VERSION "dbc-export 1 2026.26.6.5"

NS_ :

BS_:

BU_: APP BMS CC CMP CMPD CP DAS DI DIF DIR EPBL EPBR EVSE FC GTW HCML HCMR HVP ICR PCS PCS2 PM PMF PMR PTC SCCM SDCR TAS UMC V2G VC VCBATT VCBATT1 VCBATT2 VCFRONT VCFRONT1 VCLEFT VCRIGHT VCSEC

BO_ 769 VCFRONT_info: 8 VCFRONT
 SG_ VCFRONT_infoIndex M : 0|8@1+ (1,0) [0|255] "" Vector__XXX
 SG_ VCFRONT_infoBuildType m10 : 8|3@1+ (1,0) [0|7] "" Vector__XXX
 SG_ VCFRONT_infoBuildConfigId m10 : 16|16@1+ (1,0) [0|65535] "" Vector__XXX
 SG_ VCFRONT_infoHardwareId m10 : 32|16@1+ (1,0) [0|65535] "" Vector__XXX
 SG_ VCFRONT_infoComponentId m10 : 48|16@1+ (1,0) [0|65535] "" Vector__XXX
 SG_ VCFRONT_infoPcbaId m11 : 8|8@1+ (1,0) [0|255] "" Vector__XXX
 SG_ VCFRONT_infoAssemblyId m11 : 16|8@1+ (1,0) [0|254] "" Vector__XXX
 SG_ VCFRONT_infoUsageId m11 : 24|16@1+ (1,0) [0|65535] "" Vector__XXX
 SG_ VCFRONT_infoSubUsageId m11 : 40|16@1+ (1,0) [0|65535] "" Vector__XXX
 SG_ VCFRONT_infoAppCrc m13 : 8|32@1+ (1,0) [0|4294967295] "" Vector__XXX
 SG_ VC_infoHCMLAppCRC m16 : 32|32@1+ (1,0) [0|4294967295] "" Vector__XXX
 SG_ VCFRONT_infoAppGitHash m17 : 8|56@1+ (1,0) [0|7.20575940379e+16] "" Vector__XXX
 SG_ VCFRONT_infoBootGitHash m18 : 8|56@1+ (1,0) [0|7.20575940379e+16] "" Vector__XXX
 SG_ VCFRONT_infoPlatformType m19 : 8|8@1+ (1,0) [0|255] "" Vector__XXX
 SG_ VCFRONT_infoBootUdsProtoVersion m20 : 8|16@1+ (1,0) [0|65535] "" Vector__XXX
 SG_ VCFRONT_infoBootCrc m20 : 24|32@1+ (1,0) [0|4294967295] "" Vector__XXX
 SG_ VC_infoHCMRAppCRC m23 : 32|32@1+ (1,0) [0|4294967295] "" Vector__XXX
 SG_ VC_infoWiperAppCRC m31 : 32|32@1+ (1,0) [0|4294967295] "" Vector__XXX

BO_ 1014 VCFRONT_lightStatus: 8 VCFRONT
 SG_ VCFRONT_lowBeamLeftStatus : 0|2@1+ (1,0) [0|2] "" Vector__XXX
 SG_ VCFRONT_lowBeamRightStatus : 2|2@1+ (1,0) [0|2] "" Vector__XXX
 SG_ VCFRONT_highBeamLeftStatus : 4|2@1+ (1,0) [0|2] "" Vector__XXX
 SG_ VCFRONT_highBeamRightStatus : 6|2@1+ (1,0) [0|2] "" Vector__XXX
 SG_ VCFRONT_DRLLeftStatus : 8|2@1+ (1,0) [0|2] "" Vector__XXX
 SG_ VCFRONT_DRLRightStatus : 10|2@1+ (1,0) [0|2] "" Vector__XXX
 SG_ VCFRONT_fogLeftStatus : 12|2@1+ (1,0) [0|2] "" Vector__XXX
 SG_ VCFRONT_fogRightStatus : 14|2@1+ (1,0) [0|2] "" Vector__XXX
 SG_ VCFRONT_sideMarkersStatus : 16|2@1+ (1,0) [0|2] "" Vector__XXX
 SG_ VCFRONT_sideRepeaterLeftStatus : 18|2@1+ (1,0) [0|2] "" Vector__XXX
 SG_ VCFRONT_sideRepeaterRightStatus : 20|2@1+ (1,0) [0|2] "" Vector__XXX
 SG_ VCFRONT_turnSignalLeftStatus : 22|2@1+ (1,0) [0|2] "" Vector__XXX
 SG_ VCFRONT_turnSignalRightStatus : 24|2@1+ (1,0) [0|2] "" Vector__XXX
 SG_ VCFRONT_parkLeftStatus : 26|2@1+ (1,0) [0|2] "" Vector__XXX
 SG_ VCFRONT_parkRightStatus : 28|2@1+ (1,0) [0|2] "" Vector__XXX
 SG_ VCFRONT_lowBeamLeftReadyForAimin : 30|1@1+ (1,0) [0|1] "" Vector__XXX
 SG_ VCFRONT_lowBeamRightReadyForAimi : 31|1@1+ (1,0) [0|1] "" Vector__XXX
 SG_ VCFRONT_lowBeamsOnForDRL : 32|1@1+ (1,0) [0|1] "" Vector__XXX
 SG_ VC_rightHeadlampHealth : 33|3@1+ (1,0) [0|7] "" Vector__XXX
 SG_ VC_leftHeadlampHealth : 36|3@1+ (1,0) [0|7] "" Vector__XXX
 SG_ VCFRONT_lightStatusMuxIndex M : 39|3@1+ (1,0) [0|7] "" Vector__XXX
 SG_ VCFRONT_isAdaptiveHighBeamAvaila m1 : 42|1@1+ (1,0) [0|1] "" Vector__XXX
 SG_ VCFRONT_isAdaptiveHighBeamFaulte m1 : 43|1@1+ (1,0) [0|1] "" Vector__XXX
 SG_ VCFRONT_isBendLightingAvailable m1 : 44|1@1+ (1,0) [0|1] "" Vector__XXX
 SG_ VCFRONT_advancedDrivingBeamStatu m1 : 45|2@1+ (1,0) [0|3] "" Vector__XXX
 SG_ VCFRONT_headlampBendAngle m1 : 47|8@1- (0.1,0) [-12.7|12.7] "deg" Vector__XXX
 SG_ VCFRONT_headlampRoadClass m1 : 55|2@1+ (1,0) [0|3] "" Vector__XXX

BO_ 1013 VCFRONT_lighting: 8 VCFRONT
 SG_ VCFRONT_indicatorLeftRequest : 0|2@1+ (1,0) [0|3] "" Vector__XXX
 SG_ VCFRONT_indicatorRightRequest : 2|2@1+ (1,0) [0|3] "" Vector__XXX
 SG_ VCFRONT_hazardLightRequest : 4|4@1+ (1,0) [0|15] "" Vector__XXX
 SG_ VCFRONT_ambientLightingBrightnes : 8|8@1+ (0.5,0) [0|127] "%" Vector__XXX
 SG_ VCFRONT_switchLightingBrightness : 16|8@1+ (0.5,0) [0|127] "%" Vector__XXX
 SG_ VCFRONT_courtesyLightingRequest : 24|1@1+ (1,0) [0|1] "" Vector__XXX
 SG_ VCFRONT_hazardSwitchBacklight : 27|1@1+ (1,0) [0|1] "" Vector__XXX
 SG_ VCFRONT_highBeamControlState : 28|2@1+ (1,0) [0|3] "" Vector__XXX
 SG_ VCFRONT_dynamicBrakeLightState : 30|2@1+ (1,0) [0|3] "" Vector__XXX
 SG_ VCFRONT_lightingCoreState : 32|4@1+ (1,0) [0|14] "" Vector__XXX
 SG_ VCFRONT_intHighBeamsFunctionStat : 36|1@1+ (1,0) [0|1] "" Vector__XXX
 SG_ VCFRONT_latchedHighBeamsFunction : 37|1@1+ (1,0) [0|1] "" Vector__XXX
 SG_ VCFRONT_frontFogFunctionState : 38|1@1+ (1,0) [0|1] "" Vector__XXX
 SG_ VCFRONT_headlightsReadyOrTimedOu : 39|1@1+ (1,0) [0|1] "" Vector__XXX
 SG_ VCFRONT_turnIndicatorStalk : 40|2@1+ (1,0) [0|2] "" Vector__XXX
 SG_ VCFRONT_highBeamLatchingState : 42|2@1+ (1,0) [1|3] "" Vector__XXX
 SG_ VCFRONT_lightingCustomState : 44|5@1+ (1,0) [0|31] "" Vector__XXX
 SG_ VC_fastFlashHazardsActive : 49|1@1+ (1,0) [0|1] "" Vector__XXX
 SG_ VCFRONT_indicatorLeftInternal : 50|2@1+ (1,0) [0|3] "" Vector__XXX
 SG_ VCFRONT_indicatorRightInternal : 52|2@1+ (1,0) [0|3] "" Vector__XXX

BO_ 1801 VCFRONT_logging0point1Hz: 8 VCFRONT
 SG_ VCFRONT_logging0point1HzIndex M : 0|6@1+ (1,0) [0|63] "" Vector__XXX
 SG_ VC_hcmlFactoryOfOrigin m26 : 6|2@1+ (1,0) [0|3] "" Vector__XXX
 SG_ VC_hcmlHellaPartNumberStatus m26 : 8|1@1+ (1,0) [0|1] "" Vector__XXX
 SG_ VC_hcmlHellaPartNumber m26 : 9|32@1+ (1,0) [0|4294967295] "-" Vector__XXX
 SG_ VC_hcmlCurrentBinMappingType m26 : 41|2@1+ (1,0) [0|3] "" Vector__XXX
 SG_ VC_hcmlCurrentBin0Value m26 : 43|3@1+ (1,0) [1|7] "" Vector__XXX
 SG_ VC_hcmlCurrentBin1Value m26 : 46|3@1+ (1,0) [1|7] "" Vector__XXX
 SG_ VC_hcmlCurrentBin2Value m26 : 49|3@1+ (1,0) [1|7] "" Vector__XXX
 SG_ VC_hcmlCurrentBin3Value m26 : 52|3@1+ (1,0) [1|7] "" Vector__XXX
 SG_ VC_hcmlCurrentBin4Value m26 : 55|3@1+ (1,0) [1|7] "" Vector__XXX
 SG_ VC_hcmlCurrentBin5Value m26 : 58|3@1+ (1,0) [1|7] "" Vector__XXX
 SG_ VC_hcmlRegionAndSide m26 : 61|3@1+ (1,0) [1|7] "" Vector__XXX
 SG_ VC_hcmrFactoryOfOrigin m27 : 6|2@1+ (1,0) [0|3] "" Vector__XXX
 SG_ VC_hcmrHellaPartNumberStatus m27 : 8|1@1+ (1,0) [0|1] "" Vector__XXX
 SG_ VC_hcmrHellaPartNumber m27 : 9|32@1+ (1,0) [0|4294967295] "-" Vector__XXX
 SG_ VC_hcmrCurrentBinMappingType m27 : 41|2@1+ (1,0) [0|3] "" Vector__XXX
 SG_ VC_hcmrCurrentBin0Value m27 : 43|3@1+ (1,0) [1|7] "" Vector__XXX
 SG_ VC_hcmrCurrentBin1Value m27 : 46|3@1+ (1,0) [1|7] "" Vector__XXX
 SG_ VC_hcmrCurrentBin2Value m27 : 49|3@1+ (1,0) [1|7] "" Vector__XXX
 SG_ VC_hcmrCurrentBin3Value m27 : 52|3@1+ (1,0) [1|7] "" Vector__XXX
 SG_ VC_hcmrCurrentBin4Value m27 : 55|3@1+ (1,0) [1|7] "" Vector__XXX
 SG_ VC_hcmrCurrentBin5Value m27 : 58|3@1+ (1,0) [1|7] "" Vector__XXX
 SG_ VC_hcmrRegionAndSide m27 : 61|3@1+ (1,0) [1|7] "" Vector__XXX

BO_ 705 VCFRONT_logging10Hz: 8 VCFRONT
 SG_ VCFRONT_logging10HzIndex M : 0|3@1+ (1,0) [0|7] "" Vector__XXX
 SG_ VCFRONT_pumpBatteryOutVoltage m0 : 3|7@1+ (0.2,0) [0|20] "V" Vector__XXX
 SG_ VCFRONT_pumpPowertrainOutVoltage m0 : 10|7@1+ (0.2,0) [0|20] "V" Vector__XXX
 SG_ VCFRONT_pumpBatteryInitd m0 : 17|1@1+ (1,0) [0|1] "" Vector__XXX
 SG_ VCFRONT_pumpPowertrainInitd m0 : 18|1@1+ (1,0) [0|1] "" Vector__XXX
 SG_ VCFRONT_pumpBatteryEnabled m0 : 19|1@1+ (1,0) [0|1] "" Vector__XXX
 SG_ VCFRONT_pumpPowertrainEnabled m0 : 20|1@1+ (1,0) [0|1] "" Vector__XXX
 SG_ VCFRONT_pumpBatteryPowerOn m0 : 21|1@1+ (1,0) [0|1] "" Vector__XXX
 SG_ VCFRONT_pumpPowertrainPowerOn m0 : 22|1@1+ (1,0) [0|1] "" Vector__XXX
 SG_ VCFRONT_pumpsWake m0 : 23|1@1+ (1,0) [0|1] "" Vector__XXX
 SG_ VCFRONT_pumpBatSpiError m0 : 24|1@1+ (1,0) [0|1] "" Vector__XXX
 SG_ VCFRONT_pumpPtSpiError m0 : 25|1@1+ (1,0) [0|1] "" Vector__XXX
 SG_ VCFRONT_coolantFlowChillerActual m0 : 26|8@1+ (0.1,0) [0|25] "LPM" Vector__XXX
 SG_ VCFRONT_radiatorFanOutVoltage m0 : 34|7@1+ (0.2,0) [0|20] "V" Vector__XXX
 SG_ VCFRONT_radiatorFanInitd m0 : 41|1@1+ (1,0) [0|1] "" Vector__XXX
 SG_ VCFRONT_radiatorFanEnabled m0 : 42|1@1+ (1,0) [0|1] "" Vector__XXX
 SG_ VCFRONT_radiatorFanPowerOn m0 : 43|1@1+ (1,0) [0|1] "" Vector__XXX
 SG_ VCFRONT_radiatorFanPhaseCurrent m0 : 44|8@1+ (0.25,-10) [-10|50] "A" Vector__XXX
 SG_ VCFRONT_radiatorFanPhaseIMax m0 : 52|7@1+ (0.25,5) [5|35] "A" Vector__XXX
 SG_ VCFRONT_thmlFanSpiError m0 : 59|1@1+ (1,0) [0|1] "" Vector__XXX
 SG_ VCFRONT_chargeTrapNominalCOP1Bat m0 : 60|1@1+ (1,0) [0|1] "" Vector__XXX
 SG_ VCFRONT_chargeTrapNominalCOP1Chi m0 : 61|1@1+ (1,0) [0|1] "" Vector__XXX
 SG_ VCFRONT_COP1OilWarmingNeeded m0 : 62|1@1+ (1,0) [0|1] "" Vector__XXX

BO_ 897 VCFRONT_logging1Hz: 8 VCFRONT
 SG_ VCFRONT_logging1HzIndex M : 0|5@1+ (1,0) [0|31] "" Vector__XXX
 SG_ VCFRONT_modeTransitionID m0 : 5|6@1+ (1,0) [0|63] "" Vector__XXX
 SG_ VCFRONT_modeDesired m0 : 11|2@1+ (1,0) [0|3] "" Vector__XXX
 SG_ VCFRONT_targetPTActiveCool m0 : 13|7@1+ (1,0) [0|100] "degC" Vector__XXX
 SG_ VCFRONT_targetPtOptionalActiveCo m0 : 20|7@1+ (1,0) [0|100] "degC" Vector__XXX
 SG_ VCFRONT_targetPTPassive m0 : 27|7@1+ (1,-20) [-20|80] "degC" Vector__XXX
 SG_ VCFRONT_targetBatActiveCool m0 : 34|7@1+ (1,0) [0|100] "degC" Vector__XXX
 SG_ VCFRONT_targetBatOptionalActiveC m0 : 41|7@1+ (1,0) [0|100] "degC" Vector__XXX
 SG_ VCFRONT_targetBatPassive m0 : 48|7@1+ (1,-20) [-20|80] "degC" Vector__XXX
 SG_ VCFRONT_targetBatActiveHeat m0 : 55|7@1+ (1,-40) [-40|60] "degC" Vector__XXX
 SG_ VCFRONT_condenserPressureLimit m1 : 5|6@1+ (0.16,10) [10|20] "bar" Vector__XXX
 SG_ VCFRONT_fanDemandCondenser m1 : 11|7@1+ (1,0) [0|100] "%" Vector__XXX
 SG_ VCFRONT_fanDemandRadiator m1 : 18|7@1+ (1,0) [0|100] "%" Vector__XXX
 SG_ VCFRONT_tempRefrigSuction m1 : 25|8@1+ (0.5,-40) [-40|85] "degC" Vector__XXX
 SG_ VCFRONT_pumpBatteryFETTemp m1 : 33|8@1+ (1,-40) [-40|150] "degC" Vector__XXX
 SG_ VCFRONT_pumpPowertrainFETTemp m1 : 41|8@1+ (1,-40) [-40|150] "degC" Vector__XXX
 SG_ VCFRONT_radiatorFanFETTemp m1 : 49|8@1+ (1,-40) [-40|150] "degC" Vector__XXX
 SG_ VCFRONT_radiatorFanRunReason m1 : 57|4@1+ (1,0) [0|15] "" Vector__XXX
 SG_ VCFRONT_coolantValveModeWrong m1 : 61|1@1+ (1,0) [0|1] "" Vector__XXX
 SG_ VCFRONT_coolantTempBasedMode m1 : 62|2@1+ (1,0) [0|3] "" Vector__XXX
 SG_ VCFRONT_coolantValveRecalReason m2 : 5|3@1+ (1,0) [0|7] "" Vector__XXX
 SG_ VCFRONT_coolantValveCountRange m2 : 8|10@1+ (1,375) [375|1375] "ticks" Vector__XXX
 SG_ VCFRONT_coolantValveAngleDrift m2 : 18|10@1+ (0.25,-127) [-127|127] "degrees" Vector__XXX
 SG_ VCFRONT_coolantValveRecalCount m2 : 28|16@1+ (1,0) [0|65535] "" Vector__XXX
 SG_ VCFRONT_coolantValveWindupEst m2 : 44|6@1+ (2,0) [0|126] "ticks" Vector__XXX
 SG_ VCFRONT_coolantValveRadBypass m2 : 50|7@1+ (1,0) [0|100] "%" Vector__XXX
 SG_ VCFRONT_usingModeledPs m2 : 57|1@1+ (1,0) [0|1] "" Vector__XXX
 SG_ VCFRONT_usingModeledPd m2 : 58|1@1+ (1,0) [0|1] "" Vector__XXX
 SG_ VCFRONT_usingModeledPl m2 : 59|1@1+ (1,0) [0|1] "" Vector__XXX
 SG_ VCFRONT_usingModeledTs m2 : 60|1@1+ (1,0) [0|1] "" Vector__XXX
 SG_ VCFRONT_usingModeledTd m2 : 61|1@1+ (1,0) [0|1] "" Vector__XXX
 SG_ VCFRONT_usingModeledTl m2 : 62|1@1+ (1,0) [0|1] "" Vector__XXX
 SG_ VCFRONT_hpChargeCableType m5 : 5|2@1+ (1,0) [0|3] "" Vector__XXX
 SG_ VCFRONT_subcoolActual m5 : 8|7@1- (0.4,15.2) [-10|40] "degC" Vector__XXX
 SG_ VCFRONT_hpSubcoolTarget m5 : 16|5@1+ (1,0) [0|31] "degC" Vector__XXX
 SG_ VCFRONT_CMPDischargeSuperheat m5 : 21|5@1- (1,6) [-10|21] "degC" Vector__XXX
 SG_ VCFRONT_hpCOP m5 : 26|6@1+ (0.1,0) [0|6] "-" Vector__XXX
 SG_ VCFRONT_lowSideWattsLift m5 : 32|7@1+ (60,0) [0|7600] "W" Vector__XXX
 SG_ VCFRONT_tempSuperheatActual m5 : 39|10@1+ (0.1,-20) [-20|80] "degC" Vector__XXX
 SG_ VCFRONT_tempSuperheatTarget m5 : 49|10@1+ (0.1,0) [0|60] "degC" Vector__XXX
 SG_ VCFRONT_refrigerantHasBeenFilled m5 : 59|1@1+ (1,0) [0|1] "" Vector__XXX
 SG_ VCFRONT_refCommissionStatus m5 : 60|2@1+ (1,0) [0|3] "" Vector__XXX
 SG_ VCFRONT_LCCPurgeActive m5 : 62|1@1+ (1,0) [0|1] "" Vector__XXX
 SG_ VCFRONT_exteriorQuietModeEnabled m6 : 5|1@1+ (1,0) [0|1] "" Vector__XXX
 SG_ VCFRONT_exteriorQuietModeAllowed m6 : 6|1@1+ (1,0) [0|1] "" Vector__XXX
 SG_ VCFRONT_CCQdotFdFrwrdTarget m6 : 7|7@1+ (80,0) [0|10100] "W" Vector__XXX
 SG_ VCFRONT_CCQdotFdbk m6 : 14|7@1- (80,0) [-5000|5000] "W" Vector__XXX
 SG_ VCFRONT_CCQdotActual m6 : 21|7@1+ (80,0) [0|10100] "W" Vector__XXX
 SG_ VCFRONT_evapFdFrwrdTarget m6 : 28|7@1+ (80,0) [0|10100] "W" Vector__XXX
 SG_ VCFRONT_evapFdbk m6 : 35|7@1- (100,-3300) [-9700|3000] "W" Vector__XXX
 SG_ VCFRONT_DIQdotA m6 : 42|7@1+ (80,0) [0|10000] "W" Vector__XXX
 SG_ VCFRONT_evapFdFrwrdTargetMinimum m6 : 49|7@1+ (80,0) [0|10000] "W" Vector__XXX
 SG_ VCFRONT_passiveCoolingState m6 : 56|2@1+ (1,0) [0|3] "" Vector__XXX
 SG_ VCFRONT_totalLoadCoolingDominant m6 : 58|1@1+ (1,0) [0|1] "" Vector__XXX
 SG_ VCFRONT_feedfwdLoadCoolingDomina m6 : 59|1@1+ (1,0) [0|1] "" Vector__XXX
 SG_ VCFRONT_modelLoadCoolingDominant m6 : 60|1@1+ (1,0) [0|1] "" Vector__XXX
 SG_ VCFRONT_hpPotentialLowRefrig m6 : 61|1@1+ (1,0) [0|1] "" Vector__XXX
 SG_ VCFRONT_hpRefrigerantPurgeState m6 : 62|2@1+ (1,0) [0|3] "" Vector__XXX
 SG_ VCFRONT_estPressureLiq m7 : 5|6@1+ (0.5,0) [0|31] "bar" Vector__XXX
 SG_ VCFRONT_estPressureSuct m7 : 11|7@1+ (0.125,0) [0|11.5] "bar" Vector__XXX
 SG_ VCFRONT_estPressureDisch m7 : 18|7@1+ (0.25,0) [0|31.75] "bar" Vector__XXX
 SG_ VCFRONT_estTempLiq m7 : 25|8@1- (0.8,68.8) [-33|170] "degC" Vector__XXX
 SG_ VCFRONT_estTempSuct m7 : 33|6@1- (1,2) [-30|33] "degC" Vector__XXX
 SG_ VCFRONT_estTempDisch m7 : 39|7@1- (1.5,75) [-20|169] "degC" Vector__XXX
 SG_ VCFRONT_estCompressorRpm m7 : 46|9@1+ (30,0) [0|15000] "rpm" Vector__XXX
 SG_ VCFRONT_estQLift m7 : 55|6@1+ (100,0) [0|6300] "W" Vector__XXX
 SG_ VCFRONT_cycleModelConverged m7 : 61|1@1+ (1,0) [0|1] "" Vector__XXX
 SG_ VCFRONT_compStandbyCoastDownMode m7 : 62|1@1+ (1,0) [0|1] "" Vector__XXX
 SG_ VCFRONT_compStandbyShowroomMode m7 : 63|1@1+ (1,0) [0|1] "" Vector__XXX
 SG_ VCFRONT_chillerExvCalibOffset m8 : 5|5@1- (8,0) [-127|120] "ticks" Vector__XXX
 SG_ VCFRONT_evapExvCalibOffset m8 : 10|5@1- (8,0) [-127|120] "ticks" Vector__XXX
 SG_ VCFRONT_recircExvCalibOffset m8 : 15|5@1- (8,0) [-127|120] "ticks" Vector__XXX
 SG_ VCFRONT_lccExvCalibOffset m8 : 20|5@1- (8,0) [-127|120] "ticks" Vector__XXX
 SG_ VCFRONT_ccLeftExvCalibOffset m8 : 25|5@1- (8,0) [-127|120] "ticks" Vector__XXX
 SG_ VCFRONT_ccRightExvCalibOffset m8 : 30|5@1- (8,0) [-127|120] "ticks" Vector__XXX
 SG_ VCFRONT_chillerEXVControlState m8 : 35|3@1+ (1,0) [0|7] "" Vector__XXX
 SG_ VCFRONT_evapEXVControlState m8 : 38|3@1+ (1,0) [0|7] "" Vector__XXX
 SG_ VCFRONT_recircEXVControlState m8 : 41|3@1+ (1,0) [0|7] "" Vector__XXX
 SG_ VCFRONT_lccEXVControlState m8 : 44|3@1+ (1,0) [0|7] "" Vector__XXX
 SG_ VCFRONT_cclEXVControlState m8 : 47|3@1+ (1,0) [0|7] "" Vector__XXX
 SG_ VCFRONT_ccrEXVControlState m8 : 50|3@1+ (1,0) [0|7] "" Vector__XXX
 SG_ VCFRONT_chillerExvCalibFailed m8 : 53|1@1+ (1,0) [0|1] "" Vector__XXX
 SG_ VCFRONT_evapExvCalibFailed m8 : 54|1@1+ (1,0) [0|1] "" Vector__XXX
 SG_ VCFRONT_recircExvCalibFailed m8 : 55|1@1+ (1,0) [0|1] "" Vector__XXX
 SG_ VCFRONT_lccExvCalibFailed m8 : 56|1@1+ (1,0) [0|1] "" Vector__XXX
 SG_ VCFRONT_ccLeftExvCalibFailed m8 : 57|1@1+ (1,0) [0|1] "" Vector__XXX
 SG_ VCFRONT_ccRightExvCalibFailed m8 : 58|1@1+ (1,0) [0|1] "" Vector__XXX
 SG_ VCFRONT_ambientTempSniffActive m8 : 59|1@1+ (1,0) [0|1] "" Vector__XXX
 SG_ VCFRONT_ambientTempPassiveSniffi m8 : 60|1@1+ (1,0) [0|1] "" Vector__XXX
 SG_ VCFRONT_ambientTempRadSampling m8 : 61|1@1+ (1,0) [0|1] "" Vector__XXX
 SG_ VCFRONT_ambientTempSpeedSampling m8 : 62|1@1+ (1,0) [0|1] "" Vector__XXX
 SG_ VCFRONT_feedFwdMDotEvaporator m12 : 5|8@1+ (0.005,0) [0|1] "-" Vector__XXX
 SG_ VCFRONT_hpCabinHeatBatteryHeatAm m12 : 13|1@1+ (1,0) [0|1] "" Vector__XXX
 SG_ VCFRONT_hpCabinHeatBatteryHeatCO m12 : 14|1@1+ (1,0) [0|1] "" Vector__XXX
 SG_ VCFRONT_feedFwdMDotCabinCondense m12 : 15|8@1+ (0.005,0) [0|1] "-" Vector__XXX
 SG_ VCFRONT_feedBackEvapTempControll m12 : 23|7@1+ (0.01,-0.5) [-0.5|0.5] "-" Vector__XXX
 SG_ VCFRONT_feedBackDuctTempControll m12 : 30|8@1+ (0.01,-1) [-1|1] "-" Vector__XXX
 SG_ VCFRONT_isSolenoidAllowed m12 : 38|1@1+ (1,0) [0|1] "" Vector__XXX
 SG_ VCFRONT_maxChillerCoolingPower m12 : 39|8@1+ (100,0) [0|20000] "W" Vector__XXX
 SG_ VCFRONT_fanControlRadCanCool m12 : 47|1@1+ (1,0) [0|1] "" Vector__XXX
 SG_ VCFRONT_fanControlFeedfwdActive m12 : 48|1@1+ (1,0) [0|1] "" Vector__XXX
 SG_ VCFRONT_fanControlRadiatorUa m12 : 49|7@1+ (8,0) [0|1000] "W/C" Vector__XXX
 SG_ VCFRONT_fanControlRadiatorInletT m12 : 56|6@1- (1.8,36) [-20|90] "C" Vector__XXX
 SG_ VCFRONT_hpASBatteryHeatingAllowe m14 : 5|1@1+ (1,0) [0|1] "" Vector__XXX
 SG_ VCFRONT_hpCOP1BatteryHeatingAllo m14 : 6|1@1+ (1,0) [0|1] "" Vector__XXX
 SG_ VCFRONT_hpCabinHeatScavengeOnly m14 : 7|1@1+ (1,0) [0|1] "" Vector__XXX
 SG_ VCFRONT_hpCabinHeatAmbientSource m14 : 8|1@1+ (1,0) [0|1] "" Vector__XXX
 SG_ VCFRONT_hpCabinHeatReheatScaveng m14 : 9|1@1+ (1,0) [0|1] "" Vector__XXX
 SG_ VCFRONT_hpCabinHeatReheatAmbient m14 : 10|1@1+ (1,0) [0|1] "" Vector__XXX
 SG_ VCFRONT_hpCabinHeatBlend m14 : 11|1@1+ (1,0) [0|1] "" Vector__XXX
 SG_ VCFRONT_hpCabinHeatCOP1 m14 : 12|1@1+ (1,0) [0|1] "" Vector__XXX
 SG_ VCFRONT_hpCabinHeatBatteryHeatRe m14 : 13|1@1+ (1,0) [0|1] "" Vector__XXX
 SG_ VCFRONT_hpCabinHeatBatteryCoolRe m14 : 14|1@1+ (1,0) [0|1] "" Vector__XXX
 SG_ VCFRONT_hpCabinCoolEvaporator m14 : 15|1@1+ (1,0) [0|1] "" Vector__XXX
 SG_ VCFRONT_hpCabinCoolEvaporatorReh m14 : 16|1@1+ (1,0) [0|1] "" Vector__XXX
 SG_ VCFRONT_hpBatteryHeatAmbientSour m14 : 17|1@1+ (1,0) [0|1] "" Vector__XXX
 SG_ VCFRONT_hpBatteryHeatCOP1 m14 : 18|1@1+ (1,0) [0|1] "" Vector__XXX
 SG_ VCFRONT_hpBatteryCool m14 : 19|1@1+ (1,0) [0|1] "" Vector__XXX
 SG_ VCFRONT_hpBatteryCoolCabinConden m14 : 20|1@1+ (1,0) [0|1] "" Vector__XXX
 SG_ VCFRONT_hpBatteryCoolCabinC_0001 m14 : 21|1@1+ (1,0) [0|1] "" Vector__XXX
 SG_ VCFRONT_hpBatteryCoolCabinReheat m14 : 22|1@1+ (1,0) [0|1] "" Vector__XXX
 SG_ VCFRONT_hpBatteryCoolEvaporator m14 : 23|1@1+ (1,0) [0|1] "" Vector__XXX
 SG_ VCFRONT_suctionSuperheatEstTsSNA m14 : 24|4@1+ (2,0) [0|30] "degC" Vector__XXX
 SG_ VCFRONT_tempRefrigSuctionEst m14 : 28|6@1- (1.2,7.2) [-25|37.2] "degC" Vector__XXX
 SG_ VCFRONT_hpBattOverTempHvacDisabl m14 : 34|1@1+ (1,0) [0|1] "" Vector__XXX
 SG_ VCFRONT_hpDiagLouverCalib m14 : 35|1@1+ (1,0) [0|1] "" Vector__XXX
 SG_ VCFRONT_hpDiagHighSideNotNominal m14 : 36|1@1+ (1,0) [0|1] "" Vector__XXX
 SG_ VCFRONT_hpForceModeRadClear m14 : 37|1@1+ (1,0) [0|1] "" Vector__XXX
 SG_ VCFRONT_estPressureDischargeSat m14 : 38|7@1+ (0.25,0) [0|31.75] "bar" Vector__XXX
 SG_ VCFRONT_tempRefrigLiquid m14 : 45|11@1+ (0.125,-40) [-40|150] "degC" Vector__XXX
 SG_ VCFRONT_totalBattHeatingPower m14 : 56|7@1+ (150,0) [0|19050] "W" Vector__XXX
 SG_ VCFRONT_hpPotentialFrozenRadiato m14 : 63|1@1+ (1,0) [0|1] "" Vector__XXX
 SG_ VCFRONT_passiveSeriesRegOn m16 : 5|1@1+ (1,0) [0|1] "" Vector__XXX
 SG_ VCFRONT_passiveDemandRadBypass m16 : 8|7@1+ (1,0) [0|100] "%" Vector__XXX
 SG_ VCFRONT_targetLccActiveCoolCap m16 : 16|7@1+ (1,0) [0|100] "degC" Vector__XXX
 SG_ VCFRONT_targetLccActiveCoolEff m16 : 23|7@1+ (1,0) [0|100] "degC" Vector__XXX
 SG_ VCFRONT_coolantValveDailyAngleTr m16 : 30|7@1+ (60,0) [0|7500] "degrees" Vector__XXX
 SG_ VCFRONT_dischargePressureLimit m16 : 37|7@1+ (0.25,0) [0|26] "bar" Vector__XXX
 SG_ VCFRONT_radMovementBlockActive m16 : 44|1@1+ (1,0) [0|1] "" Vector__XXX
 SG_ VCFRONT_radBypassMoveReason m16 : 45|4@1+ (1,0) [0|15] "" Vector__XXX
 SG_ VCFRONT_hpBattHeatingPower m16 : 49|7@1+ (100,0) [0|10000] "W" Vector__XXX
 SG_ VCFRONT_tempCoolantRadOutletEstS m16 : 56|2@1+ (1,0) [0|3] "" Vector__XXX
 SG_ VCFRONT_targetBatActiveCoolSourc m16 : 58|3@1+ (1,0) [0|7] "" Vector__XXX
 SG_ VCFRONT_targetPTActiveCoolSource m16 : 61|3@1+ (1,0) [0|7] "" Vector__XXX
 SG_ VCFRONT_hpColdStagnationLimit m17 : 8|7@1+ (1,-40) [-40|80] "degC" Vector__XXX
 SG_ VCFRONT_hpHotStagnationLimit m17 : 16|7@1+ (1,-40) [-40|80] "degC" Vector__XXX
 SG_ VCFRONT_hpCompFlowIndex m17 : 23|8@1+ (1,30) [30|255] "-" Vector__XXX
 SG_ VCFRONT_hpCompFlowIndexFiltered m17 : 31|8@1+ (1,30) [30|255] "-" Vector__XXX
 SG_ VCFRONT_subcoolEstTlSNA m17 : 39|6@1- (2,0) [-10|53] "degC" Vector__XXX
 SG_ VCFRONT_subcoolEstPlSNA m17 : 45|6@1- (2,0) [-10|53] "degC" Vector__XXX
 SG_ VCFRONT_tempRefrigLiquidEst m17 : 51|6@1+ (2,0) [0|125] "degC" Vector__XXX
 SG_ VCFRONT_pressureRefrigLiquidEst m17 : 57|6@1+ (0.5,0) [0|31] "bar" Vector__XXX
 SG_ VCFRONT_cmpIsentropicCheckPassed m17 : 63|1@1+ (1,0) [0|1] "" Vector__XXX
 SG_ VCFRONT_louverPosReason m18 : 5|4@1+ (1,0) [0|15] "" Vector__XXX
 SG_ VCFRONT_hpEnergyFlowIndex m18 : 9|8@1+ (4,0) [0|1020] "-" Vector__XXX
 SG_ VCFRONT_hpEnergyFlowIndexFiltere m18 : 17|8@1+ (4,0) [0|1020] "-" Vector__XXX
 SG_ VCFRONT_ductLeftAtSS m18 : 25|1@1+ (1,0) [0|1] "" Vector__XXX
 SG_ VCFRONT_ductRightAtSS m18 : 26|1@1+ (1,0) [0|1] "" Vector__XXX
 SG_ VCFRONT_minCompressorRPMAllowed m18 : 27|7@1+ (90,0) [0|11430] "rpm" Vector__XXX
 SG_ VCFRONT_ccRefrigerantMassFlow m18 : 34|6@1+ (4,0) [0|251] "g/s" Vector__XXX
 SG_ VCFRONT_highSideDpResidual m18 : 40|7@1- (0.1,0) [-6|6] "bar" Vector__XXX
 SG_ VCFRONT_abnormalHighSuctionSuper m18 : 47|1@1+ (1,0) [0|1] "" Vector__XXX
 SG_ VCFRONT_coolantValveAngleTravel m18 : 48|10@1+ (5,0) [0|5000] "degrees" Vector__XXX
 SG_ VCFRONT_chargeShuttleType m18 : 58|2@1+ (1,0) [0|3] "" Vector__XXX
 SG_ VCFRONT_hpRefrigTempSensorCheckC m18 : 60|1@1+ (1,0) [0|1] "" Vector__XXX
 SG_ VCFRONT_hpRefrigPressureSensorCh m18 : 61|1@1+ (1,0) [0|1] "" Vector__XXX
 SG_ VCFRONT_tempSuperheatActFiltered m21 : 8|8@1- (0.25,26.5) [-5|58] "degC" Vector__XXX
 SG_ VCFRONT_tempRefrigDischarge m21 : 16|11@1+ (0.125,-40) [-40|150] "degC" Vector__XXX
 SG_ VCFRONT_pumpBatteryRPMTarget m21 : 27|8@1+ (30,0) [0|7500] "rpm" Vector__XXX
 SG_ VCFRONT_pumpPowertrainRPMTarget m21 : 35|8@1+ (30,0) [0|7500] "rpm" Vector__XXX
 SG_ VCFRONT_coolantFlowChillerTarget m21 : 43|8@1+ (0.161,0) [0|25] "LPM" Vector__XXX
 SG_ VCFRONT_radiatorFanRPMTarget m21 : 51|8@1+ (40,0) [0|10000] "rpm" Vector__XXX
 SG_ VCFRONT_preventReEntryTillNexthp m21 : 59|1@1+ (1,0) [0|1] "" Vector__XXX
 SG_ VCFRONT_chillerBattHeatingPowerA m21 : 60|1@1+ (1,0) [0|1] "" Vector__XXX
 SG_ VCFRONT_isExpectedQChillerVeryHi m21 : 61|1@1+ (1,0) [0|1] "" Vector__XXX
 SG_ VCFRONT_autopilotAirPurgeRoutine m21 : 62|2@1+ (1,0) [0|3] "" Vector__XXX
 SG_ VCFRONT_superheatProtectionLimit m25 : 5|10@1+ (0.1,0) [0|60] "degC" Vector__XXX
 SG_ VCFRONT_chillerDemandWatts m25 : 16|8@1+ (100,0) [0|20000] "W" Vector__XXX
 SG_ VCFRONT_nominalTevapHWLimit m25 : 24|7@1+ (0.5,0) [0|60] "degC" Vector__XXX
 SG_ VCFRONT_battCoolEvapEnableDelay m25 : 31|1@1+ (1,0) [0|1] "" Vector__XXX
 SG_ VCFRONT_ambientTempState m25 : 32|2@1+ (1,0) [0|3] "" Vector__XXX
 SG_ VCFRONT_ambientTempUnlatchReason m25 : 34|3@1+ (1,0) [0|7] "" Vector__XXX
 SG_ VCFRONT_compressorSuctionVaporQu m25 : 40|5@1+ (0.01,0.7) [0.7|1] "-" Vector__XXX
 SG_ VCFRONT_cabinHeatingCOP1MinActiv m25 : 48|7@1+ (10,0) [0|1100] "-" Vector__XXX
 SG_ VCFRONT_hpDuctTargetLeft m26 : 8|7@1+ (1,0) [0|65] "degC" Vector__XXX
 SG_ VCFRONT_hpDuctTargetRight m26 : 16|7@1+ (1,0) [0|65] "degC" Vector__XXX
 SG_ VCFRONT_radiatorUAIndex m26 : 24|8@1+ (1,0) [0|255] "%" Vector__XXX
 SG_ VCFRONT_maxBatInletCoolantTempAl m26 : 32|5@1+ (1,40) [40|65] "degC" Vector__XXX
 SG_ VCFRONT_coolantTempInBypassDelta m26 : 40|5@1+ (1,-20) [-20|11] "degC" Vector__XXX
 SG_ VCFRONT_targetAPPActiveCool m26 : 48|7@1+ (1,0) [0|100] "degC" Vector__XXX

BO_ 513 VCFRONT_loggingAndVitals10Hz: 8 VCFRONT
 SG_ VCFRONT_loggingAndVitals10HzInde M : 0|3@1+ (1,0) [0|7] "" Vector__XXX
 SG_ VCFRONT_pumpBatteryRPMActual m0 : 3|8@1+ (30,0) [0|7500] "rpm" Vector__XXX
 SG_ VCFRONT_pumpPowertrainRPMActual m0 : 11|8@1+ (30,0) [0|7500] "rpm" Vector__XXX
 SG_ VCFRONT_radiatorFanRPMActual m0 : 19|8@1+ (40,0) [0|10000] "rpm" Vector__XXX
 SG_ VCFRONT_exvFlowTarget m0 : 27|8@1+ (0.5,0) [0|100] "%" Vector__XXX
 SG_ VCFRONT_activeLouverOpenPosTarg m0 : 35|7@1+ (1,0) [0|100] "%" Vector__XXX
 SG_ VCFRONT_pressureRefrigLiquid m0 : 42|9@1+ (0.08,0) [0|37.25] "bar" Vector__XXX
 SG_ VCFRONT_compSleepRequest m0 : 51|1@1+ (1,0) [0|1] "" Vector__XXX
 SG_ VCFRONT_thermalHvPowerBudget m0 : 52|7@1+ (0.2,0) [0|25.4] "kW" Vector__XXX
 SG_ VCFRONT_compMinOnTimeActive m0 : 59|1@1+ (1,0) [0|1] "" Vector__XXX
 SG_ VCFRONT_compMinOffTimeActive m0 : 60|1@1+ (1,0) [0|1] "" Vector__XXX
 SG_ VCFRONT_fanDemand m1 : 3|7@1+ (1,0) [0|100] "%" Vector__XXX
 SG_ VCFRONT_compressorState m1 : 10|2@1+ (1,0) [0|3] "" Vector__XXX
 SG_ VCFRONT_compDemandEvap m1 : 12|7@1+ (1,0) [0|100] "%" Vector__XXX
 SG_ VCFRONT_exvState m1 : 19|4@1+ (1,0) [0|15] "" Vector__XXX
 SG_ VCFRONT_solenoidEvapState m1 : 23|2@1+ (1,0) [0|3] "" Vector__XXX
 SG_ VCFRONT_compDemandChiller m1 : 25|7@1+ (1,0) [0|100] "%" Vector__XXX
 SG_ VCFRONT_coolantValveMode m1 : 32|2@1+ (1,0) [0|3] "" Vector__XXX
 SG_ VCFRONT_compFaultSeverity m1 : 34|2@1+ (1,0) [0|3] "" Vector__XXX
 SG_ VCFRONT_solenoidEngaged m1 : 36|1@1+ (1,0) [0|1] "" Vector__XXX
 SG_ VCFRONT_hpHighSideHX m1 : 37|2@1+ (1,0) [0|3] "" Vector__XXX
 SG_ VCFRONT_hpLowSideHX m1 : 39|2@1+ (1,0) [0|3] "" Vector__XXX
 SG_ VCFRONT_hpDominantLoad m1 : 41|3@1+ (1,0) [0|7] "" Vector__XXX
 SG_ VCFRONT_hpBlendType m1 : 44|2@1+ (1,0) [0|3] "" Vector__XXX
 SG_ VCFRONT_hpQuietModeEnabled m1 : 46|1@1+ (1,0) [0|1] "" Vector__XXX
 SG_ VCFRONT_hpCabinLoadType m1 : 47|2@1+ (1,0) [0|3] "" Vector__XXX
 SG_ VCFRONT_hpBatteryLoadType m1 : 49|2@1+ (1,0) [0|3] "" Vector__XXX
 SG_ VCFRONT_hpReqCoolantMode m1 : 51|3@1+ (1,0) [0|7] "" Vector__XXX
 SG_ VCFRONT_hpReqTransScavenge m1 : 54|1@1+ (1,0) [0|1] "" Vector__XXX
 SG_ VCFRONT_compLiqPumpOutState m1 : 55|3@1+ (1,0) [0|7] "" Vector__XXX
 SG_ VCFRONT_frunkStateDBG m1 : 58|4@1+ (1,0) [0|15] "" Vector__XXX
 SG_ VCFRONT_frunkSwitchGroupState m1 : 62|2@1+ (1,0) [0|3] "" Vector__XXX
 SG_ VCFRONT_chillerExvFlow m2 : 3|8@1+ (0.5,0) [0|100] "%" Vector__XXX
 SG_ VCFRONT_evapExvFlow m2 : 11|8@1+ (0.5,0) [0|100] "%" Vector__XXX
 SG_ VCFRONT_recircExvFlow m2 : 19|8@1+ (0.5,0) [0|100] "%" Vector__XXX
 SG_ VCFRONT_lccExvFlow m2 : 27|8@1+ (0.5,0) [0|100] "%" Vector__XXX
 SG_ VCFRONT_cclExvFlow m2 : 35|8@1+ (0.5,0) [0|100] "%" Vector__XXX
 SG_ VCFRONT_ccrExvFlow m2 : 43|8@1+ (0.5,0) [0|100] "%" Vector__XXX
 SG_ VCFRONT_chillerExvState m2 : 51|4@1+ (1,0) [0|15] "" Vector__XXX
 SG_ VCFRONT_evapExvState m2 : 55|4@1+ (1,0) [0|15] "" Vector__XXX
 SG_ VCFRONT_recircExvState m2 : 59|4@1+ (1,0) [0|15] "" Vector__XXX
 SG_ VCFRONT_chillerExvFlowTarget m3 : 3|8@1+ (0.5,0) [0|100] "%" Vector__XXX
 SG_ VCFRONT_evapExvFlowTarget m3 : 11|8@1+ (0.5,0) [0|100] "%" Vector__XXX
 SG_ VCFRONT_recircExvFlowTarget m3 : 19|8@1+ (0.5,0) [0|100] "%" Vector__XXX
 SG_ VCFRONT_lccExvFlowTarget m3 : 27|8@1+ (0.5,0) [0|100] "%" Vector__XXX
 SG_ VCFRONT_cclExvFlowTarget m3 : 35|8@1+ (0.5,0) [0|100] "%" Vector__XXX
 SG_ VCFRONT_ccrExvFlowTarget m3 : 43|8@1+ (0.5,0) [0|100] "%" Vector__XXX
 SG_ VCFRONT_lccExvState m3 : 51|4@1+ (1,0) [0|15] "" Vector__XXX
 SG_ VCFRONT_cclExvState m3 : 55|4@1+ (1,0) [0|15] "" Vector__XXX
 SG_ VCFRONT_ccrExvState m3 : 59|4@1+ (1,0) [0|15] "" Vector__XXX

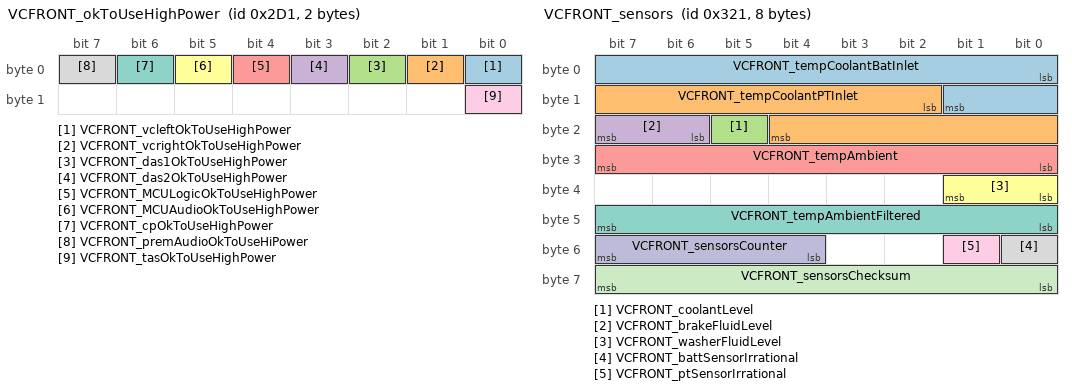
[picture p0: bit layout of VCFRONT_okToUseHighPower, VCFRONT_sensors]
BO_ 721 VCFRONT_okToUseHighPower: 2 VCFRONT
 SG_ VCFRONT_vcleftOkToUseHighPower : 0|1@1+ (1,0) [0|1] "" Vector__XXX
 SG_ VCFRONT_vcrightOkToUseHighPower : 1|1@1+ (1,0) [0|1] "" Vector__XXX
 SG_ VCFRONT_das1OkToUseHighPower : 2|1@1+ (1,0) [0|1] "" Vector__XXX
 SG_ VCFRONT_das2OkToUseHighPower : 3|1@1+ (1,0) [0|1] "" Vector__XXX
 SG_ VCFRONT_MCULogicOkToUseHighPower : 4|1@1+ (1,0) [0|1] "" Vector__XXX
 SG_ VCFRONT_MCUAudioOkToUseHighPower : 5|1@1+ (1,0) [0|1] "" Vector__XXX
 SG_ VCFRONT_cpOkToUseHighPower : 6|1@1+ (1,0) [0|1] "" Vector__XXX
 SG_ VCFRONT_premAudioOkToUseHiPower : 7|1@1+ (1,0) [0|1] "" Vector__XXX
 SG_ VCFRONT_tasOkToUseHighPower : 8|1@1+ (1,0) [0|1] "" Vector__XXX

BO_ 801 VCFRONT_sensors: 8 VCFRONT
 SG_ VCFRONT_tempCoolantBatInlet : 0|10@1+ (0.125,-40) [-40|85] "degC" Vector__XXX
 SG_ VCFRONT_tempCoolantPTInlet : 10|11@1+ (0.125,-40) [-40|200] "degC" Vector__XXX
 SG_ VCFRONT_coolantLevel : 21|1@1+ (1,0) [0|1] "" Vector__XXX
 SG_ VCFRONT_brakeFluidLevel : 22|2@1+ (1,0) [1|3] "" Vector__XXX
 SG_ VCFRONT_tempAmbient : 24|8@1+ (0.5,-40) [-39.5|80] "degC" Vector__XXX
 SG_ VCFRONT_washerFluidLevel : 32|2@1+ (1,0) [1|3] "" Vector__XXX
 SG_ VCFRONT_tempAmbientFiltered : 40|8@1+ (0.5,-40) [-39.5|80] "degC" Vector__XXX
 SG_ VCFRONT_battSensorIrrational : 48|1@1+ (1,0) [0|1] "" Vector__XXX
 SG_ VCFRONT_ptSensorIrrational : 49|1@1+ (1,0) [0|1] "" Vector__XXX
 SG_ VCFRONT_sensorsCounter : 52|4@1+ (1,0) [0|15] "" Vector__XXX
 SG_ VCFRONT_sensorsChecksum : 56|8@1+ (1,0) [0|255] "" Vector__XXX

BO_ 1349 VCFRONT_systemStatus: 8 VCFRONT
 SG_ VCFRONT_systemStatusMuxIndex M : 0|2@1+ (1,0) [0|3] "" Vector__XXX
 SG_ VCFRONT_systemStatusCounter : 52|4@1+ (1,0) [0|15] "" Vector__XXX
 SG_ VCFRONT_systemStatusChecksum : 56|8@1+ (1,0) [0|255] "" Vector__XXX
 SG_ VCFRONT_loadShedReason m1 : 3|9@1+ (1,0) [0|511] "" Vector__XXX
 SG_ VCFRONT_VCRightEFuseLoadShedStag m1 : 12|5@1+ (1,0) [0|31] "" Vector__XXX
 SG_ VCFRONT_VCLeftEFuseLoadShedStage m1 : 20|5@1+ (1,0) [0|31] "" Vector__XXX
 SG_ VCFRONT_DCDCSaturationLoadShedSt m1 : 28|5@1+ (1,0) [0|31] "" Vector__XXX
 SG_ VCFRONT_vehicleLoadShedStage m1 : 36|2@1+ (1,0) [0|3] "" Vector__XXX
 SG_ VCFRONT_HVFaultVehicleLoadShedRe m1 : 38|1@1+ (1,0) [0|1] "" Vector__XXX
 SG_ VCFRONT_postCrashVehicleLoadShed m1 : 39|1@1+ (1,0) [0|1] "" Vector__XXX
 SG_ VCFRONT_HVFaultVehicleLoadShedAc m1 : 40|1@1+ (1,0) [0|1] "" Vector__XXX
 SG_ VCFRONT_factoryVehicleLoadShedAc m1 : 41|1@1+ (1,0) [0|1] "" Vector__XXX
 SG_ VCFRONT_anyVehicleLoadShedActive m1 : 42|1@1+ (1,0) [0|1] "" Vector__XXX
 SG_ VCFRONT_DIVehLoadShedActive m1 : 43|1@1+ (1,0) [0|1] "" Vector__XXX
 SG_ VCFRONT_HVFaultLoadShedStateDBG m1 : 44|2@1+ (1,0) [0|3] "" Vector__XXX
 SG_ VCFRONT_LVUnhealthyVehicleLoadSh m1 : 46|1@1+ (1,0) [0|1] "" Vector__XXX
 SG_ VCFRONT_loadShedStsCondenserFan m2 : 3|1@1+ (1,0) [0|1] "" Vector__XXX
 SG_ VCFRONT_loadShedStsPTPump m2 : 6|1@1+ (1,0) [0|1] "" Vector__XXX
 SG_ VCFRONT_loadShedMCUAudio m2 : 10|1@1+ (1,0) [0|1] "" Vector__XXX
 SG_ VCFRONT_loadShedHVDownTriggerDBG m2 : 11|1@1+ (1,0) [0|1] "" Vector__XXX
 SG_ VCFRONT_loadShedPCSSatTriggerDBG m2 : 12|1@1+ (1,0) [0|1] "" Vector__XXX
 SG_ VCFRONT_loadShedStsBatteryPump m2 : 13|1@1+ (1,0) [0|1] "" Vector__XXX
 SG_ VCFRONT_loadShedStsAPGlassHeater m2 : 14|1@1+ (1,0) [0|1] "" Vector__XXX
 SG_ VCFRONT_loadShedStsMCUGraphics m2 : 15|1@1+ (1,0) [0|1] "" Vector__XXX
 SG_ VCFRONT_IBSCurrentRMS_loadShed m2 : 16|7@1+ (0.05,0) [0|6.35] "A" Vector__XXX
 SG_ VCFRONT_loadShedAhLeakyBktCntDBG m2 : 23|9@1+ (0.001,0) [0|0.511] "Ah" Vector__XXX
 SG_ VCFRONT_loadShedPcs m2 : 33|1@1+ (1,0) [0|1] "" Vector__XXX
 SG_ VCFRONT_loadShedGTWDownstrmRails m2 : 35|1@1+ (1,0) [0|1] "" Vector__XXX
 SG_ VCFRONT_loadShedPCSMIATriggerDBG m2 : 36|1@1+ (1,0) [0|1] "" Vector__XXX
 SG_ VCFRONT_loadShedTAS m2 : 37|1@1+ (1,0) [0|1] "" Vector__XXX
 SG_ VCFRONT_loadShedBackStopBktCntDB m2 : 38|5@1+ (0.05,0) [0|1.55] "Ah" Vector__XXX
 SG_ VCFRONT_loadShedPCSLeakyBktCtDBG m2 : 44|6@1+ (100,0) [0|6300] "mV" Vector__XXX
 SG_ VCFRONT_loadShedUI m2 : 50|1@1+ (1,0) [0|1] "" Vector__XXX
 SG_ VCFRONT_loadShedAutoPilot m2 : 51|1@1+ (1,0) [0|1] "" Vector__XXX

BO_ 929 VCFRONT_vehicleStatus: 8 VCFRONT
 SG_ VCFRONT_vehicleStatusMuxIndex M : 0|1@1+ (1,0) [0|1] "" Vector__XXX
 SG_ VCFRONT_vehicleStatusCounter : 52|4@1+ (1,0) [0|15] "" Vector__XXX
 SG_ VCFRONT_vehicleStatusChecksum : 56|8@1+ (1,0) [0|255] "" Vector__XXX
 SG_ VCFRONT_preconditionRequest m0 : 1|1@1+ (1,0) [0|1] "" Vector__XXX
 SG_ VCFRONT_APGlassHeaterState m0 : 2|3@1+ (1,0) [1|7] "" Vector__XXX
 SG_ VCFRONT_thermalSystemType m0 : 5|1@1+ (1,0) [0|1] "" Vector__XXX
 SG_ VCFRONT_standbySupplySupported m0 : 6|1@1+ (1,0) [0|1] "" Vector__XXX
 SG_ VCFRONT_driverPresent m0 : 7|1@1+ (1,0) [0|1] "" Vector__XXX
 SG_ VCFRONT_passengerPresent m0 : 8|1@1+ (1,0) [0|1] "" Vector__XXX
 SG_ VCFRONT_accPlusAvailable m0 : 9|1@1+ (1,0) [0|1] "" Vector__XXX
 SG_ VCFRONT_diPowerOnState m0 : 10|3@1+ (1,0) [0|7] "" Vector__XXX
 SG_ VCFRONT_12vStatusForDrive m0 : 14|2@1+ (1,0) [0|3] "" Vector__XXX
 SG_ VCFRONT_dcr12VMilliOhms m0 : 16|8@1+ (1,0) [0|255] "mOhm" Vector__XXX
 SG_ VC_userPresenceState m0 : 24|2@1+ (1,0) [0|3] "" Vector__XXX
 SG_ VCFRONT_factoryLimitsOverrideOk m0 : 27|1@1+ (1,0) [0|1] "" Vector__XXX
 SG_ VCFRONT_ota12VSupportRequest m0 : 29|1@1+ (1,0) [0|1] "" Vector__XXX
 SG_ VCFRONT_driverBuckleStatus m0 : 30|1@1+ (1,0) [0|1] "" Vector__XXX
 SG_ VCFRONT_driverDoorStatus m0 : 31|1@1+ (1,0) [0|1] "" Vector__XXX
 SG_ VCFRONT_driverUnbuckled m0 : 32|2@1+ (1,0) [0|3] "" Vector__XXX
 SG_ VCFRONT_passengerUnbuckled m0 : 34|2@1+ (1,0) [0|3] "" Vector__XXX
 SG_ VCFRONT_2RowLeftUnbuckled m0 : 36|2@1+ (1,0) [0|3] "" Vector__XXX
 SG_ VCFRONT_2RowCenterUnbuckled m0 : 38|2@1+ (1,0) [0|3] "" Vector__XXX
 SG_ VCFRONT_2RowRightUnbuckled m0 : 40|2@1+ (1,0) [0|3] "" Vector__XXX
 SG_ VCFRONT_pcsEFuseVoltage m0 : 42|10@1+ (0.1,0) [0|102.2] "V" Vector__XXX
 SG_ VCFRONT_bmsHvChargeEnable m1 : 1|1@1+ (1,0) [0|1] "" Vector__XXX
 SG_ VCFRONT_3RowLeftUnbuckled m1 : 2|2@1+ (1,0) [0|3] "" Vector__XXX
 SG_ VCFRONT_3RowRightUnbuckled m1 : 4|2@1+ (1,0) [0|3] "" Vector__XXX
 SG_ VCFRONT_maxBattHeatRejection m1 : 6|10@1+ (30,0) [0|30690] "W" Vector__XXX
 SG_ VCFRONT_hvacReqBattCoolOutTemp m1 : 16|9@1+ (0.1,40) [40|91.1] "degC" Vector__XXX
 SG_ VCFRONT_PCSCurrent m1 : 25|13@1- (0.1,0) [-409.6|409.5] "A" Vector__XXX
 SG_ VCFRONT_refSystemNominal m1 : 38|1@1+ (1,0) [0|1] "" Vector__XXX
 SG_ VCFRONT_driverEnteredCabinEstima m1 : 39|1@1+ (1,0) [0|1] "" Vector__XXX
 SG_ VCFRONT_anySWEFuseActive m1 : 40|1@1+ (1,0) [0|1] "" Vector__XXX
 SG_ VCFRONT_hpBattHeatingPowerTrgt m1 : 41|7@1+ (100,0) [0|10000] "W" Vector__XXX

BO_ 507 VCLEFT_TLCStatus: 8 VCLEFT
 SG_ VCLEFT_TLCStatusIndex M : 0|2@1+ (1,0) [0|3] "" Vector__XXX
 SG_ VCLEFT_TLCTemperature m1 : 2|8@1- (1,68) [-59|195] "degC" Vector__XXX
 SG_ VCLEFT_TLCLeftTurnVoltage m1 : 10|8@1+ (0.1,0) [0|25.4] "V" Vector__XXX
 SG_ VCLEFT_TLCRightTurnVoltage m1 : 18|8@1+ (0.1,0) [0|25.4] "V" Vector__XXX
 SG_ VCLEFT_TLCState_LeftTurn m1 : 26|3@1+ (1,0) [0|7] "" Vector__XXX
 SG_ VCLEFT_TLCState_RightTurn m1 : 29|3@1+ (1,0) [0|7] "" Vector__XXX
 SG_ VCLEFT_TLCState_Tail m1 : 32|3@1+ (1,0) [0|7] "" Vector__XXX
 SG_ VCLEFT_TLCState_Stop m1 : 35|3@1+ (1,0) [0|7] "" Vector__XXX
 SG_ VCLEFT_TLCState_Fog m1 : 38|3@1+ (1,0) [0|7] "" Vector__XXX
 SG_ VCLEFT_TLCState_Reverse m1 : 41|3@1+ (1,0) [0|7] "" Vector__XXX

BO_ 290 VCLEFT_doorStatus2: 8 VCLEFT
 SG_ VCLEFT_doorStatus2Index M : 0|1@1+ (1,0) [0|1] "" Vector__XXX
 SG_ VCLEFT_frontLatchRelDuty m1 : 8|8@1+ (1,0) [0|255] "%" Vector__XXX
 SG_ VCLEFT_BPillarCameraHeaterState m1 : 16|3@1+ (1,0) [1|7] "" Vector__XXX
 SG_ VCLEFT_doorLatchAjarSwitchVoltag m1 : 24|8@1+ (0.02,0) [0|5] "V" Vector__XXX
 SG_ VCLEFT_doorLatchAjarSwitchV_0001 m1 : 32|8@1+ (0.02,0) [0|5] "V" Vector__XXX
 SG_ VCLEFT_BPillarCameraHeaterCurren m1 : 40|6@1+ (0.02,0) [0|1.24] "A" Vector__XXX
 SG_ VCLEFT_mirrorTiltXOffset m1 : 48|8@1- (0.02,0) [-2.5|2.5] "V" Vector__XXX
 SG_ VCLEFT_mirrorTiltYOffset m1 : 56|8@1- (0.02,0) [-2.5|2.5] "V" Vector__XXX

BO_ 626 VCLEFT_epbmDebug: 8 VCLEFT
 SG_ VCLEFT_epbmDebugIndex M : 0|1@1+ (1,0) [0|1] "" Vector__XXX
 SG_ VCLEFT_epbmCaliperState m0 : 1|3@1+ (1,0) [0|7] "" Vector__XXX
 SG_ VCLEFT_epbmMotorEnabled m0 : 4|1@1+ (1,0) [0|1] "" Vector__XXX
 SG_ VCLEFT_epbMotorCurrent m0 : 5|11@1+ (0.01,0) [0|20.47] "A" Vector__XXX
 SG_ VCLEFT_epbmApplyVoltage m0 : 16|11@1+ (0.01,0) [0|20.47] "A" Vector__XXX
 SG_ VCLEFT_epbmReleaseVoltage m0 : 27|11@1+ (0.01,0) [0|20.47] "A" Vector__XXX
 SG_ VCLEFT_summonFaultReason m0 : 38|5@1+ (1,0) [0|31] "" Vector__XXX
 SG_ VCLEFT_epbSummonState m0 : 43|3@1+ (1,0) [0|7] "" Vector__XXX
 SG_ VCLEFT_epbmSummonState m0 : 46|3@1+ (1,0) [0|7] "" Vector__XXX
 SG_ VCLEFT_epbUnitStatus m0 : 49|5@1+ (1,0) [0|31] "" Vector__XXX
 SG_ VCLEFT_epbmFaultStatus m0 : 54|2@1+ (1,0) [0|3] "" Vector__XXX
 SG_ VCLEFT_epbFaultStatus m0 : 56|2@1+ (1,0) [0|3] "" Vector__XXX
 SG_ VCLEFT_epbmSystemStatus m0 : 58|4@1+ (1,0) [0|15] "" Vector__XXX
 SG_ VCLEFT_epbmAutonomyBehavior m0 : 62|2@1+ (1,0) [0|3] "" Vector__XXX

BO_ 1186 VCLEFT_etcBluetoothStatus: 1 VCLEFT
 SG_ VCLEFT_etcBluetoothStatus : 0|2@1+ (1,0) [0|3] "" Vector__XXX

BO_ 642 VCLEFT_hvacBlowerFeedback: 8 VCLEFT
 SG_ VCLEFT_hvacBlowerFeedbackIndex M : 0|1@1+ (1,0) [0|1] "" Vector__XXX
 SG_ VCLEFT_hvacBlowerEnabled m0 : 2|1@1+ (1,0) [0|1] "" Vector__XXX
 SG_ VCLEFT_hvacBlowerOutputDuty m0 : 3|7@1+ (1,0) [0|100] "%" Vector__XXX
 SG_ VCLEFT_hvacBlowerRPMTarget m0 : 10|10@1+ (10,0) [0|10000] "rpm" Vector__XXX
 SG_ VCLEFT_hvacBlowerRPMActual m0 : 20|10@1+ (10,0) [0|10000] "rpm" Vector__XXX
 SG_ VCLEFT_hvacBlowerTorque m0 : 34|10@1+ (0.006,-1.5) [-1.5|4.5] "Nm" Vector__XXX
 SG_ VCLEFT_hvacBlowerFETTemp m0 : 44|7@1+ (2,-50) [-50|180] "degC" Vector__XXX
 SG_ VCLEFT_hvacBlowerIDc m0 : 51|7@1+ (0.5,0) [0|63] "A" Vector__XXX
 SG_ VCLEFT_hvacBlowerInitd m0 : 58|1@1+ (1,0) [0|1] "" Vector__XXX
 SG_ VCLEFT_hvacBlowerFault m0 : 59|1@1+ (1,0) [0|1] "" Vector__XXX
 SG_ VCLEFT_hvacBlowerLimitFETTemps m0 : 60|1@1+ (1,0) [0|1] "" Vector__XXX
 SG_ VCLEFT_hvacBlowerPowerOn m0 : 61|1@1+ (1,0) [0|1] "" Vector__XXX
 SG_ VCLEFT_hvacBlowerMotorID m0 : 62|2@1+ (1,0) [0|3] "" Vector__XXX

BO_ 770 VCLEFT_info: 8 VCLEFT
 SG_ VCLEFT_infoIndex M : 0|8@1+ (1,0) [0|255] "" Vector__XXX
 SG_ VCLEFT_infoBuildType m10 : 8|3@1+ (1,0) [0|7] "" Vector__XXX
 SG_ VCLEFT_infoBuildConfigId m10 : 16|16@1+ (1,0) [0|65535] "" Vector__XXX
 SG_ VCLEFT_infoHardwareId m10 : 32|16@1+ (1,0) [0|65535] "" Vector__XXX
 SG_ VCLEFT_infoComponentId m10 : 48|16@1+ (1,0) [0|65535] "" Vector__XXX
 SG_ VCLEFT_infoPcbaId m11 : 8|8@1+ (1,0) [0|255] "" Vector__XXX
 SG_ VCLEFT_infoAssemblyId m11 : 16|8@1+ (1,0) [0|254] "" Vector__XXX
 SG_ VCLEFT_infoUsageId m11 : 24|16@1+ (1,0) [0|65535] "" Vector__XXX
 SG_ VCLEFT_infoSubUsageId m11 : 40|16@1+ (1,0) [0|65535] "" Vector__XXX
 SG_ VCLEFT_infoAppCrc m13 : 8|32@1+ (1,0) [0|4294967295] "" Vector__XXX
 SG_ VCLEFT_infoLUMBARLAppCRC m16 : 32|32@1+ (1,0) [0|4294967295] "" Vector__XXX
 SG_ VCLEFT_infoAppGitHash m17 : 8|56@1+ (1,0) [0|7.20575940379e+16] "" Vector__XXX
 SG_ VCLEFT_infoBootGitHash m18 : 8|56@1+ (1,0) [0|7.20575940379e+16] "" Vector__XXX
 SG_ VCLEFT_infoPlatformType m19 : 8|8@1+ (1,0) [0|255] "" Vector__XXX
 SG_ VCLEFT_infoBootUdsProtoVersion m20 : 8|16@1+ (1,0) [0|65535] "" Vector__XXX
 SG_ VCLEFT_infoBootCrc m20 : 24|32@1+ (1,0) [0|4294967295] "" Vector__XXX

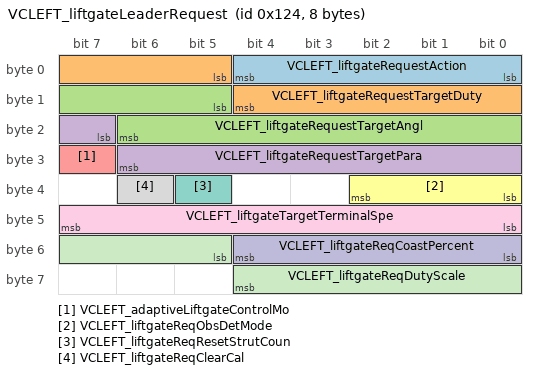
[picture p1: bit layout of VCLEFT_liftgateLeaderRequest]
BO_ 292 VCLEFT_liftgateLeaderRequest: 8 VCLEFT
 SG_ VCLEFT_liftgateRequestAction : 0|5@1+ (1,0) [0|31] "" Vector__XXX
 SG_ VCLEFT_liftgateRequestTargetDuty : 5|8@1- (1,0) [-100|100] "%" Vector__XXX
 SG_ VCLEFT_liftgateRequestTargetAngl : 13|10@1- (0.2,0) [-100|100] "deg" Vector__XXX
 SG_ VCLEFT_liftgateRequestTargetPara : 23|8@1- (1,0) [-100|100] "" Vector__XXX
 SG_ VCLEFT_adaptiveLiftgateControlMo : 31|1@1+ (1,0) [0|1] "" Vector__XXX
 SG_ VCLEFT_liftgateReqObsDetMode : 32|3@1+ (1,0) [0|7] "" Vector__XXX
 SG_ VCLEFT_liftgateReqResetStrutCoun : 37|1@1+ (1,0) [0|1] "" Vector__XXX
 SG_ VCLEFT_liftgateReqClearCal : 38|1@1+ (1,0) [0|1] "" Vector__XXX
 SG_ VCLEFT_liftgateTargetTerminalSpe : 40|8@1- (0.08,10) [0|20] "deg/s" Vector__XXX
 SG_ VCLEFT_liftgateReqCoastPercent : 48|5@1+ (4,0) [0|100] "%" Vector__XXX
 SG_ VCLEFT_liftgateReqDutyScale : 53|8@1+ (0.0125,0) [0|3.15] "-" Vector__XXX

BO_ 322 VCLEFT_liftgateStatus: 8 VCLEFT
 SG_ VCLEFT_liftgateStatusIndex M : 0|2@1+ (1,0) [0|3] "" Vector__XXX
 SG_ VCLEFT_liftgateState m0 : 3|4@1+ (1,0) [0|15] "" Vector__XXX
 SG_ VCLEFT_liftgateStoppingCondition m0 : 10|4@1+ (1,0) [0|15] "" Vector__XXX
 SG_ VCLEFT_liftgateMvmntNotAllowedCo m0 : 14|3@1+ (1,0) [0|7] "" Vector__XXX
 SG_ VCLEFT_liftgatePositionCalibrate m0 : 17|1@1+ (1,0) [0|1] "" Vector__XXX
 SG_ VCLEFT_liftgateUIChimeRequest m0 : 18|3@1+ (1,0) [0|7] "" Vector__XXX
 SG_ VCLEFT_liftgatePhysicalChimeRequ m0 : 21|3@1+ (1,0) [0|7] "" Vector__XXX
 SG_ VCLEFT_liftgateEstimatedStrutTem m0 : 24|8@1+ (1,-60) [-60|195] "C" Vector__XXX
 SG_ VCLEFT_liftgateStaticStrutMode m0 : 32|3@1+ (1,0) [1|7] "" Vector__XXX
 SG_ VCLEFT_liftgateRequestSource m0 : 35|4@1+ (1,0) [0|15] "" Vector__XXX
 SG_ VCLEFT_liftgateNewHeightNudge m0 : 39|1@1+ (1,0) [0|1] "" Vector__XXX
 SG_ VCLEFT_liftgateNewSaveHeight m0 : 40|8@1+ (1,0) [0|255] "cm" Vector__XXX
 SG_ VCLEFT_liftgateGeofenceState m0 : 48|2@1+ (1,0) [0|3] "" Vector__XXX
 SG_ VCLEFT_liftgateCloseWarnChimeReq m0 : 56|1@1+ (1,0) [0|1] "" Vector__XXX
 SG_ VCLEFT_liftgateAboveCrossoverAng m0 : 59|1@1+ (1,0) [0|1] "" Vector__XXX
 SG_ VCLEFT_liftgateLatchRequest m0 : 61|3@1+ (1,0) [0|7] "" Vector__XXX
 SG_ VCLEFT_liftgateStrutDutyCycle m1 : 3|8@1- (1,0) [-100|100] "%" Vector__XXX
 SG_ VCLEFT_liftgateStrutCurrent m1 : 11|10@1- (0.1,0) [-30|30] "A" Vector__XXX
 SG_ VCLEFT_liftgatePosition m1 : 21|7@1- (1,46) [-5|95] "deg" Vector__XXX
 SG_ VCLEFT_liftgateSpeed m1 : 28|10@1- (0.1,0) [-30|30] "deg/s" Vector__XXX
 SG_ VCLEFT_liftgateHeight m1 : 38|8@1+ (1,0) [0|255] "cm" Vector__XXX
 SG_ VCLEFT_liftgatePositionDiff m1 : 46|6@1- (1,0) [-30|30] "deg" Vector__XXX

BO_TX_BU_ 769 : VCFRONT;
BO_TX_BU_ 1014 : VCFRONT;
BO_TX_BU_ 1013 : VCFRONT;
BO_TX_BU_ 1801 : VCFRONT;
BO_TX_BU_ 705 : VCFRONT;
BO_TX_BU_ 897 : VCFRONT;
BO_TX_BU_ 513 : VCFRONT;
BO_TX_BU_ 721 : VCFRONT;
BO_TX_BU_ 801 : VCFRONT;
BO_TX_BU_ 1349 : VCFRONT;
BO_TX_BU_ 929 : VCFRONT;
BO_TX_BU_ 507 : VCLEFT;
BO_TX_BU_ 290 : VCLEFT;
BO_TX_BU_ 626 : VCLEFT;
BO_TX_BU_ 1186 : VCLEFT;
BO_TX_BU_ 642 : VCLEFT;
BO_TX_BU_ 770 : VCLEFT;
BO_TX_BU_ 292 : VCLEFT;
BO_TX_BU_ 322 : VCLEFT;
CM_ BO_ 769 "Front body controller message: info";
CM_ SG_ 769 VCFRONT_infoIndex "Front body controller: info index";
CM_ SG_ 769 VCFRONT_infoBuildType "Front body controller: info build type";
CM_ SG_ 769 VCFRONT_infoBuildConfigId "Front body controller: info build config id";
CM_ SG_ 769 VCFRONT_infoHardwareId "Front body controller: info hardware id";
CM_ SG_ 769 VCFRONT_infoComponentId "Front body controller: info component id";
CM_ SG_ 769 VCFRONT_infoPcbaId "Front body controller: info pcba id";
CM_ SG_ 769 VCFRONT_infoAssemblyId "Front body controller: info assembly id; raw 255 = signal not available (SNA)";
CM_ SG_ 769 VCFRONT_infoUsageId "Front body controller: info usage id";
CM_ SG_ 769 VCFRONT_infoSubUsageId "Front body controller: info sub usage id";
CM_ SG_ 769 VCFRONT_infoAppCrc "Front body controller: info app crc";
CM_ SG_ 769 VC_infoHCMLAppCRC "Front body controller: info HCML app CRC";
CM_ SG_ 769 VCFRONT_infoAppGitHash "Front body controller: info app git hash";
CM_ SG_ 769 VCFRONT_infoBootGitHash "Front body controller: info boot git hash";
CM_ SG_ 769 VCFRONT_infoPlatformType "Front body controller: info platform type";
CM_ SG_ 769 VCFRONT_infoBootUdsProtoVersion "Front body controller: info boot uds proto version";
CM_ SG_ 769 VCFRONT_infoBootCrc "Front body controller: info boot crc";
CM_ SG_ 769 VC_infoHCMRAppCRC "Front body controller: info HCMR app CRC";
CM_ SG_ 769 VC_infoWiperAppCRC "Front body controller: info wiper app CRC";
CM_ BO_ 1014 "Front body controller message: light status";
CM_ SG_ 1014 VCFRONT_lowBeamLeftStatus "State of the left headlamp low beam light source; raw 3 = signal not available (SNA)";
CM_ SG_ 1014 VCFRONT_lowBeamRightStatus "State of the right headlamp low beam light source; raw 3 = signal not available (SNA)";
CM_ SG_ 1014 VCFRONT_highBeamLeftStatus "State of the left headlamp high beam light source; raw 3 = signal not available (SNA)";
CM_ SG_ 1014 VCFRONT_highBeamRightStatus "State of the right headlamp high beam light source; raw 3 = signal not available (SNA)";
CM_ SG_ 1014 VCFRONT_DRLLeftStatus "Status of the left daytime running light source; raw 3 = signal not available (SNA)";
CM_ SG_ 1014 VCFRONT_DRLRightStatus "Status of the right daytime running light source; raw 3 = signal not available (SNA)";
CM_ SG_ 1014 VCFRONT_fogLeftStatus "State of the left front fog light source; raw 3 = signal not available (SNA)";
CM_ SG_ 1014 VCFRONT_fogRightStatus "State of the right front fog light source; raw 3 = signal not available (SNA)";
CM_ SG_ 1014 VCFRONT_sideMarkersStatus "State of the side marker / auxiliary park light sources (left and right are on a shared HSD); raw 3 = signal not available (SNA)";
CM_ SG_ 1014 VCFRONT_sideRepeaterLeftStatus "State of the left side repeater light source; raw 3 = signal not available (SNA)";
CM_ SG_ 1014 VCFRONT_sideRepeaterRightStatus "State of the right side repeater light source; raw 3 = signal not available (SNA)";
CM_ SG_ 1014 VCFRONT_turnSignalLeftStatus "State of the left front turn signal light source; raw 3 = signal not available (SNA)";
CM_ SG_ 1014 VCFRONT_turnSignalRightStatus "State of the right front turn signal light source; raw 3 = signal not available (SNA)";
CM_ SG_ 1014 VCFRONT_parkLeftStatus "State of the left position/park light source; raw 3 = signal not available (SNA)";
CM_ SG_ 1014 VCFRONT_parkRightStatus "State of the right position/park light source; raw 3 = signal not available (SNA)";
CM_ SG_ 1014 VCFRONT_lowBeamLeftReadyForAimin "Front body controller: low beam left ready for aiming";
CM_ SG_ 1014 VCFRONT_lowBeamRightReadyForAimi "Front body controller: low beam right ready for aiming";
CM_ SG_ 1014 VCFRONT_lowBeamsOnForDRL "Shows if the low beam light source is being used to fulfil the daytime running light function (for Canada)";
CM_ SG_ 1014 VC_rightHeadlampHealth "Signal to report whether the right headlamp is powered and communicating";
CM_ SG_ 1014 VC_leftHeadlampHealth "Signal to report whether the left headlamp is powered and communicating";
CM_ SG_ 1014 VCFRONT_lightStatusMuxIndex "Front body controller: light status mux index";
CM_ SG_ 1014 VCFRONT_isAdaptiveHighBeamAvaila "Indication that the conditions (country code, hardware config, etc.) are acceptable to use the advanced driving beam feature.";
CM_ SG_ 1014 VCFRONT_isAdaptiveHighBeamFaulte "Detects if adaptive high beam functionality is unavailable or not operating as expected due to other dependencies.";
CM_ SG_ 1014 VCFRONT_isBendLightingAvailable "Detects if region and hardware conditions currently allow operation of the bend lighting feature.";
CM_ SG_ 1014 VCFRONT_advancedDrivingBeamStatu "Reports the current advanced driving beam system state.";
CM_ SG_ 1014 VCFRONT_headlampBendAngle "Measures the adaptive headlight bend angle.";
CM_ SG_ 1014 VCFRONT_headlampRoadClass "Reports the road class informing the use of dynamic low beams.";
CM_ BO_ 1013 "Front body controller message: lighting";
CM_ SG_ 1013 VCFRONT_indicatorLeftRequest "Front body controller: indicator left request";
CM_ SG_ 1013 VCFRONT_indicatorRightRequest "Front body controller: indicator right request";
CM_ SG_ 1013 VCFRONT_hazardLightRequest "Front body controller: hazard light request";
CM_ SG_ 1013 VCFRONT_ambientLightingBrightnes "Front body controller: ambient lighting brightnes; raw 255 = signal not available (SNA)";
CM_ SG_ 1013 VCFRONT_switchLightingBrightness "Front body controller: switch lighting brightness; raw 255 = signal not available (SNA)";
CM_ SG_ 1013 VCFRONT_courtesyLightingRequest "Flag to request courtesy lighting";
CM_ SG_ 1013 VCFRONT_hazardSwitchBacklight "Front body controller: hazard switch backlight";
CM_ SG_ 1013 VCFRONT_highBeamControlState "State of the virtual high beam stalk";
CM_ SG_ 1013 VCFRONT_dynamicBrakeLightState "Front body controller: dynamic brake light state";
CM_ SG_ 1013 VCFRONT_lightingCoreState "Core lighting state; raw 15 = signal not available (SNA)";
CM_ SG_ 1013 VCFRONT_intHighBeamsFunctionStat "State of the intermittent high beams lighting function";
CM_ SG_ 1013 VCFRONT_latchedHighBeamsFunction "State of the latched high beams lighting function";
CM_ SG_ 1013 VCFRONT_frontFogFunctionState "State of the front fog lighting function";
CM_ SG_ 1013 VCFRONT_headlightsReadyOrTimedOu "Front body controller: headlights ready or timed out";
CM_ SG_ 1013 VCFRONT_turnIndicatorStalk "Front body controller: turn indicator stalk; raw 3 = signal not available (SNA)";
CM_ SG_ 1013 VCFRONT_highBeamLatchingState "State of high beam latching; raw 0 = signal not available (SNA)";
CM_ SG_ 1013 VCFRONT_lightingCustomState "Custom lighting mode substate";
CM_ SG_ 1013 VC_fastFlashHazardsActive "Front body controller: fast flash hazards active";
CM_ SG_ 1013 VCFRONT_indicatorLeftInternal "Front body controller: indicator left internal";
CM_ SG_ 1013 VCFRONT_indicatorRightInternal "Front body controller: indicator right internal";
CM_ BO_ 1801 "Front body controller message: logging0point1 hz";
CM_ SG_ 1801 VCFRONT_logging0point1HzIndex "Front body controller: logging0point1 hz index";
CM_ SG_ 1801 VC_hcmlFactoryOfOrigin "Tier 1 supplier (Hella) factory of origin of the left headlamp";
CM_ SG_ 1801 VC_hcmlHellaPartNumberStatus "Front body controller: hcml hella part number status";
CM_ SG_ 1801 VC_hcmlHellaPartNumber "Value of the Hella Part Number written into EEPROM in the left headlamp";
CM_ SG_ 1801 VC_hcmlCurrentBinMappingType "Front body controller: hcml current bin mapping type";
CM_ SG_ 1801 VC_hcmlCurrentBin0Value "Front body controller: hcml current bin0 value; raw 0 = signal not available (SNA)";
CM_ SG_ 1801 VC_hcmlCurrentBin1Value "Front body controller: hcml current bin1 value; raw 0 = signal not available (SNA)";
CM_ SG_ 1801 VC_hcmlCurrentBin2Value "Front body controller: hcml current bin2 value; raw 0 = signal not available (SNA)";
CM_ SG_ 1801 VC_hcmlCurrentBin3Value "Front body controller: hcml current bin3 value; raw 0 = signal not available (SNA)";
CM_ SG_ 1801 VC_hcmlCurrentBin4Value "Front body controller: hcml current bin4 value; raw 0 = signal not available (SNA)";
CM_ SG_ 1801 VC_hcmlCurrentBin5Value "Front body controller: hcml current bin5 value; raw 0 = signal not available (SNA)";
CM_ SG_ 1801 VC_hcmlRegionAndSide "Left headlamp EEPROM region and side; raw 0 = signal not available (SNA)";
CM_ SG_ 1801 VC_hcmrFactoryOfOrigin "Tier 1 supplier (Hella) factory of origin of the right headlamp";
CM_ SG_ 1801 VC_hcmrHellaPartNumberStatus "Front body controller: hcmr hella part number status";
CM_ SG_ 1801 VC_hcmrHellaPartNumber "Value of the Hella Part Number written into EEPROM in the right headlamp";
CM_ SG_ 1801 VC_hcmrCurrentBinMappingType "Front body controller: hcmr current bin mapping type";
CM_ SG_ 1801 VC_hcmrCurrentBin0Value "Front body controller: hcmr current bin0 value; raw 0 = signal not available (SNA)";
CM_ SG_ 1801 VC_hcmrCurrentBin1Value "Front body controller: hcmr current bin1 value; raw 0 = signal not available (SNA)";
CM_ SG_ 1801 VC_hcmrCurrentBin2Value "Front body controller: hcmr current bin2 value; raw 0 = signal not available (SNA)";
CM_ SG_ 1801 VC_hcmrCurrentBin3Value "Front body controller: hcmr current bin3 value; raw 0 = signal not available (SNA)";
CM_ SG_ 1801 VC_hcmrCurrentBin4Value "Front body controller: hcmr current bin4 value; raw 0 = signal not available (SNA)";
CM_ SG_ 1801 VC_hcmrCurrentBin5Value "Front body controller: hcmr current bin5 value; raw 0 = signal not available (SNA)";
CM_ SG_ 1801 VC_hcmrRegionAndSide "Right headlamp EEPROM region and side; raw 0 = signal not available (SNA)";
CM_ BO_ 705 "Front body controller message: logging10 hz";
CM_ SG_ 705 VCFRONT_logging10HzIndex "Front body controller: logging10 hz index";
CM_ SG_ 705 VCFRONT_pumpBatteryOutVoltage "Front body controller: pump battery out voltage";
CM_ SG_ 705 VCFRONT_pumpPowertrainOutVoltage "Front body controller: pump powertrain out voltage";
CM_ SG_ 705 VCFRONT_pumpBatteryInitd "Front body controller: pump battery initd";
CM_ SG_ 705 VCFRONT_pumpPowertrainInitd "Front body controller: pump powertrain initd";
CM_ SG_ 705 VCFRONT_pumpBatteryEnabled "Front body controller: pump battery enabled";
CM_ SG_ 705 VCFRONT_pumpPowertrainEnabled "Front body controller: pump powertrain enabled";
CM_ SG_ 705 VCFRONT_pumpBatteryPowerOn "Front body controller: pump battery power on";
CM_ SG_ 705 VCFRONT_pumpPowertrainPowerOn "Front body controller: pump powertrain power on";
CM_ SG_ 705 VCFRONT_pumpsWake "Front body controller: pumps wake";
CM_ SG_ 705 VCFRONT_pumpBatSpiError "Front body controller: pump bat spi error";
CM_ SG_ 705 VCFRONT_pumpPtSpiError "Front body controller: pump pt spi error";
CM_ SG_ 705 VCFRONT_coolantFlowChillerActual "Front body controller: coolant flow chiller actual";
CM_ SG_ 705 VCFRONT_radiatorFanOutVoltage "Front body controller: radiator fan out voltage";
CM_ SG_ 705 VCFRONT_radiatorFanInitd "Front body controller: radiator fan initd";
CM_ SG_ 705 VCFRONT_radiatorFanEnabled "Indication that the cooling fan is enabled";
CM_ SG_ 705 VCFRONT_radiatorFanPowerOn "Indication that the cooling fan is powered on";
CM_ SG_ 705 VCFRONT_radiatorFanPhaseCurrent "Front body controller: radiator fan phase current";
CM_ SG_ 705 VCFRONT_radiatorFanPhaseIMax "Front body controller: radiator fan phase i max";
CM_ SG_ 705 VCFRONT_thmlFanSpiError "Front body controller: thml fan spi error";
CM_ SG_ 705 VCFRONT_chargeTrapNominalCOP1Bat "Front body controller: charge trap nominal COP1 batt heat";
CM_ SG_ 705 VCFRONT_chargeTrapNominalCOP1Chi "Front body controller: charge trap nominal COP1 chiller batt heat";
CM_ SG_ 705 VCFRONT_COP1OilWarmingNeeded "Reports if refrigerant compressor oil warming is needed.";
CM_ BO_ 897 "Front body controller message: logging1 hz";
CM_ SG_ 897 VCFRONT_logging1HzIndex "Front body controller: logging1 hz index";
CM_ SG_ 897 VCFRONT_modeTransitionID "Front body controller: mode transition ID";
CM_ SG_ 897 VCFRONT_modeDesired "Front body controller: mode desired";
CM_ SG_ 897 VCFRONT_targetPTActiveCool "Front body controller: target PT active cool";
CM_ SG_ 897 VCFRONT_targetPtOptionalActiveCo "Front body controller: target pt optional active cool";
CM_ SG_ 897 VCFRONT_targetPTPassive "Front body controller: target PT passive";
CM_ SG_ 897 VCFRONT_targetBatActiveCool "Front body controller: target bat active cool";
CM_ SG_ 897 VCFRONT_targetBatOptionalActiveC "Front body controller: target bat optional active cool";
CM_ SG_ 897 VCFRONT_targetBatPassive "Front body controller: target bat passive";
CM_ SG_ 897 VCFRONT_targetBatActiveHeat "Active heating temperature target for the battery coolant loop";
CM_ SG_ 897 VCFRONT_condenserPressureLimit "Front body controller: condenser pressure limit";
CM_ SG_ 897 VCFRONT_fanDemandCondenser "Front body controller: fan demand condenser";
CM_ SG_ 897 VCFRONT_fanDemandRadiator "Front body controller: fan demand radiator";
CM_ SG_ 897 VCFRONT_tempRefrigSuction "Refrigerant system suction temperature; raw 255 = signal not available (SNA)";
CM_ SG_ 897 VCFRONT_pumpBatteryFETTemp "Front body controller: pump battery FET temp; raw 255 = signal not available (SNA)";
CM_ SG_ 897 VCFRONT_pumpPowertrainFETTemp "Front body controller: pump powertrain FET temp; raw 255 = signal not available (SNA)";
CM_ SG_ 897 VCFRONT_radiatorFanFETTemp "Front body controller: radiator fan FET temp; raw 255 = signal not available (SNA)";
CM_ SG_ 897 VCFRONT_radiatorFanRunReason "Current radiator fan run readon";
CM_ SG_ 897 VCFRONT_coolantValveModeWrong "Front body controller: coolant valve mode wrong";
CM_ SG_ 897 VCFRONT_coolantTempBasedMode "Front body controller: coolant temp based mode";
CM_ SG_ 897 VCFRONT_coolantValveRecalReason "coolant Valve Reason for Recalibration";
CM_ SG_ 897 VCFRONT_coolantValveCountRange "Range of tick counts of the coolant valve actuator; raw 1023 = signal not available (SNA)";
CM_ SG_ 897 VCFRONT_coolantValveAngleDrift "Estimated angular drift of the coolant valve";
CM_ SG_ 897 VCFRONT_coolantValveRecalCount "coolant Valve Calibration Count";
CM_ SG_ 897 VCFRONT_coolantValveWindupEst "Front body controller: coolant valve windup est";
CM_ SG_ 897 VCFRONT_coolantValveRadBypass "Percent of coolant bypassing the powertrain radiator; raw 127 = signal not available (SNA)";
CM_ SG_ 897 VCFRONT_usingModeledPs "Front body controller: using modeled ps";
CM_ SG_ 897 VCFRONT_usingModeledPd "Front body controller: using modeled pd";
CM_ SG_ 897 VCFRONT_usingModeledPl "Front body controller: using modeled pl";
CM_ SG_ 897 VCFRONT_usingModeledTs "Front body controller: using modeled ts";
CM_ SG_ 897 VCFRONT_usingModeledTd "Front body controller: using modeled td";
CM_ SG_ 897 VCFRONT_usingModeledTl "Front body controller: using modeled tl";
CM_ SG_ 897 VCFRONT_hpChargeCableType "Front body controller: hp charge cable type";
CM_ SG_ 897 VCFRONT_subcoolActual "Front body controller: subcool actual";
CM_ SG_ 897 VCFRONT_hpSubcoolTarget "Front body controller: hp subcool target";
CM_ SG_ 897 VCFRONT_CMPDischargeSuperheat "Front body controller: CMP discharge superheat";
CM_ SG_ 897 VCFRONT_hpCOP "Front body controller: hp COP";
CM_ SG_ 897 VCFRONT_lowSideWattsLift "Front body controller: low side watts lift";
CM_ SG_ 897 VCFRONT_tempSuperheatActual "Front body controller: temp superheat actual; raw 1023 = signal not available (SNA)";
CM_ SG_ 897 VCFRONT_tempSuperheatTarget "Front body controller: temp superheat target";
CM_ SG_ 897 VCFRONT_refrigerantHasBeenFilled "Front body controller: refrigerant has been filled";
CM_ SG_ 897 VCFRONT_refCommissionStatus "Front body controller: ref commission status";
CM_ SG_ 897 VCFRONT_LCCPurgeActive "Reports if Liquid Cooled Condenser (LCC) refrigerant purge is active on the heat pump.";
CM_ SG_ 897 VCFRONT_exteriorQuietModeEnabled "Front body controller: exterior quiet mode enabled";
CM_ SG_ 897 VCFRONT_exteriorQuietModeAllowed "Front body controller: exterior quiet mode allowed";
CM_ SG_ 897 VCFRONT_CCQdotFdFrwrdTarget "Front body controller: CC qdot fd frwrd target";
CM_ SG_ 897 VCFRONT_CCQdotFdbk "Front body controller: CC qdot fdbk";
CM_ SG_ 897 VCFRONT_CCQdotActual "Front body controller: CC qdot actual";
CM_ SG_ 897 VCFRONT_evapFdFrwrdTarget "Front body controller: evap fd frwrd target";
CM_ SG_ 897 VCFRONT_evapFdbk "Front body controller: evap fdbk";
CM_ SG_ 897 VCFRONT_DIQdotA "Front body controller: DI qdot a";
CM_ SG_ 897 VCFRONT_evapFdFrwrdTargetMinimum "Front body controller: evap fd frwrd target minimum";
CM_ SG_ 897 VCFRONT_passiveCoolingState "Front body controller: passive cooling state";
CM_ SG_ 897 VCFRONT_totalLoadCoolingDominant "Front body controller: total load cooling dominant";
CM_ SG_ 897 VCFRONT_feedfwdLoadCoolingDomina "Front body controller: feedfwd load cooling dominant";
CM_ SG_ 897 VCFRONT_modelLoadCoolingDominant "Front body controller: model load cooling dominant";
CM_ SG_ 897 VCFRONT_hpPotentialLowRefrig "Front body controller: hp potential low refrig";
CM_ SG_ 897 VCFRONT_hpRefrigerantPurgeState "Front body controller: hp refrigerant purge state";
CM_ SG_ 897 VCFRONT_estPressureLiq "Front body controller: est pressure liq";
CM_ SG_ 897 VCFRONT_estPressureSuct "Front body controller: est pressure suct";
CM_ SG_ 897 VCFRONT_estPressureDisch "Front body controller: est pressure disch";
CM_ SG_ 897 VCFRONT_estTempLiq "Front body controller: est temp liq";
CM_ SG_ 897 VCFRONT_estTempSuct "Front body controller: est temp suct";
CM_ SG_ 897 VCFRONT_estTempDisch "Front body controller: est temp disch";
CM_ SG_ 897 VCFRONT_estCompressorRpm "Front body controller: est compressor rpm";
CM_ SG_ 897 VCFRONT_estQLift "Front body controller: est q lift";
CM_ SG_ 897 VCFRONT_cycleModelConverged "Front body controller: cycle model converged";
CM_ SG_ 897 VCFRONT_compStandbyCoastDownMode "Front body controller: comp standby coast down mode";
CM_ SG_ 897 VCFRONT_compStandbyShowroomMode "Front body controller: comp standby showroom mode";
CM_ SG_ 897 VCFRONT_chillerExvCalibOffset "Last calibration offset calculated for the Chiller EXV";
CM_ SG_ 897 VCFRONT_evapExvCalibOffset "Last calibration offset calculated for the Evaporator EXV";
CM_ SG_ 897 VCFRONT_recircExvCalibOffset "Last calibration offset calculated for the Recirc EXV";
CM_ SG_ 897 VCFRONT_lccExvCalibOffset "Last calibration offset calculated for the Liquid Cooled Condenser EXV";
CM_ SG_ 897 VCFRONT_ccLeftExvCalibOffset "Last calibration offset calculated for the Left Cabin Condenser EXV";
CM_ SG_ 897 VCFRONT_ccRightExvCalibOffset "Last calibration offset calculated for the Right Cabin Condenser EXV";
CM_ SG_ 897 VCFRONT_chillerEXVControlState "Control State of the chiller electronic expansion valve";
CM_ SG_ 897 VCFRONT_evapEXVControlState "Control State of the evaporator electronic expansion valve";
CM_ SG_ 897 VCFRONT_recircEXVControlState "Control State of the recirc electronic expansion valve";
CM_ SG_ 897 VCFRONT_lccEXVControlState "Control State of the liquid cooled condenser electronic expansion valve";
CM_ SG_ 897 VCFRONT_cclEXVControlState "Control State of the chiller electronic expansion valve";
CM_ SG_ 897 VCFRONT_ccrEXVControlState "Control State of the right cabin condenser electronic expansion valve";
CM_ SG_ 897 VCFRONT_chillerExvCalibFailed "State of the last calibration for the Chiller EXV";
CM_ SG_ 897 VCFRONT_evapExvCalibFailed "State of the last calibration for the Evaporator EXV";
CM_ SG_ 897 VCFRONT_recircExvCalibFailed "State of the last calibration for the Recirc EXV";
CM_ SG_ 897 VCFRONT_lccExvCalibFailed "State of the last calibration for the Liquid Cooled Condenser EXV";
CM_ SG_ 897 VCFRONT_ccLeftExvCalibFailed "State of the last calibration for the Left Cabin Condenser EXV";
CM_ SG_ 897 VCFRONT_ccRightExvCalibFailed "State of the last calibration for the Right Cabin Condenser EXV";
CM_ SG_ 897 VCFRONT_ambientTempSniffActive "Front body controller: ambient temp sniff active";
CM_ SG_ 897 VCFRONT_ambientTempPassiveSniffi "Front body controller: ambient temp passive sniffing";
CM_ SG_ 897 VCFRONT_ambientTempRadSampling "Front body controller: ambient temp rad sampling";
CM_ SG_ 897 VCFRONT_ambientTempSpeedSampling "Front body controller: ambient temp speed sampling";
CM_ SG_ 897 VCFRONT_feedFwdMDotEvaporator "Front body controller: feed fwd m dot evaporator";
CM_ SG_ 897 VCFRONT_hpCabinHeatBatteryHeatAm "Front body controller: hp cabin heat battery heat amb src";
CM_ SG_ 897 VCFRONT_hpCabinHeatBatteryHeatCO "Front body controller: hp cabin heat battery heat COP1";
CM_ SG_ 897 VCFRONT_feedFwdMDotCabinCondense "Feed forward MDOT for the cabin condenser controller.";
CM_ SG_ 897 VCFRONT_feedBackEvapTempControll "Evap temperature controller feedback.";
CM_ SG_ 897 VCFRONT_feedBackDuctTempControll "Feedback for the duct temp controller.";
CM_ SG_ 897 VCFRONT_isSolenoidAllowed "Front body controller: is solenoid allowed";
CM_ SG_ 897 VCFRONT_maxChillerCoolingPower "Front body controller: max chiller cooling power";
CM_ SG_ 897 VCFRONT_fanControlRadCanCool "Front body controller: fan control rad can cool";
CM_ SG_ 897 VCFRONT_fanControlFeedfwdActive "Front body controller: fan control feedfwd active";
CM_ SG_ 897 VCFRONT_fanControlRadiatorUa "Front body controller: fan control radiator ua";
CM_ SG_ 897 VCFRONT_fanControlRadiatorInletT "Front body controller: fan control radiator inlet temp";
CM_ SG_ 897 VCFRONT_hpASBatteryHeatingAllowe "Front body controller: hp AS battery heating allowed";
CM_ SG_ 897 VCFRONT_hpCOP1BatteryHeatingAllo "Front body controller: hp COP1 battery heating allowed";
CM_ SG_ 897 VCFRONT_hpCabinHeatScavengeOnly "Front body controller: hp cabin heat scavenge only";
CM_ SG_ 897 VCFRONT_hpCabinHeatAmbientSource "Front body controller: hp cabin heat ambient source";
CM_ SG_ 897 VCFRONT_hpCabinHeatReheatScaveng "Front body controller: hp cabin heat reheat scavenge";
CM_ SG_ 897 VCFRONT_hpCabinHeatReheatAmbient "Front body controller: hp cabin heat reheat ambient source";
CM_ SG_ 897 VCFRONT_hpCabinHeatBlend "Front body controller: hp cabin heat blend";
CM_ SG_ 897 VCFRONT_hpCabinHeatCOP1 "Front body controller: hp cabin heat COP1";
CM_ SG_ 897 VCFRONT_hpCabinHeatBatteryHeatRe "Front body controller: hp cabin heat battery heat reheat amb src";
CM_ SG_ 897 VCFRONT_hpCabinHeatBatteryCoolRe "Front body controller: hp cabin heat battery cool reheat";
CM_ SG_ 897 VCFRONT_hpCabinCoolEvaporator "Front body controller: hp cabin cool evaporator";
CM_ SG_ 897 VCFRONT_hpCabinCoolEvaporatorReh "Front body controller: hp cabin cool evaporator reheat";
CM_ SG_ 897 VCFRONT_hpBatteryHeatAmbientSour "Front body controller: hp battery heat ambient source";
CM_ SG_ 897 VCFRONT_hpBatteryHeatCOP1 "Front body controller: hp battery heat COP1";
CM_ SG_ 897 VCFRONT_hpBatteryCool "Front body controller: hp battery cool";
CM_ SG_ 897 VCFRONT_hpBatteryCoolCabinConden "Front body controller: hp battery cool cabin condenser CD";
CM_ SG_ 897 VCFRONT_hpBatteryCoolCabinC_0001 "Front body controller: hp battery cool cabin condenser HD";
CM_ SG_ 897 VCFRONT_hpBatteryCoolCabinReheat "Front body controller: hp battery cool cabin reheat";
CM_ SG_ 897 VCFRONT_hpBatteryCoolEvaporator "Front body controller: hp battery cool evaporator";
CM_ SG_ 897 VCFRONT_suctionSuperheatEstTsSNA "Front body controller: suction superheat est ts SNA";
CM_ SG_ 897 VCFRONT_tempRefrigSuctionEst "Front body controller: temp refrig suction est";
CM_ SG_ 897 VCFRONT_hpBattOverTempHvacDisabl "Front body controller: hp batt over temp hvac disable";
CM_ SG_ 897 VCFRONT_hpDiagLouverCalib "Diagnostics requested a louver calibration.";
CM_ SG_ 897 VCFRONT_hpDiagHighSideNotNominal "Front body controller: hp diag high side not nominal";
CM_ SG_ 897 VCFRONT_hpForceModeRadClear "Front body controller: hp force mode rad clear";
CM_ SG_ 897 VCFRONT_estPressureDischargeSat "Front body controller: est pressure discharge sat";
CM_ SG_ 897 VCFRONT_tempRefrigLiquid "Refrigerant system liquid line temperature; raw 2047 = signal not available (SNA)";
CM_ SG_ 897 VCFRONT_totalBattHeatingPower "Total battery heating power requested";
CM_ SG_ 897 VCFRONT_hpPotentialFrozenRadiato "Front body controller: hp potential frozen radiator";
CM_ SG_ 897 VCFRONT_passiveSeriesRegOn "Front body controller: passive series reg on";
CM_ SG_ 897 VCFRONT_passiveDemandRadBypass "Front body controller: passive demand rad bypass";
CM_ SG_ 897 VCFRONT_targetLccActiveCoolCap "Front body controller: target lcc active cool cap";
CM_ SG_ 897 VCFRONT_targetLccActiveCoolEff "Front body controller: target lcc active cool eff";
CM_ SG_ 897 VCFRONT_coolantValveDailyAngleTr "Running 10-day average of daily angular travel";
CM_ SG_ 897 VCFRONT_dischargePressureLimit "Front body controller: discharge pressure limit";
CM_ SG_ 897 VCFRONT_radMovementBlockActive "Front body controller: rad movement block active";
CM_ SG_ 897 VCFRONT_radBypassMoveReason "Front body controller: rad bypass move reason";
CM_ SG_ 897 VCFRONT_hpBattHeatingPower "Front body controller: hp batt heating power";
CM_ SG_ 897 VCFRONT_tempCoolantRadOutletEstS "Front body controller: temp coolant rad outlet est status";
CM_ SG_ 897 VCFRONT_targetBatActiveCoolSourc "Front body controller: target bat active cool source";
CM_ SG_ 897 VCFRONT_targetPTActiveCoolSource "Front body controller: target PT active cool source";
CM_ SG_ 897 VCFRONT_hpColdStagnationLimit "Front body controller: hp cold stagnation limit";
CM_ SG_ 897 VCFRONT_hpHotStagnationLimit "Front body controller: hp hot stagnation limit";
CM_ SG_ 897 VCFRONT_hpCompFlowIndex "Front body controller: hp comp flow index";
CM_ SG_ 897 VCFRONT_hpCompFlowIndexFiltered "Front body controller: hp comp flow index filtered";
CM_ SG_ 897 VCFRONT_subcoolEstTlSNA "Front body controller: subcool est tl SNA";
CM_ SG_ 897 VCFRONT_subcoolEstPlSNA "Front body controller: subcool est pl SNA";
CM_ SG_ 897 VCFRONT_tempRefrigLiquidEst "Front body controller: temp refrig liquid est";
CM_ SG_ 897 VCFRONT_pressureRefrigLiquidEst "Front body controller: pressure refrig liquid est";
CM_ SG_ 897 VCFRONT_cmpIsentropicCheckPassed "Front body controller: cmp isentropic check passed";
CM_ SG_ 897 VCFRONT_louverPosReason "Front body controller: louver pos reason";
CM_ SG_ 897 VCFRONT_hpEnergyFlowIndex "Front body controller: hp energy flow index";
CM_ SG_ 897 VCFRONT_hpEnergyFlowIndexFiltere "Refrigerant system modeled energy flow index filtered";
CM_ SG_ 897 VCFRONT_ductLeftAtSS "Front body controller: duct left at SS";
CM_ SG_ 897 VCFRONT_ductRightAtSS "Front body controller: duct right at SS";
CM_ SG_ 897 VCFRONT_minCompressorRPMAllowed "Front body controller: min compressor RPM allowed";
CM_ SG_ 897 VCFRONT_ccRefrigerantMassFlow "Front body controller: cc refrigerant mass flow";
CM_ SG_ 897 VCFRONT_highSideDpResidual "Front body controller: high side dp residual";
CM_ SG_ 897 VCFRONT_abnormalHighSuctionSuper "Front body controller: abnormal high suction superheat";
CM_ SG_ 897 VCFRONT_coolantValveAngleTravel "Total angular travel since last (re)calibration";
CM_ SG_ 897 VCFRONT_chargeShuttleType "Front body controller: charge shuttle type";
CM_ SG_ 897 VCFRONT_hpRefrigTempSensorCheckC "Front body controller: hp refrig temp sensor check can fire";
CM_ SG_ 897 VCFRONT_hpRefrigPressureSensorCh "Front body controller: hp refrig pressure sensor check can fire";
CM_ SG_ 897 VCFRONT_tempSuperheatActFiltered "Front body controller: temp superheat act filtered";
CM_ SG_ 897 VCFRONT_tempRefrigDischarge "Refrigerant system discharge temperature; raw 2047 = signal not available (SNA)";
CM_ SG_ 897 VCFRONT_pumpBatteryRPMTarget "Front body controller: pump battery RPM target; raw 255 = signal not available (SNA)";
CM_ SG_ 897 VCFRONT_pumpPowertrainRPMTarget "Front body controller: pump powertrain RPM target; raw 255 = signal not available (SNA)";
CM_ SG_ 897 VCFRONT_coolantFlowChillerTarget "Front body controller: coolant flow chiller target";
CM_ SG_ 897 VCFRONT_radiatorFanRPMTarget "Front body controller: radiator fan RPM target; raw 255 = signal not available (SNA)";
CM_ SG_ 897 VCFRONT_preventReEntryTillNexthp "Front body controller: prevent re entry till nexthp reset COP1";
CM_ SG_ 897 VCFRONT_chillerBattHeatingPowerA "Front body controller: chiller batt heating power available";
CM_ SG_ 897 VCFRONT_isExpectedQChillerVeryHi "Front body controller: is expected q chiller very high COP1";
CM_ SG_ 897 VCFRONT_autopilotAirPurgeRoutine "Front body controller: autopilot air purge routine counter";
CM_ SG_ 897 VCFRONT_superheatProtectionLimit "Front body controller: superheat protection limit";
CM_ SG_ 897 VCFRONT_chillerDemandWatts "Front body controller: chiller demand watts";
CM_ SG_ 897 VCFRONT_nominalTevapHWLimit "Front body controller: nominal tevap HW limit";
CM_ SG_ 897 VCFRONT_battCoolEvapEnableDelay "Front body controller: batt cool evap enable delay";
CM_ SG_ 897 VCFRONT_ambientTempState "Front body controller: ambient temp state";
CM_ SG_ 897 VCFRONT_ambientTempUnlatchReason "Front body controller: ambient temp unlatch reason";
CM_ SG_ 897 VCFRONT_compressorSuctionVaporQu "Front body controller: compressor suction vapor quality";
CM_ SG_ 897 VCFRONT_cabinHeatingCOP1MinActiv "Estimation of minimal active refrigerant charge during cabin heating COP1 mode";
CM_ SG_ 897 VCFRONT_hpDuctTargetLeft "Front body controller: hp duct target left";
CM_ SG_ 897 VCFRONT_hpDuctTargetRight "Front body controller: hp duct target right";
CM_ SG_ 897 VCFRONT_radiatorUAIndex "Reports the radiator UA index in percentage defined as actual calculated UA divided by the expected nominal UA.";
CM_ SG_ 897 VCFRONT_maxBatInletCoolantTempAl "Front body controller: max bat inlet coolant temp allowed";
CM_ SG_ 897 VCFRONT_coolantTempInBypassDelta "Front body controller: coolant temp in bypass delta";
CM_ SG_ 897 VCFRONT_targetAPPActiveCool "Front body controller: target APP active cool";
CM_ BO_ 513 "Front body controller message: logging and vitals10 hz";
CM_ SG_ 513 VCFRONT_loggingAndVitals10HzInde "Front body controller: logging and vitals10 hz index";
CM_ SG_ 513 VCFRONT_pumpBatteryRPMActual "Front body controller: pump battery RPM actual; raw 255 = signal not available (SNA)";
CM_ SG_ 513 VCFRONT_pumpPowertrainRPMActual "Front body controller: pump powertrain RPM actual; raw 255 = signal not available (SNA)";
CM_ SG_ 513 VCFRONT_radiatorFanRPMActual "Front body controller: radiator fan RPM actual; raw 255 = signal not available (SNA)";
CM_ SG_ 513 VCFRONT_exvFlowTarget "Front body controller: exv flow target";
CM_ SG_ 513 VCFRONT_activeLouverOpenPosTarg "The target position for the active louver";
CM_ SG_ 513 VCFRONT_pressureRefrigLiquid "Refrigerant system Liquid line pressure; raw 511 = signal not available (SNA)";
CM_ SG_ 513 VCFRONT_compSleepRequest "Front body controller: comp sleep request";
CM_ SG_ 513 VCFRONT_thermalHvPowerBudget "Front body controller: thermal hv power budget";
CM_ SG_ 513 VCFRONT_compMinOnTimeActive "Front body controller: comp min on time active";
CM_ SG_ 513 VCFRONT_compMinOffTimeActive "Front body controller: comp min off time active";
CM_ SG_ 513 VCFRONT_fanDemand "Front body controller: fan demand";
CM_ SG_ 513 VCFRONT_compressorState "State of the refrigerant compressor.";
CM_ SG_ 513 VCFRONT_compDemandEvap "Front body controller: comp demand evap";
CM_ SG_ 513 VCFRONT_exvState "Front body controller: exv state";
CM_ SG_ 513 VCFRONT_solenoidEvapState "Front body controller: solenoid evap state";
CM_ SG_ 513 VCFRONT_compDemandChiller "Front body controller: comp demand chiller";
CM_ SG_ 513 VCFRONT_coolantValveMode "Coolant mode of the powertrain cooling circuit";
CM_ SG_ 513 VCFRONT_compFaultSeverity "Front body controller: comp fault severity";
CM_ SG_ 513 VCFRONT_solenoidEngaged "Front body controller: solenoid engaged";
CM_ SG_ 513 VCFRONT_hpHighSideHX "Front body controller: hp high side HX";
CM_ SG_ 513 VCFRONT_hpLowSideHX "Front body controller: hp low side HX";
CM_ SG_ 513 VCFRONT_hpDominantLoad "Dominant load type for the refrigerant system";
CM_ SG_ 513 VCFRONT_hpBlendType "Front body controller: hp blend type";
CM_ SG_ 513 VCFRONT_hpQuietModeEnabled "Front body controller: hp quiet mode enabled";
CM_ SG_ 513 VCFRONT_hpCabinLoadType "Front body controller: hp cabin load type";
CM_ SG_ 513 VCFRONT_hpBatteryLoadType "Front body controller: hp battery load type";
CM_ SG_ 513 VCFRONT_hpReqCoolantMode "Front body controller: hp req coolant mode";
CM_ SG_ 513 VCFRONT_hpReqTransScavenge "Front body controller: hp req trans scavenge";
CM_ SG_ 513 VCFRONT_compLiqPumpOutState "Front body controller: comp liq pump out state";
CM_ SG_ 513 VCFRONT_frunkStateDBG "The verbose debug state of the frunk latch";
CM_ SG_ 513 VCFRONT_frunkSwitchGroupState "Front body controller: frunk switch group state";
CM_ SG_ 513 VCFRONT_chillerExvFlow "Percent of full range that the Chiller EXV has opened";
CM_ SG_ 513 VCFRONT_evapExvFlow "Percent of full range that the evap EXV has opened";
CM_ SG_ 513 VCFRONT_recircExvFlow "Percent of full range that the recirc EXV has opened";
CM_ SG_ 513 VCFRONT_lccExvFlow "Percent of full range that the Liquid cooled condenser EXV has opened";
CM_ SG_ 513 VCFRONT_cclExvFlow "Percent of full range that the left cabin condenser EXV has opened";
CM_ SG_ 513 VCFRONT_ccrExvFlow "Percent of full range that the right cabin condenser EXV has opened";
CM_ SG_ 513 VCFRONT_chillerExvState "State of the chiller electronic expansion valve";
CM_ SG_ 513 VCFRONT_evapExvState "State of the evaporator electronic expansion valve";
CM_ SG_ 513 VCFRONT_recircExvState "State of the recirc electronic expansion valve";
CM_ SG_ 513 VCFRONT_chillerExvFlowTarget "Target percentage of full range that the chiler electronic expansion valve is commanded to open";
CM_ SG_ 513 VCFRONT_evapExvFlowTarget "Target percentage of full range that the evap electronic expansion valve is commanded to open";
CM_ SG_ 513 VCFRONT_recircExvFlowTarget "Target percentage of full range that the recirc electronic expansion valve is commanded to open";
CM_ SG_ 513 VCFRONT_lccExvFlowTarget "Target percentage of full range that the liquid cooled condenser electronic expansion valve is commanded to open";
CM_ SG_ 513 VCFRONT_cclExvFlowTarget "Target percentage of full range that the cabin condenser left electronic expansion valve is commanded to open";
CM_ SG_ 513 VCFRONT_ccrExvFlowTarget "Target percentage of full range that the cabin condenser right electronic expansion valve is commanded to open";
CM_ SG_ 513 VCFRONT_lccExvState "State of the liquid cooled condenser electronic expansion valve";
CM_ SG_ 513 VCFRONT_cclExvState "State of the cabin condenser left electronic expansion valve";
CM_ SG_ 513 VCFRONT_ccrExvState "State of the cabin conddenser left electronic expansion valve";
CM_ BO_ 721 "Front body controller message: ok to use high power";
CM_ SG_ 721 VCFRONT_vcleftOkToUseHighPower "Front body controller: vcleft ok to use high power";
CM_ SG_ 721 VCFRONT_vcrightOkToUseHighPower "Front body controller: vcright ok to use high power";
CM_ SG_ 721 VCFRONT_das1OkToUseHighPower "Front body controller: das1 ok to use high power";
CM_ SG_ 721 VCFRONT_das2OkToUseHighPower "Front body controller: das2 ok to use high power";
CM_ SG_ 721 VCFRONT_MCULogicOkToUseHighPower "Front body controller: MCU logic ok to use high power";
CM_ SG_ 721 VCFRONT_MCUAudioOkToUseHighPower "Front body controller: MCU audio ok to use high power";
CM_ SG_ 721 VCFRONT_cpOkToUseHighPower "Front body controller: cp ok to use high power";
CM_ SG_ 721 VCFRONT_premAudioOkToUseHiPower "Front body controller: prem audio ok to use hi power";
CM_ SG_ 721 VCFRONT_tasOkToUseHighPower "Front body controller: tas ok to use high power";
CM_ BO_ 801 "Front body controller message: sensors";
CM_ SG_ 801 VCFRONT_tempCoolantBatInlet "Battery measured inlet coolant temperature; raw 1023 = signal not available (SNA)";
CM_ SG_ 801 VCFRONT_tempCoolantPTInlet "Powertrain measured inlet coolant temperature; raw 2047 = signal not available (SNA)";
CM_ SG_ 801 VCFRONT_coolantLevel "Front body controller: coolant level";
CM_ SG_ 801 VCFRONT_brakeFluidLevel "Reports detected brake fluid level at the fluid reservoir.; raw 0 = signal not available (SNA)";
CM_ SG_ 801 VCFRONT_tempAmbient "Front body controller: temp ambient; raw 0 = signal not available (SNA)";
CM_ SG_ 801 VCFRONT_washerFluidLevel "Indicates that the sensor has detected low windshield washer fluid.; raw 0 = signal not available (SNA)";
CM_ SG_ 801 VCFRONT_tempAmbientFiltered "Filtered ambient temperature based on vehicle speed; raw 0 = signal not available (SNA)";
CM_ SG_ 801 VCFRONT_battSensorIrrational "Front body controller: batt sensor irrational";
CM_ SG_ 801 VCFRONT_ptSensorIrrational "Front body controller: pt sensor irrational";
CM_ SG_ 801 VCFRONT_sensorsCounter "Front body controller: sensors counter";
CM_ SG_ 801 VCFRONT_sensorsChecksum "Front body controller: sensors checksum";
CM_ BO_ 1349 "Front body controller message: system status";
CM_ SG_ 1349 VCFRONT_systemStatusMuxIndex "Front body controller: system status mux index";
CM_ SG_ 1349 VCFRONT_systemStatusCounter "Front body controller: system status counter";
CM_ SG_ 1349 VCFRONT_systemStatusChecksum "Front body controller: system status checksum";
CM_ SG_ 1349 VCFRONT_loadShedReason "Front body controller: load shed reason";
CM_ SG_ 1349 VCFRONT_VCRightEFuseLoadShedStag "Front body controller: VC right e fuse load shed stage";
CM_ SG_ 1349 VCFRONT_VCLeftEFuseLoadShedStage "Front body controller: VC left e fuse load shed stage";
CM_ SG_ 1349 VCFRONT_DCDCSaturationLoadShedSt "Front body controller: DCDC saturation load shed stage";
CM_ SG_ 1349 VCFRONT_vehicleLoadShedStage "Front body controller: vehicle load shed stage";
CM_ SG_ 1349 VCFRONT_HVFaultVehicleLoadShedRe "Front body controller: HV fault vehicle load shed request";
CM_ SG_ 1349 VCFRONT_postCrashVehicleLoadShed "Front body controller: post crash vehicle load shed active";
CM_ SG_ 1349 VCFRONT_HVFaultVehicleLoadShedAc "Front body controller: HV fault vehicle load shed active";
CM_ SG_ 1349 VCFRONT_factoryVehicleLoadShedAc "Indicates that vehicle is factory load shedding";
CM_ SG_ 1349 VCFRONT_anyVehicleLoadShedActive "Front body controller: any vehicle load shed active";
CM_ SG_ 1349 VCFRONT_DIVehLoadShedActive "Front body controller: DI veh load shed active";
CM_ SG_ 1349 VCFRONT_HVFaultLoadShedStateDBG "Front body controller: HV fault load shed state DBG";
CM_ SG_ 1349 VCFRONT_LVUnhealthyVehicleLoadSh "Front body controller: LV unhealthy vehicle load shed active";
CM_ SG_ 1349 VCFRONT_loadShedStsCondenserFan "Front body controller: load shed sts condenser fan";
CM_ SG_ 1349 VCFRONT_loadShedStsPTPump "Front body controller: load shed sts PT pump";
CM_ SG_ 1349 VCFRONT_loadShedMCUAudio "Front body controller: load shed MCU audio";
CM_ SG_ 1349 VCFRONT_loadShedHVDownTriggerDBG "Front body controller: load shed HV down trigger DBG";
CM_ SG_ 1349 VCFRONT_loadShedPCSSatTriggerDBG "Front body controller: load shed PCS sat trigger DBG";
CM_ SG_ 1349 VCFRONT_loadShedStsBatteryPump "Front body controller: load shed sts battery pump";
CM_ SG_ 1349 VCFRONT_loadShedStsAPGlassHeater "Front body controller: load shed sts AP glass heater";
CM_ SG_ 1349 VCFRONT_loadShedStsMCUGraphics "Front body controller: load shed sts MCU graphics";
CM_ SG_ 1349 VCFRONT_IBSCurrentRMS_loadShed "Front body controller: IBS current RMS load shed";
CM_ SG_ 1349 VCFRONT_loadShedAhLeakyBktCntDBG "Front body controller: load shed ah leaky bkt cnt DBG";
CM_ SG_ 1349 VCFRONT_loadShedPcs "Front body controller: load shed pcs";
CM_ SG_ 1349 VCFRONT_loadShedGTWDownstrmRails "Front body controller: load shed GTW downstrm rails";
CM_ SG_ 1349 VCFRONT_loadShedPCSMIATriggerDBG "Front body controller: load shed PCSMIA trigger DBG";
CM_ SG_ 1349 VCFRONT_loadShedTAS "Front body controller: load shed TAS";
CM_ SG_ 1349 VCFRONT_loadShedBackStopBktCntDB "Front body controller: load shed back stop bkt cnt DBG";
CM_ SG_ 1349 VCFRONT_loadShedPCSLeakyBktCtDBG "Front body controller: load shed PCS leaky bkt ct DBG";
CM_ SG_ 1349 VCFRONT_loadShedUI "Front body controller: load shed UI";
CM_ SG_ 1349 VCFRONT_loadShedAutoPilot "Front body controller: load shed auto pilot";
CM_ BO_ 929 "Front body controller message: vehicle status";
CM_ SG_ 929 VCFRONT_vehicleStatusMuxIndex "Front body controller: vehicle status mux index";
CM_ SG_ 929 VCFRONT_vehicleStatusCounter "Front body controller: vehicle status counter";
CM_ SG_ 929 VCFRONT_vehicleStatusChecksum "Front body controller: vehicle status checksum";
CM_ SG_ 929 VCFRONT_preconditionRequest "Front body controller: precondition request";
CM_ SG_ 929 VCFRONT_APGlassHeaterState "Front body controller: AP glass heater state; raw 0 = signal not available (SNA)";
CM_ SG_ 929 VCFRONT_thermalSystemType "Front body controller: thermal system type; raw 1 = signal not available (SNA)";
CM_ SG_ 929 VCFRONT_standbySupplySupported "Front body controller: standby supply supported";
CM_ SG_ 929 VCFRONT_driverPresent "Front body controller: driver present";
CM_ SG_ 929 VCFRONT_passengerPresent "Front body controller: passenger present";
CM_ SG_ 929 VCFRONT_accPlusAvailable "Front body controller: acc plus available";
CM_ SG_ 929 VCFRONT_diPowerOnState "Front body controller: di power on state";
CM_ SG_ 929 VCFRONT_12vStatusForDrive "Front body controller: 12v status for drive";
CM_ SG_ 929 VCFRONT_dcr12VMilliOhms "Front body controller: dcr12 v milli ohms";
CM_ SG_ 929 VC_userPresenceState "User presence state";
CM_ SG_ 929 VCFRONT_factoryLimitsOverrideOk "Front body controller: factory limits override ok";
CM_ SG_ 929 VCFRONT_ota12VSupportRequest "Front body controller: ota12 v support request";
CM_ SG_ 929 VCFRONT_driverBuckleStatus "Front body controller: driver buckle status";
CM_ SG_ 929 VCFRONT_driverDoorStatus "Front body controller: driver door status";
CM_ SG_ 929 VCFRONT_driverUnbuckled "Front body controller: driver unbuckled; raw 2 = signal not available (SNA)";
CM_ SG_ 929 VCFRONT_passengerUnbuckled "Front body controller: passenger unbuckled; raw 2 = signal not available (SNA)";
CM_ SG_ 929 VCFRONT_2RowLeftUnbuckled "Front body controller: 2 row left unbuckled; raw 2 = signal not available (SNA)";
CM_ SG_ 929 VCFRONT_2RowCenterUnbuckled "Front body controller: 2 row center unbuckled; raw 2 = signal not available (SNA)";
CM_ SG_ 929 VCFRONT_2RowRightUnbuckled "Front body controller: 2 row right unbuckled; raw 2 = signal not available (SNA)";
CM_ SG_ 929 VCFRONT_pcsEFuseVoltage "Front body controller: pcs e fuse voltage; raw 1023 = signal not available (SNA)";
CM_ SG_ 929 VCFRONT_bmsHvChargeEnable "Front body controller: bms hv charge enable";
CM_ SG_ 929 VCFRONT_3RowLeftUnbuckled "Indication that the third row left passenger has unbuckled their seat belt; raw 2 = signal not available (SNA)";
CM_ SG_ 929 VCFRONT_3RowRightUnbuckled "Indication that the third row right passenger has unbuckled their seat belt; raw 2 = signal not available (SNA)";
CM_ SG_ 929 VCFRONT_maxBattHeatRejection "Radiator max heat rejection estimated at zero vehicle speed.";
CM_ SG_ 929 VCFRONT_hvacReqBattCoolOutTemp "Battery outlet coolant temp target to allow HVAC min comfort";
CM_ SG_ 929 VCFRONT_PCSCurrent "Front body controller: PCS current";
CM_ SG_ 929 VCFRONT_refSystemNominal "Front body controller: ref system nominal";
CM_ SG_ 929 VCFRONT_driverEnteredCabinEstima "Front body controller: driver entered cabin estimate DBG";
CM_ SG_ 929 VCFRONT_anySWEFuseActive "Front body controller: any SWE fuse active";
CM_ SG_ 929 VCFRONT_hpBattHeatingPowerTrgt "Reports the heat pump battery heating power target.";
CM_ BO_ 507 "Left body controller message: TLC status";
CM_ SG_ 507 VCLEFT_TLCStatusIndex "Left body controller: TLC status index";
CM_ SG_ 507 VCLEFT_TLCTemperature "Monitors board temperatures for electrical validation.; raw 128 = signal not available (SNA)";
CM_ SG_ 507 VCLEFT_TLCLeftTurnVoltage "Reports voltage for analysis of in field issues.; raw 255 = signal not available (SNA)";
CM_ SG_ 507 VCLEFT_TLCRightTurnVoltage "Reports voltage for analysis of in field issues.; raw 255 = signal not available (SNA)";
CM_ SG_ 507 VCLEFT_TLCState_LeftTurn "Reports trailer light status.; raw 5 = signal not available (SNA)";
CM_ SG_ 507 VCLEFT_TLCState_RightTurn "Reports trailer light status.; raw 5 = signal not available (SNA)";
CM_ SG_ 507 VCLEFT_TLCState_Tail "Reports trailer light status.; raw 5 = signal not available (SNA)";
CM_ SG_ 507 VCLEFT_TLCState_Stop "Reports trailer light status.; raw 5 = signal not available (SNA)";
CM_ SG_ 507 VCLEFT_TLCState_Fog "Reports trailer light status.; raw 5 = signal not available (SNA)";
CM_ SG_ 507 VCLEFT_TLCState_Reverse "Reports trailer light status.; raw 5 = signal not available (SNA)";
CM_ BO_ 290 "Left body controller message: door status2";
CM_ SG_ 290 VCLEFT_doorStatus2Index "Left body controller: door status2 index";
CM_ SG_ 290 VCLEFT_frontLatchRelDuty "Front left door latch motor duty cycle.";
CM_ SG_ 290 VCLEFT_BPillarCameraHeaterState "Indicates the state of the left b-pillar camera heater; raw 0 = signal not available (SNA)";
CM_ SG_ 290 VCLEFT_doorLatchAjarSwitchVoltag "Door latch switch voltage feeding switch logic";
CM_ SG_ 290 VCLEFT_doorLatchAjarSwitchV_0001 "Door latch switch voltage feeding switch logic";
CM_ SG_ 290 VCLEFT_BPillarCameraHeaterCurren "Current drawn by the left b-pillar camera heater; raw 63 = signal not available (SNA)";
CM_ SG_ 290 VCLEFT_mirrorTiltXOffset "Communicates post calibration position offset of left side view mirror tilt horizontal position";
CM_ SG_ 290 VCLEFT_mirrorTiltYOffset "Communicates post calibration position offset of left side view mirror tilt vertical position";
CM_ BO_ 626 "Left body controller message: epbm debug";
CM_ SG_ 626 VCLEFT_epbmDebugIndex "Left body controller: epbm debug index";
CM_ SG_ 626 VCLEFT_epbmCaliperState "Left body controller: epbm caliper state";
CM_ SG_ 626 VCLEFT_epbmMotorEnabled "Left body controller: epbm motor enabled";
CM_ SG_ 626 VCLEFT_epbMotorCurrent "Left body controller: epb motor current";
CM_ SG_ 626 VCLEFT_epbmApplyVoltage "Left body controller: epbm apply voltage";
CM_ SG_ 626 VCLEFT_epbmReleaseVoltage "Left body controller: epbm release voltage";
CM_ SG_ 626 VCLEFT_summonFaultReason "Electronic Parking Brake Monitors error code associated with previous summon failure.";
CM_ SG_ 626 VCLEFT_epbSummonState "Electronic Parking Brake Monitors reading of Electronic Parking Brake's summon state.";
CM_ SG_ 626 VCLEFT_epbmSummonState "Electronic Parking Brake Monitors summon state.";
CM_ SG_ 626 VCLEFT_epbUnitStatus "Electronic Parking Brake Monitors reading of Electronic Parking Brake's state.";
CM_ SG_ 626 VCLEFT_epbmFaultStatus "Electronic Parking Brake Monitors fault state.";
CM_ SG_ 626 VCLEFT_epbFaultStatus "Electronic Parking Brake Monitors reading of Electronic Parking Brake's fault state.";
CM_ SG_ 626 VCLEFT_epbmSystemStatus "Electronic Parking Brake Monitors reading of Electronic Parking Brake's state.";
CM_ SG_ 626 VCLEFT_epbmAutonomyBehavior "Left body controller: epbm autonomy behavior";
CM_ BO_ 1186 "Left body controller message: etc bluetooth status";
CM_ SG_ 1186 VCLEFT_etcBluetoothStatus "Left body controller: etc bluetooth status";
CM_ BO_ 642 "Left body controller message: hvac blower feedback";
CM_ SG_ 642 VCLEFT_hvacBlowerFeedbackIndex "Left body controller: hvac blower feedback index";
CM_ SG_ 642 VCLEFT_hvacBlowerEnabled "Left body controller: hvac blower enabled";
CM_ SG_ 642 VCLEFT_hvacBlowerOutputDuty "Left body controller: hvac blower output duty; raw 127 = signal not available (SNA)";
CM_ SG_ 642 VCLEFT_hvacBlowerRPMTarget "Left body controller: hvac blower RPM target; raw 1023 = signal not available (SNA)";
CM_ SG_ 642 VCLEFT_hvacBlowerRPMActual "Blower speed feedback";
CM_ SG_ 642 VCLEFT_hvacBlowerTorque "Left body controller: hvac blower torque; raw 1023 = signal not available (SNA)";
CM_ SG_ 642 VCLEFT_hvacBlowerFETTemp "Left body controller: hvac blower FET temp; raw 127 = signal not available (SNA)";
CM_ SG_ 642 VCLEFT_hvacBlowerIDc "Left body controller: hvac blower i dc; raw 127 = signal not available (SNA)";
CM_ SG_ 642 VCLEFT_hvacBlowerInitd "Left body controller: hvac blower initd";
CM_ SG_ 642 VCLEFT_hvacBlowerFault "Left body controller: hvac blower fault";
CM_ SG_ 642 VCLEFT_hvacBlowerLimitFETTemps "Left body controller: hvac blower limit FET temps";
CM_ SG_ 642 VCLEFT_hvacBlowerPowerOn "Left body controller: hvac blower power on";
CM_ SG_ 642 VCLEFT_hvacBlowerMotorID "Reports the ID of the HVAC blower motor";
CM_ BO_ 770 "Left body controller message: info";
CM_ SG_ 770 VCLEFT_infoIndex "Left body controller: info index";
CM_ SG_ 770 VCLEFT_infoBuildType "Left body controller: info build type";
CM_ SG_ 770 VCLEFT_infoBuildConfigId "Left body controller: info build config id";
CM_ SG_ 770 VCLEFT_infoHardwareId "Left body controller: info hardware id";
CM_ SG_ 770 VCLEFT_infoComponentId "Left body controller: info component id";
CM_ SG_ 770 VCLEFT_infoPcbaId "Left body controller: info pcba id";
CM_ SG_ 770 VCLEFT_infoAssemblyId "Left body controller: info assembly id; raw 255 = signal not available (SNA)";
CM_ SG_ 770 VCLEFT_infoUsageId "Left body controller: info usage id";
CM_ SG_ 770 VCLEFT_infoSubUsageId "Left body controller: info sub usage id";
CM_ SG_ 770 VCLEFT_infoAppCrc "Left body controller: info app crc";
CM_ SG_ 770 VCLEFT_infoLUMBARLAppCRC "Left body controller: info LUMBARL app CRC";
CM_ SG_ 770 VCLEFT_infoAppGitHash "Left body controller: info app git hash";
CM_ SG_ 770 VCLEFT_infoBootGitHash "Left body controller: info boot git hash";
CM_ SG_ 770 VCLEFT_infoPlatformType "Left body controller: info platform type";
CM_ SG_ 770 VCLEFT_infoBootUdsProtoVersion "Left body controller: info boot uds proto version";
CM_ SG_ 770 VCLEFT_infoBootCrc "Left body controller: info boot crc";
CM_ BO_ 292 "Left body controller message: liftgate leader request";
CM_ SG_ 292 VCLEFT_liftgateRequestAction "Action of dual strut PLG requested by the leader";
CM_ SG_ 292 VCLEFT_liftgateRequestTargetDuty "Left body controller: liftgate request target duty";
CM_ SG_ 292 VCLEFT_liftgateRequestTargetAngl "Left body controller: liftgate request target angle";
CM_ SG_ 292 VCLEFT_liftgateRequestTargetPara "Left body controller: liftgate request target param";
CM_ SG_ 292 VCLEFT_adaptiveLiftgateControlMo "Indicates if adaptive liftgate control mode is active";
CM_ SG_ 292 VCLEFT_liftgateReqObsDetMode "Pinch mode requrest by the PLG leader";
CM_ SG_ 292 VCLEFT_liftgateReqResetStrutCoun "Set strut count reset request from the leader";
CM_ SG_ 292 VCLEFT_liftgateReqClearCal "Request follower strut ro clear it calibration";
CM_ SG_ 292 VCLEFT_liftgateTargetTerminalSpe "Left body controller: liftgate target terminal speed";
CM_ SG_ 292 VCLEFT_liftgateReqCoastPercent "Reports the percentage of time to coast the strut.";
CM_ SG_ 292 VCLEFT_liftgateReqDutyScale "Reports the amount to scale duty from current value to ramp to for a LATCH_CURRENT_SCALED request";
CM_ BO_ 322 "Left body controller message: liftgate status";
CM_ SG_ 322 VCLEFT_liftgateStatusIndex "Left body controller: liftgate status index";
CM_ SG_ 322 VCLEFT_liftgateState "State of the power liftgate";
CM_ SG_ 322 VCLEFT_liftgateStoppingCondition "Stopping condition for the power liftgate";
CM_ SG_ 322 VCLEFT_liftgateMvmntNotAllowedCo "Movement not allowed condition for the power liftgate";
CM_ SG_ 322 VCLEFT_liftgatePositionCalibrate "Liftgate calibrated";
CM_ SG_ 322 VCLEFT_liftgateUIChimeRequest "Request from the liftgate module to sound a UI chime";
CM_ SG_ 322 VCLEFT_liftgatePhysicalChimeRequ "Request from the liftgate module to sound a physical chime";
CM_ SG_ 322 VCLEFT_liftgateEstimatedStrutTem "Left body controller: liftgate estimated strut temp";
CM_ SG_ 322 VCLEFT_liftgateStaticStrutMode "Static strut mode based on its velocity; raw 0 = signal not available (SNA)";
CM_ SG_ 322 VCLEFT_liftgateRequestSource "Movement request source for the power liftgate";
CM_ SG_ 322 VCLEFT_liftgateNewHeightNudge "Left body controller: liftgate new height nudge";
CM_ SG_ 322 VCLEFT_liftgateNewSaveHeight "Newly saved height of liftgate tip at max open";
CM_ SG_ 322 VCLEFT_liftgateGeofenceState "State of the geofence save process";
CM_ SG_ 322 VCLEFT_liftgateCloseWarnChimeReq "Left body controller: liftgate close warn chime request";
CM_ SG_ 322 VCLEFT_liftgateAboveCrossoverAng "Left body controller: liftgate above crossover angle";
CM_ SG_ 322 VCLEFT_liftgateLatchRequest "Reqeusts the liftgate latch to perform an action";
CM_ SG_ 322 VCLEFT_liftgateStrutDutyCycle "Left body controller: liftgate strut duty cycle";
CM_ SG_ 322 VCLEFT_liftgateStrutCurrent "Left body controller: liftgate strut current";
CM_ SG_ 322 VCLEFT_liftgatePosition "Liftgate position";
CM_ SG_ 322 VCLEFT_liftgateSpeed "Left body controller: liftgate speed";
CM_ SG_ 322 VCLEFT_liftgateHeight "Height of the liftgate tip above the ground";
CM_ SG_ 322 VCLEFT_liftgatePositionDiff "Left body controller: liftgate position diff";
BA_DEF_ BO_ "GenMsgCycleTime" INT 0 3600000;
BA_DEF_ BO_ "GenMsgSendType" ENUM "Cyclic","NotUsed","NotUsed","NotUsed","NotUsed","NotUsed","NotUsed","IfActive","NoMsgSendType","NotUsed";
BA_DEF_ BO_ "VFrameFormat" ENUM "StandardCAN","ExtendedCAN","reserved","J1939PG","reserved","reserved","reserved","reserved","reserved","reserved","reserved","reserved","reserved","reserved","StandardCAN_FD","ExtendedCAN_FD";
BA_DEF_ BO_ "CANFD_BRS" ENUM "0","1";
BA_DEF_ SG_ "GenSigSNA" STRING;
BA_DEF_ SG_ "SystemSignalLongSymbol" STRING;
BA_DEF_ SG_ "Confidence" ENUM "validated","plausible","layout-only","contradicted";
BA_DEF_DEF_ "GenMsgCycleTime" 0;
BA_DEF_DEF_ "GenMsgSendType" "NoMsgSendType";
BA_DEF_DEF_ "VFrameFormat" "StandardCAN";
BA_DEF_DEF_ "CANFD_BRS" "1";
BA_DEF_DEF_ "GenSigSNA" "";
BA_DEF_DEF_ "SystemSignalLongSymbol" "";
BA_DEF_DEF_ "Confidence" "layout-only";
BA_ "GenMsgCycleTime" BO_ 769 1000;
BA_ "GenMsgSendType" BO_ 769 0;
BA_ "GenMsgCycleTime" BO_ 1014 1000;
BA_ "GenMsgSendType" BO_ 1014 0;
BA_ "GenMsgCycleTime" BO_ 1013 100;
BA_ "GenMsgSendType" BO_ 1013 0;
BA_ "GenMsgCycleTime" BO_ 1801 294;
BA_ "GenMsgSendType" BO_ 1801 0;
BA_ "GenMsgCycleTime" BO_ 705 20;
BA_ "GenMsgSendType" BO_ 705 0;
BA_ "GenMsgCycleTime" BO_ 897 36;
BA_ "GenMsgSendType" BO_ 897 0;
BA_ "GenMsgCycleTime" BO_ 513 25;
BA_ "GenMsgSendType" BO_ 513 0;
BA_ "GenMsgCycleTime" BO_ 721 100;
BA_ "GenMsgSendType" BO_ 721 0;
BA_ "GenMsgCycleTime" BO_ 801 1000;
BA_ "GenMsgSendType" BO_ 801 0;
BA_ "GenMsgCycleTime" BO_ 1349 33;
BA_ "GenMsgSendType" BO_ 1349 0;
BA_ "GenMsgCycleTime" BO_ 929 50;
BA_ "GenMsgSendType" BO_ 929 0;
BA_ "GenMsgCycleTime" BO_ 507 5000;
BA_ "GenMsgSendType" BO_ 507 0;
BA_ "GenMsgCycleTime" BO_ 290 100;
BA_ "GenMsgSendType" BO_ 290 0;
BA_ "GenMsgCycleTime" BO_ 626 100;
BA_ "GenMsgSendType" BO_ 626 0;
BA_ "GenMsgCycleTime" BO_ 1186 1000;
BA_ "GenMsgSendType" BO_ 1186 0;
BA_ "GenMsgCycleTime" BO_ 642 100;
BA_ "GenMsgSendType" BO_ 642 0;
BA_ "GenMsgCycleTime" BO_ 770 1000;
BA_ "GenMsgSendType" BO_ 770 0;
BA_ "GenMsgCycleTime" BO_ 292 500;
BA_ "GenMsgSendType" BO_ 292 0;
BA_ "GenMsgCycleTime" BO_ 322 50;
BA_ "GenMsgSendType" BO_ 322 0;
BA_ "Confidence" SG_ 769 VCFRONT_infoIndex 1;
BA_ "Confidence" SG_ 769 VCFRONT_infoBuildType 0;
BA_ "Confidence" SG_ 769 VCFRONT_infoBuildConfigId 0;
BA_ "Confidence" SG_ 769 VCFRONT_infoHardwareId 0;
BA_ "Confidence" SG_ 769 VCFRONT_infoComponentId 0;
BA_ "Confidence" SG_ 769 VCFRONT_infoPcbaId 0;
BA_ "Confidence" SG_ 769 VCFRONT_infoAssemblyId 0;
BA_ "GenSigSNA" SG_ 769 VCFRONT_infoAssemblyId "255";
BA_ "Confidence" SG_ 769 VCFRONT_infoUsageId 0;
BA_ "Confidence" SG_ 769 VCFRONT_infoSubUsageId 0;
BA_ "Confidence" SG_ 769 VCFRONT_infoAppCrc 0;
BA_ "Confidence" SG_ 769 VC_infoHCMLAppCRC 0;
BA_ "Confidence" SG_ 769 VCFRONT_infoAppGitHash 0;
BA_ "Confidence" SG_ 769 VCFRONT_infoBootGitHash 0;
BA_ "Confidence" SG_ 769 VCFRONT_infoPlatformType 0;
BA_ "Confidence" SG_ 769 VCFRONT_infoBootUdsProtoVersion 0;
BA_ "Confidence" SG_ 769 VCFRONT_infoBootCrc 0;
BA_ "Confidence" SG_ 769 VC_infoHCMRAppCRC 0;
BA_ "Confidence" SG_ 769 VC_infoWiperAppCRC 0;
BA_ "Confidence" SG_ 1014 VCFRONT_lowBeamLeftStatus 0;
BA_ "GenSigSNA" SG_ 1014 VCFRONT_lowBeamLeftStatus "3";
BA_ "Confidence" SG_ 1014 VCFRONT_lowBeamRightStatus 0;
BA_ "GenSigSNA" SG_ 1014 VCFRONT_lowBeamRightStatus "3";
BA_ "Confidence" SG_ 1014 VCFRONT_highBeamLeftStatus 0;
BA_ "GenSigSNA" SG_ 1014 VCFRONT_highBeamLeftStatus "3";
BA_ "Confidence" SG_ 1014 VCFRONT_highBeamRightStatus 0;
BA_ "GenSigSNA" SG_ 1014 VCFRONT_highBeamRightStatus "3";
BA_ "Confidence" SG_ 1014 VCFRONT_DRLLeftStatus 0;
BA_ "GenSigSNA" SG_ 1014 VCFRONT_DRLLeftStatus "3";
BA_ "Confidence" SG_ 1014 VCFRONT_DRLRightStatus 0;
BA_ "GenSigSNA" SG_ 1014 VCFRONT_DRLRightStatus "3";
BA_ "Confidence" SG_ 1014 VCFRONT_fogLeftStatus 0;
BA_ "GenSigSNA" SG_ 1014 VCFRONT_fogLeftStatus "3";
BA_ "Confidence" SG_ 1014 VCFRONT_fogRightStatus 0;
BA_ "GenSigSNA" SG_ 1014 VCFRONT_fogRightStatus "3";
BA_ "Confidence" SG_ 1014 VCFRONT_sideMarkersStatus 0;
BA_ "GenSigSNA" SG_ 1014 VCFRONT_sideMarkersStatus "3";
BA_ "Confidence" SG_ 1014 VCFRONT_sideRepeaterLeftStatus 0;
BA_ "GenSigSNA" SG_ 1014 VCFRONT_sideRepeaterLeftStatus "3";
BA_ "Confidence" SG_ 1014 VCFRONT_sideRepeaterRightStatus 0;
BA_ "GenSigSNA" SG_ 1014 VCFRONT_sideRepeaterRightStatus "3";
BA_ "Confidence" SG_ 1014 VCFRONT_turnSignalLeftStatus 0;
BA_ "GenSigSNA" SG_ 1014 VCFRONT_turnSignalLeftStatus "3";
BA_ "Confidence" SG_ 1014 VCFRONT_turnSignalRightStatus 0;
BA_ "GenSigSNA" SG_ 1014 VCFRONT_turnSignalRightStatus "3";
BA_ "Confidence" SG_ 1014 VCFRONT_parkLeftStatus 0;
BA_ "GenSigSNA" SG_ 1014 VCFRONT_parkLeftStatus "3";
BA_ "Confidence" SG_ 1014 VCFRONT_parkRightStatus 0;
BA_ "GenSigSNA" SG_ 1014 VCFRONT_parkRightStatus "3";
BA_ "Confidence" SG_ 1014 VCFRONT_lowBeamLeftReadyForAimin 0;
BA_ "SystemSignalLongSymbol" SG_ 1014 VCFRONT_lowBeamLeftReadyForAimin "VCFRONT_lowBeamLeftReadyForAiming";
BA_ "Confidence" SG_ 1014 VCFRONT_lowBeamRightReadyForAimi 0;
BA_ "SystemSignalLongSymbol" SG_ 1014 VCFRONT_lowBeamRightReadyForAimi "VCFRONT_lowBeamRightReadyForAiming";
BA_ "Confidence" SG_ 1014 VCFRONT_lowBeamsOnForDRL 0;
BA_ "Confidence" SG_ 1014 VC_rightHeadlampHealth 0;
BA_ "Confidence" SG_ 1014 VC_leftHeadlampHealth 0;
BA_ "Confidence" SG_ 1014 VCFRONT_lightStatusMuxIndex 1;
BA_ "Confidence" SG_ 1014 VCFRONT_isAdaptiveHighBeamAvaila 0;
BA_ "SystemSignalLongSymbol" SG_ 1014 VCFRONT_isAdaptiveHighBeamAvaila "VCFRONT_isAdaptiveHighBeamAvailable";
BA_ "Confidence" SG_ 1014 VCFRONT_isAdaptiveHighBeamFaulte 0;
BA_ "SystemSignalLongSymbol" SG_ 1014 VCFRONT_isAdaptiveHighBeamFaulte "VCFRONT_isAdaptiveHighBeamFaulted";
BA_ "Confidence" SG_ 1014 VCFRONT_isBendLightingAvailable 0;
BA_ "Confidence" SG_ 1014 VCFRONT_advancedDrivingBeamStatu 0;
BA_ "SystemSignalLongSymbol" SG_ 1014 VCFRONT_advancedDrivingBeamStatu "VCFRONT_advancedDrivingBeamStatus";
BA_ "Confidence" SG_ 1014 VCFRONT_headlampBendAngle 0;
BA_ "Confidence" SG_ 1014 VCFRONT_headlampRoadClass 0;
BA_ "Confidence" SG_ 1013 VCFRONT_indicatorLeftRequest 0;
BA_ "Confidence" SG_ 1013 VCFRONT_indicatorRightRequest 0;
BA_ "Confidence" SG_ 1013 VCFRONT_hazardLightRequest 0;
BA_ "Confidence" SG_ 1013 VCFRONT_ambientLightingBrightnes 0;
BA_ "GenSigSNA" SG_ 1013 VCFRONT_ambientLightingBrightnes "255";
BA_ "Confidence" SG_ 1013 VCFRONT_switchLightingBrightness 0;
BA_ "GenSigSNA" SG_ 1013 VCFRONT_switchLightingBrightness "255";
BA_ "Confidence" SG_ 1013 VCFRONT_courtesyLightingRequest 0;
BA_ "Confidence" SG_ 1013 VCFRONT_hazardSwitchBacklight 0;
BA_ "Confidence" SG_ 1013 VCFRONT_highBeamControlState 0;
BA_ "Confidence" SG_ 1013 VCFRONT_dynamicBrakeLightState 0;
BA_ "Confidence" SG_ 1013 VCFRONT_lightingCoreState 0;
BA_ "GenSigSNA" SG_ 1013 VCFRONT_lightingCoreState "15";
BA_ "Confidence" SG_ 1013 VCFRONT_intHighBeamsFunctionStat 0;
BA_ "SystemSignalLongSymbol" SG_ 1013 VCFRONT_intHighBeamsFunctionStat "VCFRONT_intHighBeamsFunctionState";
BA_ "Confidence" SG_ 1013 VCFRONT_latchedHighBeamsFunction 0;
BA_ "SystemSignalLongSymbol" SG_ 1013 VCFRONT_latchedHighBeamsFunction "VCFRONT_latchedHighBeamsFunctionState";
BA_ "Confidence" SG_ 1013 VCFRONT_frontFogFunctionState 0;
BA_ "Confidence" SG_ 1013 VCFRONT_headlightsReadyOrTimedOu 0;
BA_ "SystemSignalLongSymbol" SG_ 1013 VCFRONT_headlightsReadyOrTimedOu "VCFRONT_headlightsReadyOrTimedOut";
BA_ "Confidence" SG_ 1013 VCFRONT_turnIndicatorStalk 0;
BA_ "GenSigSNA" SG_ 1013 VCFRONT_turnIndicatorStalk "3";
BA_ "Confidence" SG_ 1013 VCFRONT_highBeamLatchingState 0;
BA_ "GenSigSNA" SG_ 1013 VCFRONT_highBeamLatchingState "0";
BA_ "Confidence" SG_ 1013 VCFRONT_lightingCustomState 0;
BA_ "Confidence" SG_ 1013 VC_fastFlashHazardsActive 0;
BA_ "Confidence" SG_ 1013 VCFRONT_indicatorLeftInternal 0;
BA_ "Confidence" SG_ 1013 VCFRONT_indicatorRightInternal 0;
BA_ "Confidence" SG_ 1801 VCFRONT_logging0point1HzIndex 1;
BA_ "Confidence" SG_ 1801 VC_hcmlFactoryOfOrigin 0;
BA_ "Confidence" SG_ 1801 VC_hcmlHellaPartNumberStatus 0;
BA_ "Confidence" SG_ 1801 VC_hcmlHellaPartNumber 0;
BA_ "Confidence" SG_ 1801 VC_hcmlCurrentBinMappingType 0;
BA_ "Confidence" SG_ 1801 VC_hcmlCurrentBin0Value 0;
BA_ "GenSigSNA" SG_ 1801 VC_hcmlCurrentBin0Value "0";
BA_ "Confidence" SG_ 1801 VC_hcmlCurrentBin1Value 0;
BA_ "GenSigSNA" SG_ 1801 VC_hcmlCurrentBin1Value "0";
BA_ "Confidence" SG_ 1801 VC_hcmlCurrentBin2Value 0;
BA_ "GenSigSNA" SG_ 1801 VC_hcmlCurrentBin2Value "0";
BA_ "Confidence" SG_ 1801 VC_hcmlCurrentBin3Value 0;
BA_ "GenSigSNA" SG_ 1801 VC_hcmlCurrentBin3Value "0";
BA_ "Confidence" SG_ 1801 VC_hcmlCurrentBin4Value 0;
BA_ "GenSigSNA" SG_ 1801 VC_hcmlCurrentBin4Value "0";
BA_ "Confidence" SG_ 1801 VC_hcmlCurrentBin5Value 0;
BA_ "GenSigSNA" SG_ 1801 VC_hcmlCurrentBin5Value "0";
BA_ "Confidence" SG_ 1801 VC_hcmlRegionAndSide 0;
BA_ "GenSigSNA" SG_ 1801 VC_hcmlRegionAndSide "0";
BA_ "Confidence" SG_ 1801 VC_hcmrFactoryOfOrigin 0;
BA_ "Confidence" SG_ 1801 VC_hcmrHellaPartNumberStatus 0;
BA_ "Confidence" SG_ 1801 VC_hcmrHellaPartNumber 0;
BA_ "Confidence" SG_ 1801 VC_hcmrCurrentBinMappingType 0;
BA_ "Confidence" SG_ 1801 VC_hcmrCurrentBin0Value 0;
BA_ "GenSigSNA" SG_ 1801 VC_hcmrCurrentBin0Value "0";
BA_ "Confidence" SG_ 1801 VC_hcmrCurrentBin1Value 0;
BA_ "GenSigSNA" SG_ 1801 VC_hcmrCurrentBin1Value "0";
BA_ "Confidence" SG_ 1801 VC_hcmrCurrentBin2Value 0;
BA_ "GenSigSNA" SG_ 1801 VC_hcmrCurrentBin2Value "0";
BA_ "Confidence" SG_ 1801 VC_hcmrCurrentBin3Value 0;
BA_ "GenSigSNA" SG_ 1801 VC_hcmrCurrentBin3Value "0";
BA_ "Confidence" SG_ 1801 VC_hcmrCurrentBin4Value 0;
BA_ "GenSigSNA" SG_ 1801 VC_hcmrCurrentBin4Value "0";
BA_ "Confidence" SG_ 1801 VC_hcmrCurrentBin5Value 0;
BA_ "GenSigSNA" SG_ 1801 VC_hcmrCurrentBin5Value "0";
BA_ "Confidence" SG_ 1801 VC_hcmrRegionAndSide 0;
BA_ "GenSigSNA" SG_ 1801 VC_hcmrRegionAndSide "0";
BA_ "Confidence" SG_ 705 VCFRONT_logging10HzIndex 1;
BA_ "Confidence" SG_ 705 VCFRONT_pumpBatteryOutVoltage 0;
BA_ "Confidence" SG_ 705 VCFRONT_pumpPowertrainOutVoltage 0;
BA_ "Confidence" SG_ 705 VCFRONT_pumpBatteryInitd 0;
BA_ "Confidence" SG_ 705 VCFRONT_pumpPowertrainInitd 0;
BA_ "Confidence" SG_ 705 VCFRONT_pumpBatteryEnabled 0;
BA_ "Confidence" SG_ 705 VCFRONT_pumpPowertrainEnabled 0;
BA_ "Confidence" SG_ 705 VCFRONT_pumpBatteryPowerOn 0;
BA_ "Confidence" SG_ 705 VCFRONT_pumpPowertrainPowerOn 0;
BA_ "Confidence" SG_ 705 VCFRONT_pumpsWake 0;
BA_ "Confidence" SG_ 705 VCFRONT_pumpBatSpiError 0;
BA_ "Confidence" SG_ 705 VCFRONT_pumpPtSpiError 0;
BA_ "Confidence" SG_ 705 VCFRONT_coolantFlowChillerActual 0;
BA_ "Confidence" SG_ 705 VCFRONT_radiatorFanOutVoltage 0;
BA_ "Confidence" SG_ 705 VCFRONT_radiatorFanInitd 0;
BA_ "Confidence" SG_ 705 VCFRONT_radiatorFanEnabled 0;
BA_ "Confidence" SG_ 705 VCFRONT_radiatorFanPowerOn 0;
BA_ "Confidence" SG_ 705 VCFRONT_radiatorFanPhaseCurrent 0;
BA_ "Confidence" SG_ 705 VCFRONT_radiatorFanPhaseIMax 0;
BA_ "Confidence" SG_ 705 VCFRONT_thmlFanSpiError 0;
BA_ "Confidence" SG_ 705 VCFRONT_chargeTrapNominalCOP1Bat 0;
BA_ "SystemSignalLongSymbol" SG_ 705 VCFRONT_chargeTrapNominalCOP1Bat "VCFRONT_chargeTrapNominalCOP1BattHeat";
BA_ "Confidence" SG_ 705 VCFRONT_chargeTrapNominalCOP1Chi 0;
BA_ "SystemSignalLongSymbol" SG_ 705 VCFRONT_chargeTrapNominalCOP1Chi "VCFRONT_chargeTrapNominalCOP1ChillerBattHeat";
BA_ "Confidence" SG_ 705 VCFRONT_COP1OilWarmingNeeded 0;
BA_ "Confidence" SG_ 897 VCFRONT_logging1HzIndex 1;
BA_ "Confidence" SG_ 897 VCFRONT_modeTransitionID 0;
BA_ "Confidence" SG_ 897 VCFRONT_modeDesired 0;
BA_ "Confidence" SG_ 897 VCFRONT_targetPTActiveCool 0;
BA_ "Confidence" SG_ 897 VCFRONT_targetPtOptionalActiveCo 0;
BA_ "SystemSignalLongSymbol" SG_ 897 VCFRONT_targetPtOptionalActiveCo "VCFRONT_targetPtOptionalActiveCool";
BA_ "Confidence" SG_ 897 VCFRONT_targetPTPassive 0;
BA_ "Confidence" SG_ 897 VCFRONT_targetBatActiveCool 0;
BA_ "Confidence" SG_ 897 VCFRONT_targetBatOptionalActiveC 0;
BA_ "SystemSignalLongSymbol" SG_ 897 VCFRONT_targetBatOptionalActiveC "VCFRONT_targetBatOptionalActiveCool";
BA_ "Confidence" SG_ 897 VCFRONT_targetBatPassive 0;
BA_ "Confidence" SG_ 897 VCFRONT_targetBatActiveHeat 0;
BA_ "Confidence" SG_ 897 VCFRONT_condenserPressureLimit 0;
BA_ "Confidence" SG_ 897 VCFRONT_fanDemandCondenser 0;
BA_ "Confidence" SG_ 897 VCFRONT_fanDemandRadiator 0;
BA_ "Confidence" SG_ 897 VCFRONT_tempRefrigSuction 0;
BA_ "GenSigSNA" SG_ 897 VCFRONT_tempRefrigSuction "255";
BA_ "Confidence" SG_ 897 VCFRONT_pumpBatteryFETTemp 0;
BA_ "GenSigSNA" SG_ 897 VCFRONT_pumpBatteryFETTemp "255";
BA_ "Confidence" SG_ 897 VCFRONT_pumpPowertrainFETTemp 0;
BA_ "GenSigSNA" SG_ 897 VCFRONT_pumpPowertrainFETTemp "255";
BA_ "Confidence" SG_ 897 VCFRONT_radiatorFanFETTemp 0;
BA_ "GenSigSNA" SG_ 897 VCFRONT_radiatorFanFETTemp "255";
BA_ "Confidence" SG_ 897 VCFRONT_radiatorFanRunReason 0;
BA_ "Confidence" SG_ 897 VCFRONT_coolantValveModeWrong 0;
BA_ "Confidence" SG_ 897 VCFRONT_coolantTempBasedMode 0;
BA_ "Confidence" SG_ 897 VCFRONT_coolantValveRecalReason 0;
BA_ "Confidence" SG_ 897 VCFRONT_coolantValveCountRange 0;
BA_ "GenSigSNA" SG_ 897 VCFRONT_coolantValveCountRange "1023";
BA_ "Confidence" SG_ 897 VCFRONT_coolantValveAngleDrift 0;
BA_ "Confidence" SG_ 897 VCFRONT_coolantValveRecalCount 0;
BA_ "Confidence" SG_ 897 VCFRONT_coolantValveWindupEst 0;
BA_ "Confidence" SG_ 897 VCFRONT_coolantValveRadBypass 0;
BA_ "GenSigSNA" SG_ 897 VCFRONT_coolantValveRadBypass "127";
BA_ "Confidence" SG_ 897 VCFRONT_usingModeledPs 0;
BA_ "Confidence" SG_ 897 VCFRONT_usingModeledPd 0;
BA_ "Confidence" SG_ 897 VCFRONT_usingModeledPl 0;
BA_ "Confidence" SG_ 897 VCFRONT_usingModeledTs 0;
BA_ "Confidence" SG_ 897 VCFRONT_usingModeledTd 0;
BA_ "Confidence" SG_ 897 VCFRONT_usingModeledTl 0;
BA_ "Confidence" SG_ 897 VCFRONT_hpChargeCableType 0;
BA_ "Confidence" SG_ 897 VCFRONT_subcoolActual 0;
BA_ "Confidence" SG_ 897 VCFRONT_hpSubcoolTarget 0;
BA_ "Confidence" SG_ 897 VCFRONT_CMPDischargeSuperheat 0;
BA_ "Confidence" SG_ 897 VCFRONT_hpCOP 0;
BA_ "Confidence" SG_ 897 VCFRONT_lowSideWattsLift 0;
BA_ "Confidence" SG_ 897 VCFRONT_tempSuperheatActual 0;
BA_ "GenSigSNA" SG_ 897 VCFRONT_tempSuperheatActual "1023";
BA_ "Confidence" SG_ 897 VCFRONT_tempSuperheatTarget 0;
BA_ "Confidence" SG_ 897 VCFRONT_refrigerantHasBeenFilled 0;
BA_ "Confidence" SG_ 897 VCFRONT_refCommissionStatus 0;
BA_ "Confidence" SG_ 897 VCFRONT_LCCPurgeActive 0;
BA_ "Confidence" SG_ 897 VCFRONT_exteriorQuietModeEnabled 0;
BA_ "Confidence" SG_ 897 VCFRONT_exteriorQuietModeAllowed 0;
BA_ "Confidence" SG_ 897 VCFRONT_CCQdotFdFrwrdTarget 0;
BA_ "Confidence" SG_ 897 VCFRONT_CCQdotFdbk 0;
BA_ "Confidence" SG_ 897 VCFRONT_CCQdotActual 0;
BA_ "Confidence" SG_ 897 VCFRONT_evapFdFrwrdTarget 0;
BA_ "Confidence" SG_ 897 VCFRONT_evapFdbk 0;
BA_ "Confidence" SG_ 897 VCFRONT_DIQdotA 0;
BA_ "Confidence" SG_ 897 VCFRONT_evapFdFrwrdTargetMinimum 0;
BA_ "Confidence" SG_ 897 VCFRONT_passiveCoolingState 0;
BA_ "Confidence" SG_ 897 VCFRONT_totalLoadCoolingDominant 0;
BA_ "Confidence" SG_ 897 VCFRONT_feedfwdLoadCoolingDomina 0;
BA_ "SystemSignalLongSymbol" SG_ 897 VCFRONT_feedfwdLoadCoolingDomina "VCFRONT_feedfwdLoadCoolingDominant";
BA_ "Confidence" SG_ 897 VCFRONT_modelLoadCoolingDominant 0;
BA_ "Confidence" SG_ 897 VCFRONT_hpPotentialLowRefrig 0;
BA_ "Confidence" SG_ 897 VCFRONT_hpRefrigerantPurgeState 0;
BA_ "Confidence" SG_ 897 VCFRONT_estPressureLiq 0;
BA_ "Confidence" SG_ 897 VCFRONT_estPressureSuct 0;
BA_ "Confidence" SG_ 897 VCFRONT_estPressureDisch 0;
BA_ "Confidence" SG_ 897 VCFRONT_estTempLiq 0;
BA_ "Confidence" SG_ 897 VCFRONT_estTempSuct 0;
BA_ "Confidence" SG_ 897 VCFRONT_estTempDisch 0;
BA_ "Confidence" SG_ 897 VCFRONT_estCompressorRpm 0;
BA_ "Confidence" SG_ 897 VCFRONT_estQLift 0;
BA_ "Confidence" SG_ 897 VCFRONT_cycleModelConverged 0;
BA_ "Confidence" SG_ 897 VCFRONT_compStandbyCoastDownMode 0;
BA_ "Confidence" SG_ 897 VCFRONT_compStandbyShowroomMode 0;
BA_ "Confidence" SG_ 897 VCFRONT_chillerExvCalibOffset 0;
BA_ "Confidence" SG_ 897 VCFRONT_evapExvCalibOffset 0;
BA_ "Confidence" SG_ 897 VCFRONT_recircExvCalibOffset 0;
BA_ "Confidence" SG_ 897 VCFRONT_lccExvCalibOffset 0;
BA_ "Confidence" SG_ 897 VCFRONT_ccLeftExvCalibOffset 0;
BA_ "Confidence" SG_ 897 VCFRONT_ccRightExvCalibOffset 0;
BA_ "Confidence" SG_ 897 VCFRONT_chillerEXVControlState 0;
BA_ "Confidence" SG_ 897 VCFRONT_evapEXVControlState 0;
BA_ "Confidence" SG_ 897 VCFRONT_recircEXVControlState 0;
BA_ "Confidence" SG_ 897 VCFRONT_lccEXVControlState 0;
BA_ "Confidence" SG_ 897 VCFRONT_cclEXVControlState 0;
BA_ "Confidence" SG_ 897 VCFRONT_ccrEXVControlState 0;
BA_ "Confidence" SG_ 897 VCFRONT_chillerExvCalibFailed 0;
BA_ "Confidence" SG_ 897 VCFRONT_evapExvCalibFailed 0;
BA_ "Confidence" SG_ 897 VCFRONT_recircExvCalibFailed 0;
BA_ "Confidence" SG_ 897 VCFRONT_lccExvCalibFailed 0;
BA_ "Confidence" SG_ 897 VCFRONT_ccLeftExvCalibFailed 0;
BA_ "Confidence" SG_ 897 VCFRONT_ccRightExvCalibFailed 0;
BA_ "Confidence" SG_ 897 VCFRONT_ambientTempSniffActive 0;
BA_ "Confidence" SG_ 897 VCFRONT_ambientTempPassiveSniffi 0;
BA_ "SystemSignalLongSymbol" SG_ 897 VCFRONT_ambientTempPassiveSniffi "VCFRONT_ambientTempPassiveSniffing";
BA_ "Confidence" SG_ 897 VCFRONT_ambientTempRadSampling 0;
BA_ "Confidence" SG_ 897 VCFRONT_ambientTempSpeedSampling 0;
BA_ "Confidence" SG_ 897 VCFRONT_feedFwdMDotEvaporator 0;
BA_ "Confidence" SG_ 897 VCFRONT_hpCabinHeatBatteryHeatAm 0;
BA_ "SystemSignalLongSymbol" SG_ 897 VCFRONT_hpCabinHeatBatteryHeatAm "VCFRONT_hpCabinHeatBatteryHeatAmbSrc";
BA_ "Confidence" SG_ 897 VCFRONT_hpCabinHeatBatteryHeatCO 0;
BA_ "SystemSignalLongSymbol" SG_ 897 VCFRONT_hpCabinHeatBatteryHeatCO "VCFRONT_hpCabinHeatBatteryHeatCOP1";
BA_ "Confidence" SG_ 897 VCFRONT_feedFwdMDotCabinCondense 0;
BA_ "SystemSignalLongSymbol" SG_ 897 VCFRONT_feedFwdMDotCabinCondense "VCFRONT_feedFwdMDotCabinCondenser";
BA_ "Confidence" SG_ 897 VCFRONT_feedBackEvapTempControll 0;
BA_ "SystemSignalLongSymbol" SG_ 897 VCFRONT_feedBackEvapTempControll "VCFRONT_feedBackEvapTempController";
BA_ "Confidence" SG_ 897 VCFRONT_feedBackDuctTempControll 0;
BA_ "SystemSignalLongSymbol" SG_ 897 VCFRONT_feedBackDuctTempControll "VCFRONT_feedBackDuctTempController";
BA_ "Confidence" SG_ 897 VCFRONT_isSolenoidAllowed 0;
BA_ "Confidence" SG_ 897 VCFRONT_maxChillerCoolingPower 0;
BA_ "Confidence" SG_ 897 VCFRONT_fanControlRadCanCool 0;
BA_ "Confidence" SG_ 897 VCFRONT_fanControlFeedfwdActive 0;
BA_ "Confidence" SG_ 897 VCFRONT_fanControlRadiatorUa 0;
BA_ "Confidence" SG_ 897 VCFRONT_fanControlRadiatorInletT 0;
BA_ "SystemSignalLongSymbol" SG_ 897 VCFRONT_fanControlRadiatorInletT "VCFRONT_fanControlRadiatorInletTemp";
BA_ "Confidence" SG_ 897 VCFRONT_hpASBatteryHeatingAllowe 0;
BA_ "SystemSignalLongSymbol" SG_ 897 VCFRONT_hpASBatteryHeatingAllowe "VCFRONT_hpASBatteryHeatingAllowed";
BA_ "Confidence" SG_ 897 VCFRONT_hpCOP1BatteryHeatingAllo 0;
BA_ "SystemSignalLongSymbol" SG_ 897 VCFRONT_hpCOP1BatteryHeatingAllo "VCFRONT_hpCOP1BatteryHeatingAllowed";
BA_ "Confidence" SG_ 897 VCFRONT_hpCabinHeatScavengeOnly 0;
BA_ "Confidence" SG_ 897 VCFRONT_hpCabinHeatAmbientSource 0;
BA_ "Confidence" SG_ 897 VCFRONT_hpCabinHeatReheatScaveng 0;
BA_ "SystemSignalLongSymbol" SG_ 897 VCFRONT_hpCabinHeatReheatScaveng "VCFRONT_hpCabinHeatReheatScavenge";
BA_ "Confidence" SG_ 897 VCFRONT_hpCabinHeatReheatAmbient 0;
BA_ "SystemSignalLongSymbol" SG_ 897 VCFRONT_hpCabinHeatReheatAmbient "VCFRONT_hpCabinHeatReheatAmbientSource";
BA_ "Confidence" SG_ 897 VCFRONT_hpCabinHeatBlend 0;
BA_ "Confidence" SG_ 897 VCFRONT_hpCabinHeatCOP1 0;
BA_ "Confidence" SG_ 897 VCFRONT_hpCabinHeatBatteryHeatRe 0;
BA_ "SystemSignalLongSymbol" SG_ 897 VCFRONT_hpCabinHeatBatteryHeatRe "VCFRONT_hpCabinHeatBatteryHeatReheatAmbSrc";
BA_ "Confidence" SG_ 897 VCFRONT_hpCabinHeatBatteryCoolRe 0;
BA_ "SystemSignalLongSymbol" SG_ 897 VCFRONT_hpCabinHeatBatteryCoolRe "VCFRONT_hpCabinHeatBatteryCoolReheat";
BA_ "Confidence" SG_ 897 VCFRONT_hpCabinCoolEvaporator 0;
BA_ "Confidence" SG_ 897 VCFRONT_hpCabinCoolEvaporatorReh 0;
BA_ "SystemSignalLongSymbol" SG_ 897 VCFRONT_hpCabinCoolEvaporatorReh "VCFRONT_hpCabinCoolEvaporatorReheat";
BA_ "Confidence" SG_ 897 VCFRONT_hpBatteryHeatAmbientSour 0;
BA_ "SystemSignalLongSymbol" SG_ 897 VCFRONT_hpBatteryHeatAmbientSour "VCFRONT_hpBatteryHeatAmbientSource";
BA_ "Confidence" SG_ 897 VCFRONT_hpBatteryHeatCOP1 0;
BA_ "Confidence" SG_ 897 VCFRONT_hpBatteryCool 0;
BA_ "Confidence" SG_ 897 VCFRONT_hpBatteryCoolCabinConden 0;
BA_ "SystemSignalLongSymbol" SG_ 897 VCFRONT_hpBatteryCoolCabinConden "VCFRONT_hpBatteryCoolCabinCondenserCD";
BA_ "Confidence" SG_ 897 VCFRONT_hpBatteryCoolCabinC_0001 0;
BA_ "SystemSignalLongSymbol" SG_ 897 VCFRONT_hpBatteryCoolCabinC_0001 "VCFRONT_hpBatteryCoolCabinCondenserHD";
BA_ "Confidence" SG_ 897 VCFRONT_hpBatteryCoolCabinReheat 0;
BA_ "Confidence" SG_ 897 VCFRONT_hpBatteryCoolEvaporator 0;
BA_ "Confidence" SG_ 897 VCFRONT_suctionSuperheatEstTsSNA 0;
BA_ "Confidence" SG_ 897 VCFRONT_tempRefrigSuctionEst 0;
BA_ "Confidence" SG_ 897 VCFRONT_hpBattOverTempHvacDisabl 0;
BA_ "SystemSignalLongSymbol" SG_ 897 VCFRONT_hpBattOverTempHvacDisabl "VCFRONT_hpBattOverTempHvacDisable";
BA_ "Confidence" SG_ 897 VCFRONT_hpDiagLouverCalib 0;
BA_ "Confidence" SG_ 897 VCFRONT_hpDiagHighSideNotNominal 0;
BA_ "Confidence" SG_ 897 VCFRONT_hpForceModeRadClear 0;
BA_ "Confidence" SG_ 897 VCFRONT_estPressureDischargeSat 0;
BA_ "Confidence" SG_ 897 VCFRONT_tempRefrigLiquid 0;
BA_ "GenSigSNA" SG_ 897 VCFRONT_tempRefrigLiquid "2047";
BA_ "Confidence" SG_ 897 VCFRONT_totalBattHeatingPower 0;
BA_ "Confidence" SG_ 897 VCFRONT_hpPotentialFrozenRadiato 0;
BA_ "SystemSignalLongSymbol" SG_ 897 VCFRONT_hpPotentialFrozenRadiato "VCFRONT_hpPotentialFrozenRadiator";
BA_ "Confidence" SG_ 897 VCFRONT_passiveSeriesRegOn 0;
BA_ "Confidence" SG_ 897 VCFRONT_passiveDemandRadBypass 0;
BA_ "Confidence" SG_ 897 VCFRONT_targetLccActiveCoolCap 0;
BA_ "Confidence" SG_ 897 VCFRONT_targetLccActiveCoolEff 0;
BA_ "Confidence" SG_ 897 VCFRONT_coolantValveDailyAngleTr 0;
BA_ "SystemSignalLongSymbol" SG_ 897 VCFRONT_coolantValveDailyAngleTr "VCFRONT_coolantValveDailyAngleTravel";
BA_ "Confidence" SG_ 897 VCFRONT_dischargePressureLimit 0;
BA_ "Confidence" SG_ 897 VCFRONT_radMovementBlockActive 0;
BA_ "Confidence" SG_ 897 VCFRONT_radBypassMoveReason 0;
BA_ "Confidence" SG_ 897 VCFRONT_hpBattHeatingPower 0;
BA_ "Confidence" SG_ 897 VCFRONT_tempCoolantRadOutletEstS 0;
BA_ "SystemSignalLongSymbol" SG_ 897 VCFRONT_tempCoolantRadOutletEstS "VCFRONT_tempCoolantRadOutletEstStatus";
BA_ "Confidence" SG_ 897 VCFRONT_targetBatActiveCoolSourc 0;
BA_ "SystemSignalLongSymbol" SG_ 897 VCFRONT_targetBatActiveCoolSourc "VCFRONT_targetBatActiveCoolSource";
BA_ "Confidence" SG_ 897 VCFRONT_targetPTActiveCoolSource 0;
BA_ "Confidence" SG_ 897 VCFRONT_hpColdStagnationLimit 0;
BA_ "Confidence" SG_ 897 VCFRONT_hpHotStagnationLimit 0;
BA_ "Confidence" SG_ 897 VCFRONT_hpCompFlowIndex 0;
BA_ "Confidence" SG_ 897 VCFRONT_hpCompFlowIndexFiltered 0;
BA_ "Confidence" SG_ 897 VCFRONT_subcoolEstTlSNA 0;
BA_ "Confidence" SG_ 897 VCFRONT_subcoolEstPlSNA 0;
BA_ "Confidence" SG_ 897 VCFRONT_tempRefrigLiquidEst 0;
BA_ "Confidence" SG_ 897 VCFRONT_pressureRefrigLiquidEst 0;
BA_ "Confidence" SG_ 897 VCFRONT_cmpIsentropicCheckPassed 0;
BA_ "Confidence" SG_ 897 VCFRONT_louverPosReason 0;
BA_ "Confidence" SG_ 897 VCFRONT_hpEnergyFlowIndex 0;
BA_ "Confidence" SG_ 897 VCFRONT_hpEnergyFlowIndexFiltere 0;
BA_ "SystemSignalLongSymbol" SG_ 897 VCFRONT_hpEnergyFlowIndexFiltere "VCFRONT_hpEnergyFlowIndexFiltered";
BA_ "Confidence" SG_ 897 VCFRONT_ductLeftAtSS 0;
BA_ "Confidence" SG_ 897 VCFRONT_ductRightAtSS 0;
BA_ "Confidence" SG_ 897 VCFRONT_minCompressorRPMAllowed 0;
BA_ "Confidence" SG_ 897 VCFRONT_ccRefrigerantMassFlow 0;
BA_ "Confidence" SG_ 897 VCFRONT_highSideDpResidual 0;
BA_ "Confidence" SG_ 897 VCFRONT_abnormalHighSuctionSuper 0;
BA_ "SystemSignalLongSymbol" SG_ 897 VCFRONT_abnormalHighSuctionSuper "VCFRONT_abnormalHighSuctionSuperheat";
BA_ "Confidence" SG_ 897 VCFRONT_coolantValveAngleTravel 0;
BA_ "Confidence" SG_ 897 VCFRONT_chargeShuttleType 0;
BA_ "Confidence" SG_ 897 VCFRONT_hpRefrigTempSensorCheckC 0;
BA_ "SystemSignalLongSymbol" SG_ 897 VCFRONT_hpRefrigTempSensorCheckC "VCFRONT_hpRefrigTempSensorCheckCanFire";
BA_ "Confidence" SG_ 897 VCFRONT_hpRefrigPressureSensorCh 0;
BA_ "SystemSignalLongSymbol" SG_ 897 VCFRONT_hpRefrigPressureSensorCh "VCFRONT_hpRefrigPressureSensorCheckCanFire";
BA_ "Confidence" SG_ 897 VCFRONT_tempSuperheatActFiltered 0;
BA_ "Confidence" SG_ 897 VCFRONT_tempRefrigDischarge 0;
BA_ "GenSigSNA" SG_ 897 VCFRONT_tempRefrigDischarge "2047";
BA_ "Confidence" SG_ 897 VCFRONT_pumpBatteryRPMTarget 0;
BA_ "GenSigSNA" SG_ 897 VCFRONT_pumpBatteryRPMTarget "255";
BA_ "Confidence" SG_ 897 VCFRONT_pumpPowertrainRPMTarget 0;
BA_ "GenSigSNA" SG_ 897 VCFRONT_pumpPowertrainRPMTarget "255";
BA_ "Confidence" SG_ 897 VCFRONT_coolantFlowChillerTarget 0;
BA_ "Confidence" SG_ 897 VCFRONT_radiatorFanRPMTarget 0;
BA_ "GenSigSNA" SG_ 897 VCFRONT_radiatorFanRPMTarget "255";
BA_ "Confidence" SG_ 897 VCFRONT_preventReEntryTillNexthp 0;
BA_ "SystemSignalLongSymbol" SG_ 897 VCFRONT_preventReEntryTillNexthp "VCFRONT_preventReEntryTillNexthpResetCOP1";
BA_ "Confidence" SG_ 897 VCFRONT_chillerBattHeatingPowerA 0;
BA_ "SystemSignalLongSymbol" SG_ 897 VCFRONT_chillerBattHeatingPowerA "VCFRONT_chillerBattHeatingPowerAvailable";
BA_ "Confidence" SG_ 897 VCFRONT_isExpectedQChillerVeryHi 0;
BA_ "SystemSignalLongSymbol" SG_ 897 VCFRONT_isExpectedQChillerVeryHi "VCFRONT_isExpectedQChillerVeryHighCOP1";
BA_ "Confidence" SG_ 897 VCFRONT_autopilotAirPurgeRoutine 0;
BA_ "SystemSignalLongSymbol" SG_ 897 VCFRONT_autopilotAirPurgeRoutine "VCFRONT_autopilotAirPurgeRoutineCounter";
BA_ "Confidence" SG_ 897 VCFRONT_superheatProtectionLimit 0;
BA_ "Confidence" SG_ 897 VCFRONT_chillerDemandWatts 0;
BA_ "Confidence" SG_ 897 VCFRONT_nominalTevapHWLimit 0;
BA_ "Confidence" SG_ 897 VCFRONT_battCoolEvapEnableDelay 0;
BA_ "Confidence" SG_ 897 VCFRONT_ambientTempState 0;
BA_ "Confidence" SG_ 897 VCFRONT_ambientTempUnlatchReason 0;
BA_ "Confidence" SG_ 897 VCFRONT_compressorSuctionVaporQu 0;
BA_ "SystemSignalLongSymbol" SG_ 897 VCFRONT_compressorSuctionVaporQu "VCFRONT_compressorSuctionVaporQuality";
BA_ "Confidence" SG_ 897 VCFRONT_cabinHeatingCOP1MinActiv 0;
BA_ "SystemSignalLongSymbol" SG_ 897 VCFRONT_cabinHeatingCOP1MinActiv "VCFRONT_cabinHeatingCOP1MinActiveRefCharge";
BA_ "Confidence" SG_ 897 VCFRONT_hpDuctTargetLeft 0;
BA_ "Confidence" SG_ 897 VCFRONT_hpDuctTargetRight 0;
BA_ "Confidence" SG_ 897 VCFRONT_radiatorUAIndex 0;
BA_ "Confidence" SG_ 897 VCFRONT_maxBatInletCoolantTempAl 0;
BA_ "SystemSignalLongSymbol" SG_ 897 VCFRONT_maxBatInletCoolantTempAl "VCFRONT_maxBatInletCoolantTempAllowed";
BA_ "Confidence" SG_ 897 VCFRONT_coolantTempInBypassDelta 0;
BA_ "Confidence" SG_ 897 VCFRONT_targetAPPActiveCool 0;
BA_ "Confidence" SG_ 513 VCFRONT_loggingAndVitals10HzInde 1;
BA_ "SystemSignalLongSymbol" SG_ 513 VCFRONT_loggingAndVitals10HzInde "VCFRONT_loggingAndVitals10HzIndex";
BA_ "Confidence" SG_ 513 VCFRONT_pumpBatteryRPMActual 0;
BA_ "GenSigSNA" SG_ 513 VCFRONT_pumpBatteryRPMActual "255";
BA_ "Confidence" SG_ 513 VCFRONT_pumpPowertrainRPMActual 0;
BA_ "GenSigSNA" SG_ 513 VCFRONT_pumpPowertrainRPMActual "255";
BA_ "Confidence" SG_ 513 VCFRONT_radiatorFanRPMActual 0;
BA_ "GenSigSNA" SG_ 513 VCFRONT_radiatorFanRPMActual "255";
BA_ "Confidence" SG_ 513 VCFRONT_exvFlowTarget 0;
BA_ "Confidence" SG_ 513 VCFRONT_activeLouverOpenPosTarg 0;
BA_ "Confidence" SG_ 513 VCFRONT_pressureRefrigLiquid 0;
BA_ "GenSigSNA" SG_ 513 VCFRONT_pressureRefrigLiquid "511";
BA_ "Confidence" SG_ 513 VCFRONT_compSleepRequest 0;
BA_ "Confidence" SG_ 513 VCFRONT_thermalHvPowerBudget 0;
BA_ "Confidence" SG_ 513 VCFRONT_compMinOnTimeActive 0;
BA_ "Confidence" SG_ 513 VCFRONT_compMinOffTimeActive 0;
BA_ "Confidence" SG_ 513 VCFRONT_fanDemand 0;
BA_ "Confidence" SG_ 513 VCFRONT_compressorState 0;
BA_ "Confidence" SG_ 513 VCFRONT_compDemandEvap 0;
BA_ "Confidence" SG_ 513 VCFRONT_exvState 0;
BA_ "Confidence" SG_ 513 VCFRONT_solenoidEvapState 0;
BA_ "Confidence" SG_ 513 VCFRONT_compDemandChiller 0;
BA_ "Confidence" SG_ 513 VCFRONT_coolantValveMode 0;
BA_ "Confidence" SG_ 513 VCFRONT_compFaultSeverity 0;
BA_ "Confidence" SG_ 513 VCFRONT_solenoidEngaged 0;
BA_ "Confidence" SG_ 513 VCFRONT_hpHighSideHX 0;
BA_ "Confidence" SG_ 513 VCFRONT_hpLowSideHX 0;
BA_ "Confidence" SG_ 513 VCFRONT_hpDominantLoad 0;
BA_ "Confidence" SG_ 513 VCFRONT_hpBlendType 0;
BA_ "Confidence" SG_ 513 VCFRONT_hpQuietModeEnabled 0;
BA_ "Confidence" SG_ 513 VCFRONT_hpCabinLoadType 0;
BA_ "Confidence" SG_ 513 VCFRONT_hpBatteryLoadType 0;
BA_ "Confidence" SG_ 513 VCFRONT_hpReqCoolantMode 0;
BA_ "Confidence" SG_ 513 VCFRONT_hpReqTransScavenge 0;
BA_ "Confidence" SG_ 513 VCFRONT_compLiqPumpOutState 0;
BA_ "Confidence" SG_ 513 VCFRONT_frunkStateDBG 0;
BA_ "Confidence" SG_ 513 VCFRONT_frunkSwitchGroupState 0;
BA_ "Confidence" SG_ 513 VCFRONT_chillerExvFlow 0;
BA_ "Confidence" SG_ 513 VCFRONT_evapExvFlow 0;
BA_ "Confidence" SG_ 513 VCFRONT_recircExvFlow 0;
BA_ "Confidence" SG_ 513 VCFRONT_lccExvFlow 0;
BA_ "Confidence" SG_ 513 VCFRONT_cclExvFlow 0;
BA_ "Confidence" SG_ 513 VCFRONT_ccrExvFlow 0;
BA_ "Confidence" SG_ 513 VCFRONT_chillerExvState 0;
BA_ "Confidence" SG_ 513 VCFRONT_evapExvState 0;
BA_ "Confidence" SG_ 513 VCFRONT_recircExvState 0;
BA_ "Confidence" SG_ 513 VCFRONT_chillerExvFlowTarget 0;
BA_ "Confidence" SG_ 513 VCFRONT_evapExvFlowTarget 0;
BA_ "Confidence" SG_ 513 VCFRONT_recircExvFlowTarget 0;
BA_ "Confidence" SG_ 513 VCFRONT_lccExvFlowTarget 0;
BA_ "Confidence" SG_ 513 VCFRONT_cclExvFlowTarget 0;
BA_ "Confidence" SG_ 513 VCFRONT_ccrExvFlowTarget 0;
BA_ "Confidence" SG_ 513 VCFRONT_lccExvState 0;
BA_ "Confidence" SG_ 513 VCFRONT_cclExvState 0;
BA_ "Confidence" SG_ 513 VCFRONT_ccrExvState 0;
BA_ "Confidence" SG_ 721 VCFRONT_vcleftOkToUseHighPower 0;
BA_ "Confidence" SG_ 721 VCFRONT_vcrightOkToUseHighPower 0;
BA_ "Confidence" SG_ 721 VCFRONT_das1OkToUseHighPower 0;
BA_ "Confidence" SG_ 721 VCFRONT_das2OkToUseHighPower 0;
BA_ "Confidence" SG_ 721 VCFRONT_MCULogicOkToUseHighPower 0;
BA_ "Confidence" SG_ 721 VCFRONT_MCUAudioOkToUseHighPower 0;
BA_ "Confidence" SG_ 721 VCFRONT_cpOkToUseHighPower 0;
BA_ "Confidence" SG_ 721 VCFRONT_premAudioOkToUseHiPower 0;
BA_ "Confidence" SG_ 721 VCFRONT_tasOkToUseHighPower 0;
BA_ "Confidence" SG_ 801 VCFRONT_tempCoolantBatInlet 0;
BA_ "GenSigSNA" SG_ 801 VCFRONT_tempCoolantBatInlet "1023";
BA_ "Confidence" SG_ 801 VCFRONT_tempCoolantPTInlet 0;
BA_ "GenSigSNA" SG_ 801 VCFRONT_tempCoolantPTInlet "2047";
BA_ "Confidence" SG_ 801 VCFRONT_coolantLevel 0;
BA_ "Confidence" SG_ 801 VCFRONT_brakeFluidLevel 0;
BA_ "GenSigSNA" SG_ 801 VCFRONT_brakeFluidLevel "0";
BA_ "Confidence" SG_ 801 VCFRONT_tempAmbient 0;
BA_ "GenSigSNA" SG_ 801 VCFRONT_tempAmbient "0";
BA_ "Confidence" SG_ 801 VCFRONT_washerFluidLevel 0;
BA_ "GenSigSNA" SG_ 801 VCFRONT_washerFluidLevel "0";
BA_ "Confidence" SG_ 801 VCFRONT_tempAmbientFiltered 0;
BA_ "GenSigSNA" SG_ 801 VCFRONT_tempAmbientFiltered "0";
BA_ "Confidence" SG_ 801 VCFRONT_battSensorIrrational 0;
BA_ "Confidence" SG_ 801 VCFRONT_ptSensorIrrational 0;
BA_ "Confidence" SG_ 801 VCFRONT_sensorsCounter 0;
BA_ "Confidence" SG_ 801 VCFRONT_sensorsChecksum 0;
BA_ "Confidence" SG_ 1349 VCFRONT_systemStatusMuxIndex 1;
BA_ "Confidence" SG_ 1349 VCFRONT_systemStatusCounter 0;
BA_ "Confidence" SG_ 1349 VCFRONT_systemStatusChecksum 0;
BA_ "Confidence" SG_ 1349 VCFRONT_loadShedReason 0;
BA_ "Confidence" SG_ 1349 VCFRONT_VCRightEFuseLoadShedStag 0;
BA_ "SystemSignalLongSymbol" SG_ 1349 VCFRONT_VCRightEFuseLoadShedStag "VCFRONT_VCRightEFuseLoadShedStage";
BA_ "Confidence" SG_ 1349 VCFRONT_VCLeftEFuseLoadShedStage 0;
BA_ "Confidence" SG_ 1349 VCFRONT_DCDCSaturationLoadShedSt 0;
BA_ "SystemSignalLongSymbol" SG_ 1349 VCFRONT_DCDCSaturationLoadShedSt "VCFRONT_DCDCSaturationLoadShedStage";
BA_ "Confidence" SG_ 1349 VCFRONT_vehicleLoadShedStage 0;
BA_ "Confidence" SG_ 1349 VCFRONT_HVFaultVehicleLoadShedRe 0;
BA_ "SystemSignalLongSymbol" SG_ 1349 VCFRONT_HVFaultVehicleLoadShedRe "VCFRONT_HVFaultVehicleLoadShedRequest";
BA_ "Confidence" SG_ 1349 VCFRONT_postCrashVehicleLoadShed 0;
BA_ "SystemSignalLongSymbol" SG_ 1349 VCFRONT_postCrashVehicleLoadShed "VCFRONT_postCrashVehicleLoadShedActive";
BA_ "Confidence" SG_ 1349 VCFRONT_HVFaultVehicleLoadShedAc 0;
BA_ "SystemSignalLongSymbol" SG_ 1349 VCFRONT_HVFaultVehicleLoadShedAc "VCFRONT_HVFaultVehicleLoadShedActive";
BA_ "Confidence" SG_ 1349 VCFRONT_factoryVehicleLoadShedAc 0;
BA_ "SystemSignalLongSymbol" SG_ 1349 VCFRONT_factoryVehicleLoadShedAc "VCFRONT_factoryVehicleLoadShedActive";
BA_ "Confidence" SG_ 1349 VCFRONT_anyVehicleLoadShedActive 0;
BA_ "Confidence" SG_ 1349 VCFRONT_DIVehLoadShedActive 0;
BA_ "Confidence" SG_ 1349 VCFRONT_HVFaultLoadShedStateDBG 0;
BA_ "Confidence" SG_ 1349 VCFRONT_LVUnhealthyVehicleLoadSh 0;
BA_ "SystemSignalLongSymbol" SG_ 1349 VCFRONT_LVUnhealthyVehicleLoadSh "VCFRONT_LVUnhealthyVehicleLoadShedActive";
BA_ "Confidence" SG_ 1349 VCFRONT_loadShedStsCondenserFan 0;
BA_ "Confidence" SG_ 1349 VCFRONT_loadShedStsPTPump 0;
BA_ "Confidence" SG_ 1349 VCFRONT_loadShedMCUAudio 0;
BA_ "Confidence" SG_ 1349 VCFRONT_loadShedHVDownTriggerDBG 0;
BA_ "Confidence" SG_ 1349 VCFRONT_loadShedPCSSatTriggerDBG 0;
BA_ "Confidence" SG_ 1349 VCFRONT_loadShedStsBatteryPump 0;
BA_ "Confidence" SG_ 1349 VCFRONT_loadShedStsAPGlassHeater 0;
BA_ "Confidence" SG_ 1349 VCFRONT_loadShedStsMCUGraphics 0;
BA_ "Confidence" SG_ 1349 VCFRONT_IBSCurrentRMS_loadShed 0;
BA_ "Confidence" SG_ 1349 VCFRONT_loadShedAhLeakyBktCntDBG 0;
BA_ "Confidence" SG_ 1349 VCFRONT_loadShedPcs 0;
BA_ "Confidence" SG_ 1349 VCFRONT_loadShedGTWDownstrmRails 0;
BA_ "Confidence" SG_ 1349 VCFRONT_loadShedPCSMIATriggerDBG 0;
BA_ "Confidence" SG_ 1349 VCFRONT_loadShedTAS 0;
BA_ "Confidence" SG_ 1349 VCFRONT_loadShedBackStopBktCntDB 0;
BA_ "SystemSignalLongSymbol" SG_ 1349 VCFRONT_loadShedBackStopBktCntDB "VCFRONT_loadShedBackStopBktCntDBG";
BA_ "Confidence" SG_ 1349 VCFRONT_loadShedPCSLeakyBktCtDBG 0;
BA_ "Confidence" SG_ 1349 VCFRONT_loadShedUI 0;
BA_ "Confidence" SG_ 1349 VCFRONT_loadShedAutoPilot 0;
BA_ "Confidence" SG_ 929 VCFRONT_vehicleStatusMuxIndex 1;
BA_ "Confidence" SG_ 929 VCFRONT_vehicleStatusCounter 0;
BA_ "Confidence" SG_ 929 VCFRONT_vehicleStatusChecksum 0;
BA_ "Confidence" SG_ 929 VCFRONT_preconditionRequest 0;
BA_ "Confidence" SG_ 929 VCFRONT_APGlassHeaterState 0;
BA_ "GenSigSNA" SG_ 929 VCFRONT_APGlassHeaterState "0";
BA_ "Confidence" SG_ 929 VCFRONT_thermalSystemType 0;
BA_ "GenSigSNA" SG_ 929 VCFRONT_thermalSystemType "1";
BA_ "Confidence" SG_ 929 VCFRONT_standbySupplySupported 0;
BA_ "Confidence" SG_ 929 VCFRONT_driverPresent 0;
BA_ "Confidence" SG_ 929 VCFRONT_passengerPresent 0;
BA_ "Confidence" SG_ 929 VCFRONT_accPlusAvailable 0;
BA_ "Confidence" SG_ 929 VCFRONT_diPowerOnState 0;
BA_ "Confidence" SG_ 929 VCFRONT_12vStatusForDrive 0;
BA_ "Confidence" SG_ 929 VCFRONT_dcr12VMilliOhms 0;
BA_ "Confidence" SG_ 929 VC_userPresenceState 0;
BA_ "Confidence" SG_ 929 VCFRONT_factoryLimitsOverrideOk 0;
BA_ "Confidence" SG_ 929 VCFRONT_ota12VSupportRequest 0;
BA_ "Confidence" SG_ 929 VCFRONT_driverBuckleStatus 0;
BA_ "Confidence" SG_ 929 VCFRONT_driverDoorStatus 0;
BA_ "Confidence" SG_ 929 VCFRONT_driverUnbuckled 0;
BA_ "GenSigSNA" SG_ 929 VCFRONT_driverUnbuckled "2";
BA_ "Confidence" SG_ 929 VCFRONT_passengerUnbuckled 0;
BA_ "GenSigSNA" SG_ 929 VCFRONT_passengerUnbuckled "2";
BA_ "Confidence" SG_ 929 VCFRONT_2RowLeftUnbuckled 0;
BA_ "GenSigSNA" SG_ 929 VCFRONT_2RowLeftUnbuckled "2";
BA_ "Confidence" SG_ 929 VCFRONT_2RowCenterUnbuckled 0;
BA_ "GenSigSNA" SG_ 929 VCFRONT_2RowCenterUnbuckled "2";
BA_ "Confidence" SG_ 929 VCFRONT_2RowRightUnbuckled 0;
BA_ "GenSigSNA" SG_ 929 VCFRONT_2RowRightUnbuckled "2";
BA_ "Confidence" SG_ 929 VCFRONT_pcsEFuseVoltage 0;
BA_ "GenSigSNA" SG_ 929 VCFRONT_pcsEFuseVoltage "1023";
BA_ "Confidence" SG_ 929 VCFRONT_bmsHvChargeEnable 0;
BA_ "Confidence" SG_ 929 VCFRONT_3RowLeftUnbuckled 0;
BA_ "GenSigSNA" SG_ 929 VCFRONT_3RowLeftUnbuckled "2";
BA_ "Confidence" SG_ 929 VCFRONT_3RowRightUnbuckled 0;
BA_ "GenSigSNA" SG_ 929 VCFRONT_3RowRightUnbuckled "2";
BA_ "Confidence" SG_ 929 VCFRONT_maxBattHeatRejection 0;
BA_ "Confidence" SG_ 929 VCFRONT_hvacReqBattCoolOutTemp 0;
BA_ "Confidence" SG_ 929 VCFRONT_PCSCurrent 0;
BA_ "Confidence" SG_ 929 VCFRONT_refSystemNominal 0;
BA_ "Confidence" SG_ 929 VCFRONT_driverEnteredCabinEstima 0;
BA_ "SystemSignalLongSymbol" SG_ 929 VCFRONT_driverEnteredCabinEstima "VCFRONT_driverEnteredCabinEstimateDBG";
BA_ "Confidence" SG_ 929 VCFRONT_anySWEFuseActive 0;
BA_ "Confidence" SG_ 929 VCFRONT_hpBattHeatingPowerTrgt 0;
BA_ "Confidence" SG_ 507 VCLEFT_TLCStatusIndex 1;
BA_ "Confidence" SG_ 507 VCLEFT_TLCTemperature 0;
BA_ "GenSigSNA" SG_ 507 VCLEFT_TLCTemperature "128";
BA_ "Confidence" SG_ 507 VCLEFT_TLCLeftTurnVoltage 0;
BA_ "GenSigSNA" SG_ 507 VCLEFT_TLCLeftTurnVoltage "255";
BA_ "Confidence" SG_ 507 VCLEFT_TLCRightTurnVoltage 0;
BA_ "GenSigSNA" SG_ 507 VCLEFT_TLCRightTurnVoltage "255";
BA_ "Confidence" SG_ 507 VCLEFT_TLCState_LeftTurn 0;
BA_ "GenSigSNA" SG_ 507 VCLEFT_TLCState_LeftTurn "5";
BA_ "Confidence" SG_ 507 VCLEFT_TLCState_RightTurn 0;
BA_ "GenSigSNA" SG_ 507 VCLEFT_TLCState_RightTurn "5";
BA_ "Confidence" SG_ 507 VCLEFT_TLCState_Tail 0;
BA_ "GenSigSNA" SG_ 507 VCLEFT_TLCState_Tail "5";
BA_ "Confidence" SG_ 507 VCLEFT_TLCState_Stop 0;
BA_ "GenSigSNA" SG_ 507 VCLEFT_TLCState_Stop "5";
BA_ "Confidence" SG_ 507 VCLEFT_TLCState_Fog 0;
BA_ "GenSigSNA" SG_ 507 VCLEFT_TLCState_Fog "5";
BA_ "Confidence" SG_ 507 VCLEFT_TLCState_Reverse 0;
BA_ "GenSigSNA" SG_ 507 VCLEFT_TLCState_Reverse "5";
BA_ "Confidence" SG_ 290 VCLEFT_doorStatus2Index 1;
BA_ "Confidence" SG_ 290 VCLEFT_frontLatchRelDuty 0;
BA_ "Confidence" SG_ 290 VCLEFT_BPillarCameraHeaterState 0;
BA_ "GenSigSNA" SG_ 290 VCLEFT_BPillarCameraHeaterState "0";
BA_ "Confidence" SG_ 290 VCLEFT_doorLatchAjarSwitchVoltag 0;
BA_ "SystemSignalLongSymbol" SG_ 290 VCLEFT_doorLatchAjarSwitchVoltag "VCLEFT_doorLatchAjarSwitchVoltageF";
BA_ "Confidence" SG_ 290 VCLEFT_doorLatchAjarSwitchV_0001 0;
BA_ "SystemSignalLongSymbol" SG_ 290 VCLEFT_doorLatchAjarSwitchV_0001 "VCLEFT_doorLatchAjarSwitchVoltageR";
BA_ "Confidence" SG_ 290 VCLEFT_BPillarCameraHeaterCurren 0;
BA_ "GenSigSNA" SG_ 290 VCLEFT_BPillarCameraHeaterCurren "63";
BA_ "SystemSignalLongSymbol" SG_ 290 VCLEFT_BPillarCameraHeaterCurren "VCLEFT_BPillarCameraHeaterCurrent";
BA_ "Confidence" SG_ 290 VCLEFT_mirrorTiltXOffset 0;
BA_ "Confidence" SG_ 290 VCLEFT_mirrorTiltYOffset 0;
BA_ "Confidence" SG_ 626 VCLEFT_epbmDebugIndex 1;
BA_ "Confidence" SG_ 626 VCLEFT_epbmCaliperState 0;
BA_ "Confidence" SG_ 626 VCLEFT_epbmMotorEnabled 0;
BA_ "Confidence" SG_ 626 VCLEFT_epbMotorCurrent 0;
BA_ "Confidence" SG_ 626 VCLEFT_epbmApplyVoltage 0;
BA_ "Confidence" SG_ 626 VCLEFT_epbmReleaseVoltage 0;
BA_ "Confidence" SG_ 626 VCLEFT_summonFaultReason 0;
BA_ "Confidence" SG_ 626 VCLEFT_epbSummonState 0;
BA_ "Confidence" SG_ 626 VCLEFT_epbmSummonState 0;
BA_ "Confidence" SG_ 626 VCLEFT_epbUnitStatus 0;
BA_ "Confidence" SG_ 626 VCLEFT_epbmFaultStatus 0;
BA_ "Confidence" SG_ 626 VCLEFT_epbFaultStatus 0;
BA_ "Confidence" SG_ 626 VCLEFT_epbmSystemStatus 0;
BA_ "Confidence" SG_ 626 VCLEFT_epbmAutonomyBehavior 0;
BA_ "Confidence" SG_ 1186 VCLEFT_etcBluetoothStatus 0;
BA_ "Confidence" SG_ 642 VCLEFT_hvacBlowerFeedbackIndex 1;
BA_ "Confidence" SG_ 642 VCLEFT_hvacBlowerEnabled 0;
BA_ "Confidence" SG_ 642 VCLEFT_hvacBlowerOutputDuty 0;
BA_ "GenSigSNA" SG_ 642 VCLEFT_hvacBlowerOutputDuty "127";
BA_ "Confidence" SG_ 642 VCLEFT_hvacBlowerRPMTarget 0;
BA_ "GenSigSNA" SG_ 642 VCLEFT_hvacBlowerRPMTarget "1023";
BA_ "Confidence" SG_ 642 VCLEFT_hvacBlowerRPMActual 0;
BA_ "Confidence" SG_ 642 VCLEFT_hvacBlowerTorque 0;
BA_ "GenSigSNA" SG_ 642 VCLEFT_hvacBlowerTorque "1023";
BA_ "Confidence" SG_ 642 VCLEFT_hvacBlowerFETTemp 0;
BA_ "GenSigSNA" SG_ 642 VCLEFT_hvacBlowerFETTemp "127";
BA_ "Confidence" SG_ 642 VCLEFT_hvacBlowerIDc 0;
BA_ "GenSigSNA" SG_ 642 VCLEFT_hvacBlowerIDc "127";
BA_ "Confidence" SG_ 642 VCLEFT_hvacBlowerInitd 0;
BA_ "Confidence" SG_ 642 VCLEFT_hvacBlowerFault 0;
BA_ "Confidence" SG_ 642 VCLEFT_hvacBlowerLimitFETTemps 0;
BA_ "Confidence" SG_ 642 VCLEFT_hvacBlowerPowerOn 0;
BA_ "Confidence" SG_ 642 VCLEFT_hvacBlowerMotorID 0;
BA_ "Confidence" SG_ 770 VCLEFT_infoIndex 1;
BA_ "Confidence" SG_ 770 VCLEFT_infoBuildType 0;
BA_ "Confidence" SG_ 770 VCLEFT_infoBuildConfigId 0;
BA_ "Confidence" SG_ 770 VCLEFT_infoHardwareId 0;
BA_ "Confidence" SG_ 770 VCLEFT_infoComponentId 0;
BA_ "Confidence" SG_ 770 VCLEFT_infoPcbaId 0;
BA_ "Confidence" SG_ 770 VCLEFT_infoAssemblyId 0;
BA_ "GenSigSNA" SG_ 770 VCLEFT_infoAssemblyId "255";
BA_ "Confidence" SG_ 770 VCLEFT_infoUsageId 0;
BA_ "Confidence" SG_ 770 VCLEFT_infoSubUsageId 0;
BA_ "Confidence" SG_ 770 VCLEFT_infoAppCrc 0;
BA_ "Confidence" SG_ 770 VCLEFT_infoLUMBARLAppCRC 0;
BA_ "Confidence" SG_ 770 VCLEFT_infoAppGitHash 0;
BA_ "Confidence" SG_ 770 VCLEFT_infoBootGitHash 0;
BA_ "Confidence" SG_ 770 VCLEFT_infoPlatformType 0;
BA_ "Confidence" SG_ 770 VCLEFT_infoBootUdsProtoVersion 0;
BA_ "Confidence" SG_ 770 VCLEFT_infoBootCrc 0;
BA_ "Confidence" SG_ 292 VCLEFT_liftgateRequestAction 0;
BA_ "Confidence" SG_ 292 VCLEFT_liftgateRequestTargetDuty 0;
BA_ "Confidence" SG_ 292 VCLEFT_liftgateRequestTargetAngl 0;
BA_ "SystemSignalLongSymbol" SG_ 292 VCLEFT_liftgateRequestTargetAngl "VCLEFT_liftgateRequestTargetAngle";
BA_ "Confidence" SG_ 292 VCLEFT_liftgateRequestTargetPara 0;
BA_ "SystemSignalLongSymbol" SG_ 292 VCLEFT_liftgateRequestTargetPara "VCLEFT_liftgateRequestTargetParam";
BA_ "Confidence" SG_ 292 VCLEFT_adaptiveLiftgateControlMo 0;
BA_ "SystemSignalLongSymbol" SG_ 292 VCLEFT_adaptiveLiftgateControlMo "VCLEFT_adaptiveLiftgateControlModeActive";
BA_ "Confidence" SG_ 292 VCLEFT_liftgateReqObsDetMode 0;
BA_ "Confidence" SG_ 292 VCLEFT_liftgateReqResetStrutCoun 0;
BA_ "SystemSignalLongSymbol" SG_ 292 VCLEFT_liftgateReqResetStrutCoun "VCLEFT_liftgateReqResetStrutCount";
BA_ "Confidence" SG_ 292 VCLEFT_liftgateReqClearCal 0;
BA_ "Confidence" SG_ 292 VCLEFT_liftgateTargetTerminalSpe 0;
BA_ "SystemSignalLongSymbol" SG_ 292 VCLEFT_liftgateTargetTerminalSpe "VCLEFT_liftgateTargetTerminalSpeed";
BA_ "Confidence" SG_ 292 VCLEFT_liftgateReqCoastPercent 0;
BA_ "Confidence" SG_ 292 VCLEFT_liftgateReqDutyScale 0;
BA_ "Confidence" SG_ 322 VCLEFT_liftgateStatusIndex 1;
BA_ "Confidence" SG_ 322 VCLEFT_liftgateState 0;
BA_ "Confidence" SG_ 322 VCLEFT_liftgateStoppingCondition 0;
BA_ "Confidence" SG_ 322 VCLEFT_liftgateMvmntNotAllowedCo 0;
BA_ "SystemSignalLongSymbol" SG_ 322 VCLEFT_liftgateMvmntNotAllowedCo "VCLEFT_liftgateMvmntNotAllowedCondition";
BA_ "Confidence" SG_ 322 VCLEFT_liftgatePositionCalibrate 0;
BA_ "SystemSignalLongSymbol" SG_ 322 VCLEFT_liftgatePositionCalibrate "VCLEFT_liftgatePositionCalibrated";
BA_ "Confidence" SG_ 322 VCLEFT_liftgateUIChimeRequest 0;
BA_ "Confidence" SG_ 322 VCLEFT_liftgatePhysicalChimeRequ 0;
BA_ "SystemSignalLongSymbol" SG_ 322 VCLEFT_liftgatePhysicalChimeRequ "VCLEFT_liftgatePhysicalChimeRequest";
BA_ "Confidence" SG_ 322 VCLEFT_liftgateEstimatedStrutTem 0;
BA_ "SystemSignalLongSymbol" SG_ 322 VCLEFT_liftgateEstimatedStrutTem "VCLEFT_liftgateEstimatedStrutTemp";
BA_ "Confidence" SG_ 322 VCLEFT_liftgateStaticStrutMode 0;
BA_ "GenSigSNA" SG_ 322 VCLEFT_liftgateStaticStrutMode "0";
BA_ "Confidence" SG_ 322 VCLEFT_liftgateRequestSource 0;
BA_ "Confidence" SG_ 322 VCLEFT_liftgateNewHeightNudge 0;
BA_ "Confidence" SG_ 322 VCLEFT_liftgateNewSaveHeight 0;
BA_ "Confidence" SG_ 322 VCLEFT_liftgateGeofenceState 0;
BA_ "Confidence" SG_ 322 VCLEFT_liftgateCloseWarnChimeReq 0;
BA_ "SystemSignalLongSymbol" SG_ 322 VCLEFT_liftgateCloseWarnChimeReq "VCLEFT_liftgateCloseWarnChimeRequest";
BA_ "Confidence" SG_ 322 VCLEFT_liftgateAboveCrossoverAng 0;
BA_ "SystemSignalLongSymbol" SG_ 322 VCLEFT_liftgateAboveCrossoverAng "VCLEFT_liftgateAboveCrossoverAngle";
BA_ "Confidence" SG_ 322 VCLEFT_liftgateLatchRequest 0;
BA_ "Confidence" SG_ 322 VCLEFT_liftgateStrutDutyCycle 0;
BA_ "Confidence" SG_ 322 VCLEFT_liftgateStrutCurrent 0;
BA_ "Confidence" SG_ 322 VCLEFT_liftgatePosition 0;
BA_ "Confidence" SG_ 322 VCLEFT_liftgateSpeed 0;
BA_ "Confidence" SG_ 322 VCLEFT_liftgateHeight 0;
BA_ "Confidence" SG_ 322 VCLEFT_liftgatePositionDiff 0;
VAL_ 769 VCFRONT_infoIndex 255 "END" 41 "SUBCOMPONENT14" 40 "SUBCOMPONENT13" 39 "SUBCOMPONENT12" 38 "SUBCOMPONENT11" 37 "SUBCOMPONENT10" 36 "SUBCOMPONENT9" 35 "SUBCOMPONENT8" 34 "SUBCOMPONENT7" 33 "SUBCOMPONENT6" 32 "SUBCOMPONENT5" 31 "SUBCOMPONENT4" 24 "SUBCOMPONENT3" 23 "SUBCOMPONENT2" 20 "UDS_PROTOCOL_BOOTCRC" 19 "VERSION_DEPRECATED" 18 "BOOTLOADER_GITHASH" 17 "APP_GITHASH" 16 "SUBCOMPONENT1" 15 "BOOTLOADER_CRC" 14 "BOOTLOADER_SVN" 13 "APP_CRC" 11 "PCBAID_ASSYID_USAGEID" 10 "BUILD_HWID_COMPONENTID" 9 "DEPRECATED_9" 8 "DEPRECATED_8" 7 "DEPRECATED_7" 6 "DEPRECATED_6" 5 "DEPRECATED_5" 4 "DEPRECATED_4" 3 "DEPRECATED_3" 2 "DEPRECATED_2" 1 "DEPRECATED_1" 0 "DEPRECATED_0" ;
VAL_ 769 VCFRONT_infoBuildType 4 "INFO_MFG_BUILD" 3 "INFO_TRACEABLE_CI_BUILD" 2 "INFO_LOCAL_BUILD" 1 "INFO_PLATFORM_BUILD" 0 "INFO_UNKNOWN_BUILD" ;
VAL_ 769 VCFRONT_infoAssemblyId 255 "ASSEMBLY_SNA" 1 "ASSEMBLY1" ;
VAL_ 1014 VCFRONT_lowBeamLeftStatus 3 "LIGHT_SNA" 2 "LIGHT_FAULT" 1 "LIGHT_ON" 0 "LIGHT_OFF" ;
VAL_ 1014 VCFRONT_lowBeamRightStatus 3 "LIGHT_SNA" 2 "LIGHT_FAULT" 1 "LIGHT_ON" 0 "LIGHT_OFF" ;
VAL_ 1014 VCFRONT_highBeamLeftStatus 3 "LIGHT_SNA" 2 "LIGHT_FAULT" 1 "LIGHT_ON" 0 "LIGHT_OFF" ;
VAL_ 1014 VCFRONT_highBeamRightStatus 3 "LIGHT_SNA" 2 "LIGHT_FAULT" 1 "LIGHT_ON" 0 "LIGHT_OFF" ;
VAL_ 1014 VCFRONT_DRLLeftStatus 3 "LIGHT_SNA" 2 "LIGHT_FAULT" 1 "LIGHT_ON" 0 "LIGHT_OFF" ;
VAL_ 1014 VCFRONT_DRLRightStatus 3 "LIGHT_SNA" 2 "LIGHT_FAULT" 1 "LIGHT_ON" 0 "LIGHT_OFF" ;
VAL_ 1014 VCFRONT_fogLeftStatus 3 "LIGHT_SNA" 2 "LIGHT_FAULT" 1 "LIGHT_ON" 0 "LIGHT_OFF" ;
VAL_ 1014 VCFRONT_fogRightStatus 3 "LIGHT_SNA" 2 "LIGHT_FAULT" 1 "LIGHT_ON" 0 "LIGHT_OFF" ;
VAL_ 1014 VCFRONT_sideMarkersStatus 3 "LIGHT_SNA" 2 "LIGHT_FAULT" 1 "LIGHT_ON" 0 "LIGHT_OFF" ;
VAL_ 1014 VCFRONT_sideRepeaterLeftStatus 3 "LIGHT_SNA" 2 "LIGHT_FAULT" 1 "LIGHT_ON" 0 "LIGHT_OFF" ;
VAL_ 1014 VCFRONT_sideRepeaterRightStatus 3 "LIGHT_SNA" 2 "LIGHT_FAULT" 1 "LIGHT_ON" 0 "LIGHT_OFF" ;
VAL_ 1014 VCFRONT_turnSignalLeftStatus 3 "LIGHT_SNA" 2 "LIGHT_FAULT" 1 "LIGHT_ON" 0 "LIGHT_OFF" ;
VAL_ 1014 VCFRONT_turnSignalRightStatus 3 "LIGHT_SNA" 2 "LIGHT_FAULT" 1 "LIGHT_ON" 0 "LIGHT_OFF" ;
VAL_ 1014 VCFRONT_parkLeftStatus 3 "LIGHT_SNA" 2 "LIGHT_FAULT" 1 "LIGHT_ON" 0 "LIGHT_OFF" ;
VAL_ 1014 VCFRONT_parkRightStatus 3 "LIGHT_SNA" 2 "LIGHT_FAULT" 1 "LIGHT_ON" 0 "LIGHT_OFF" ;
VAL_ 1014 VC_rightHeadlampHealth 7 "SMART_LIGHT_HEALTH_RESERVED" 6 "SMART_LIGHT_HEALTH_UPDATING" 5 "SMART_LIGHT_HEALTH_NOT_CONFIGURED" 4 "SMART_LIGHT_HEALTH_COMMS_OK_NO_LIGHT" 3 "SMART_LIGHT_HEALTH_OK" 2 "SMART_LIGHT_HEALTH_TIMEOUT" 1 "SMART_LIGHT_HEALTH_WAIT" 0 "SMART_LIGHT_HEALTH_OFF" ;
VAL_ 1014 VC_leftHeadlampHealth 7 "SMART_LIGHT_HEALTH_RESERVED" 6 "SMART_LIGHT_HEALTH_UPDATING" 5 "SMART_LIGHT_HEALTH_NOT_CONFIGURED" 4 "SMART_LIGHT_HEALTH_COMMS_OK_NO_LIGHT" 3 "SMART_LIGHT_HEALTH_OK" 2 "SMART_LIGHT_HEALTH_TIMEOUT" 1 "SMART_LIGHT_HEALTH_WAIT" 0 "SMART_LIGHT_HEALTH_OFF" ;
VAL_ 1014 VCFRONT_lightStatusMuxIndex 1 "ADVANCED_LIGHTING" 0 "HCM1_MIGRATION" ;
VAL_ 1014 VCFRONT_advancedDrivingBeamStatu 3 "ACTIVE_NO_COLUMNS_EXTINGUISHED" 2 "ACTIVE_SOME_COLUMNS_EXTINGUISHED" 1 "ENABLED_AND_INACTIVE" 0 "NOT_SUPPORTED_OR_DISABLED" ;
VAL_ 1014 VCFRONT_headlampRoadClass 3 "WET" 2 "MOTORWAY" 1 "TOWNLIGHT" 0 "NOMINAL" ;
VAL_ 1013 VCFRONT_indicatorLeftRequest 2 "TURN_SIGNAL_ACTIVE_HIGH" 1 "TURN_SIGNAL_ACTIVE_LOW" 0 "TURN_SIGNAL_OFF" ;
VAL_ 1013 VCFRONT_indicatorRightRequest 2 "TURN_SIGNAL_ACTIVE_HIGH" 1 "TURN_SIGNAL_ACTIVE_LOW" 0 "TURN_SIGNAL_OFF" ;
VAL_ 1013 VCFRONT_hazardLightRequest 8 "HAZARD_REQUEST_UDS" 7 "HAZARD_REQUEST_DAS" 6 "HAZARD_REQUEST_CAR_ALARM" 5 "HAZARD_REQUEST_CRASH" 4 "HAZARD_REQUEST_MISLOCK" 3 "HAZARD_REQUEST_UNLOCK" 2 "HAZARD_REQUEST_LOCK" 1 "HAZARD_REQUEST_BUTTON" 0 "HAZARD_REQUEST_NONE" ;
VAL_ 1013 VCFRONT_ambientLightingBrightnes 255 "SNA" ;
VAL_ 1013 VCFRONT_switchLightingBrightness 255 "SNA" ;
VAL_ 1013 VCFRONT_highBeamControlState 3 "HIGH_BEAM_CONTROL_DAS_AUTO" 2 "HIGH_BEAM_CONTROL_LATCHED" 1 "HIGH_BEAM_CONTROL_INTERMITTENT" 0 "HIGH_BEAM_CONTROL_IDLE" ;
VAL_ 1013 VCFRONT_dynamicBrakeLightState 2 "DYNAMIC_BRAKE_LIGHT_ACTIVE_HIGH" 1 "DYNAMIC_BRAKE_LIGHT_ACTIVE_LOW" 0 "DYNAMIC_BRAKE_LIGHT_OFF" ;
VAL_ 1013 VCFRONT_lightingCoreState 15 "LIGHT_CORE_STATE_SNA" 5 "LIGHT_CORE_STATE_CUSTOM" 4 "LIGHT_CORE_STATE_LOW_BEAMS" 3 "LIGHT_CORE_STATE_DRL_PLUS_REAR_POS_PARK" 2 "LIGHT_CORE_STATE_DRL" 1 "LIGHT_CORE_STATE_POS_PARK" 0 "LIGHT_CORE_STATE_OFF" ;
VAL_ 1013 VCFRONT_turnIndicatorStalk 3 "SIMULATED_LATCHING_STALK_SNA" 2 "SIMULATED_LATCHING_STALK_RIGHT" 1 "SIMULATED_LATCHING_STALK_LEFT" 0 "SIMULATED_LATCHING_STALK_IDLE" ;
VAL_ 1013 VCFRONT_highBeamLatchingState 3 "LATCHING_STATE_LATCHED" 2 "LATCHING_STATE_LATCHING" 1 "LATCHING_STATE_UNLATCHED" 0 "LATCHING_STATE_SNA" ;
VAL_ 1013 VCFRONT_lightingCustomState 31 "CUSTOM_LIGHTING_STATE_RESERVED" 14 "CUSTOM_LIGHTING_STATE_ROBOTAXI_WELCOME_RAMP_DOWN" 13 "CUSTOM_LIGHTING_STATE_ROBOTAXI_WELCOME_RAMP_UP" 12 "CUSTOM_LIGHTING_STATE_WELCOME_GOODBYE_SYHL" 11 "CUSTOM_LIGHTING_STATE_WELCOME_GOODBYE_NIGHT" 10 "CUSTOM_LIGHTING_STATE_WELCOME_GOODBYE_DAY" 9 "CUSTOM_LIGHTING_STATE_WELCOME_GOODBYE_UNLOCK" 8 "CUSTOM_LIGHTING_STATE_WELCOME_GOODBYE_LOCK" 7 "CUSTOM_LIGHTING_STATE_SELFTEST" 6 "CUSTOM_LIGHTING_STATE_HAZARD_WARNING_LIGHTS_OFF" 5 "CUSTOM_LIGHTING_STATE_HAZARD_WARNING_LIGHTS_ON" 4 "CUSTOM_LIGHTING_STATE_HAZARD_WARNING_WAIT_FOR_HEADLAMP_POWER" 3 "CUSTOM_LIGHTING_STATE_SENTRY_AWARE_OFF" 2 "CUSTOM_LIGHTING_STATE_SENTRY_AWARE_RAMP_DOWN" 1 "CUSTOM_LIGHTING_STATE_SENTRY_AWARE_RAMP_UP" 0 "CUSTOM_LIGHTING_STATE_NONE" ;
VAL_ 1013 VCFRONT_indicatorLeftInternal 2 "TURN_SIGNAL_ACTIVE_HIGH" 1 "TURN_SIGNAL_ACTIVE_LOW" 0 "TURN_SIGNAL_OFF" ;
VAL_ 1013 VCFRONT_indicatorRightInternal 2 "TURN_SIGNAL_ACTIVE_HIGH" 1 "TURN_SIGNAL_ACTIVE_LOW" 0 "TURN_SIGNAL_OFF" ;
VAL_ 1801 VCFRONT_logging0point1HzIndex 35 "END" 34 "DYNAMIC_LEVELING_CONTRIBUTORS" 33 "HEADLAMP_OFFSETS_AND_STATUS" 32 "HEADLAMP_LEFT_ECULESS_IO_DIAGNOSTIC_2" 31 "HEADLAMP_RIGHT_ECULESS_IO_DIAGNOSTIC_2" 30 "HEADLAMP_LEFT_ECULESS_IO_DIAGNOSTIC" 29 "HEADLAMP_RIGHT_ECULESS_IO_DIAGNOSTIC" 28 "COMPRESSOR_WEAR_COUNTERS" 27 "HEADLAMP_RIGHT_EEPROM_INFO" 26 "HEADLAMP_LEFT_EEPROM_INFO" 25 "EXV_VALVE_TYPES" 24 "PART_FAILURE_CONFIDENCE_CONTINUED" 23 "PART_FAILURE_CONFIDENCE" 22 "LIGHT_DEBUG" 21 "HEADLAMP_COMM_FAULT_COUNTERS" 20 "HEADLAMP_MIGRATION" 19 "EXV_TOTAL_DISTANCE_COUNTERS_3" 18 "EXV_TOTAL_DISTANCE_COUNTERS_2" 17 "EXV_TOTAL_DISTANCE_COUNTERS_1" 16 "EXV_CCR_COUNTERS_2" 15 "EXV_CCR_COUNTERS_1" 14 "EXV_CCL_COUNTERS_2" 13 "EXV_CCL_COUNTERS_1" 12 "EXV_LCC_COUNTERS_2" 11 "EXV_LCC_COUNTERS_1" 10 "EXV_RECIRC_COUNTERS_2" 9 "EXV_RECIRC_COUNTERS_1" 8 "EXV_EVAPORATOR_COUNTERS_2" 7 "EXV_EVAPORATOR_COUNTERS_1" 6 "EXV_CHILLER_COUNTERS_2" 5 "EXV_CHILLER_COUNTERS_1" 4 "HEADLAMP_AIMED_POSITION" 3 "HEADLAMP_CURRENT_POSITION" 2 "HCMR_LED_TEMPS" 1 "HCML_LED_TEMPS" 0 "LIGHT_CURRENTS" ;
VAL_ 1801 VC_hcmlFactoryOfOrigin 3 "HELLA_MEXICO" 2 "HELLA_SLOVAKIA" 1 "HELLA_CHINA" 0 "UNKNOWN" ;
VAL_ 1801 VC_hcmlHellaPartNumberStatus 1 "FAULT" 0 "OK" ;
VAL_ 1801 VC_hcmlCurrentBinMappingType 2 "BIN_MAP_TYPE_2" 1 "BIN_MAP_TYPE_1" 0 "BIN_MAP_TYPE_UNKNOWN" ;
VAL_ 1801 VC_hcmlCurrentBin0Value 7 "INVALID_LIGHTCLASS" 4 "LIGHTCLASS_4" 3 "LIGHTCLASS_3" 2 "LIGHTCLASS_2" 1 "LIGHTCLASS_1" 0 "LIGHTCLASS_SNA" ;
VAL_ 1801 VC_hcmlCurrentBin1Value 7 "INVALID_LIGHTCLASS" 4 "LIGHTCLASS_4" 3 "LIGHTCLASS_3" 2 "LIGHTCLASS_2" 1 "LIGHTCLASS_1" 0 "LIGHTCLASS_SNA" ;
VAL_ 1801 VC_hcmlCurrentBin2Value 7 "INVALID_LIGHTCLASS" 4 "LIGHTCLASS_4" 3 "LIGHTCLASS_3" 2 "LIGHTCLASS_2" 1 "LIGHTCLASS_1" 0 "LIGHTCLASS_SNA" ;
VAL_ 1801 VC_hcmlCurrentBin3Value 7 "INVALID_LIGHTCLASS" 4 "LIGHTCLASS_4" 3 "LIGHTCLASS_3" 2 "LIGHTCLASS_2" 1 "LIGHTCLASS_1" 0 "LIGHTCLASS_SNA" ;
VAL_ 1801 VC_hcmlCurrentBin4Value 7 "INVALID_LIGHTCLASS" 4 "LIGHTCLASS_4" 3 "LIGHTCLASS_3" 2 "LIGHTCLASS_2" 1 "LIGHTCLASS_1" 0 "LIGHTCLASS_SNA" ;
VAL_ 1801 VC_hcmlCurrentBin5Value 7 "INVALID_LIGHTCLASS" 4 "LIGHTCLASS_4" 3 "LIGHTCLASS_3" 2 "LIGHTCLASS_2" 1 "LIGHTCLASS_1" 0 "LIGHTCLASS_SNA" ;
VAL_ 1801 VC_hcmlRegionAndSide 6 "HEADLAMP_REGION_AND_SIDE_ECE_RHD_RIGHT" 5 "HEADLAMP_REGION_AND_SIDE_ECE_RHD_LEFT" 4 "HEADLAMP_REGION_AND_SIDE_ECE_LHD_RIGHT" 3 "HEADLAMP_REGION_AND_SIDE_ECE_LHD_LEFT" 2 "HEADLAMP_REGION_AND_SIDE_SAE_RIGHT" 1 "HEADLAMP_REGION_AND_SIDE_SAE_LEFT" 0 "HEADLAMP_REGION_AND_SIDE_SNA" ;
VAL_ 1801 VC_hcmrFactoryOfOrigin 3 "HELLA_MEXICO" 2 "HELLA_SLOVAKIA" 1 "HELLA_CHINA" 0 "UNKNOWN" ;
VAL_ 1801 VC_hcmrHellaPartNumberStatus 1 "FAULT" 0 "OK" ;
VAL_ 1801 VC_hcmrCurrentBinMappingType 2 "BIN_MAP_TYPE_2" 1 "BIN_MAP_TYPE_1" 0 "BIN_MAP_TYPE_UNKNOWN" ;
VAL_ 1801 VC_hcmrCurrentBin0Value 7 "INVALID_LIGHTCLASS" 4 "LIGHTCLASS_4" 3 "LIGHTCLASS_3" 2 "LIGHTCLASS_2" 1 "LIGHTCLASS_1" 0 "LIGHTCLASS_SNA" ;
VAL_ 1801 VC_hcmrCurrentBin1Value 7 "INVALID_LIGHTCLASS" 4 "LIGHTCLASS_4" 3 "LIGHTCLASS_3" 2 "LIGHTCLASS_2" 1 "LIGHTCLASS_1" 0 "LIGHTCLASS_SNA" ;
VAL_ 1801 VC_hcmrCurrentBin2Value 7 "INVALID_LIGHTCLASS" 4 "LIGHTCLASS_4" 3 "LIGHTCLASS_3" 2 "LIGHTCLASS_2" 1 "LIGHTCLASS_1" 0 "LIGHTCLASS_SNA" ;
VAL_ 1801 VC_hcmrCurrentBin3Value 7 "INVALID_LIGHTCLASS" 4 "LIGHTCLASS_4" 3 "LIGHTCLASS_3" 2 "LIGHTCLASS_2" 1 "LIGHTCLASS_1" 0 "LIGHTCLASS_SNA" ;
VAL_ 1801 VC_hcmrCurrentBin4Value 7 "INVALID_LIGHTCLASS" 4 "LIGHTCLASS_4" 3 "LIGHTCLASS_3" 2 "LIGHTCLASS_2" 1 "LIGHTCLASS_1" 0 "LIGHTCLASS_SNA" ;
VAL_ 1801 VC_hcmrCurrentBin5Value 7 "INVALID_LIGHTCLASS" 4 "LIGHTCLASS_4" 3 "LIGHTCLASS_3" 2 "LIGHTCLASS_2" 1 "LIGHTCLASS_1" 0 "LIGHTCLASS_SNA" ;
VAL_ 1801 VC_hcmrRegionAndSide 6 "HEADLAMP_REGION_AND_SIDE_ECE_RHD_RIGHT" 5 "HEADLAMP_REGION_AND_SIDE_ECE_RHD_LEFT" 4 "HEADLAMP_REGION_AND_SIDE_ECE_LHD_RIGHT" 3 "HEADLAMP_REGION_AND_SIDE_ECE_LHD_LEFT" 2 "HEADLAMP_REGION_AND_SIDE_SAE_RIGHT" 1 "HEADLAMP_REGION_AND_SIDE_SAE_LEFT" 0 "HEADLAMP_REGION_AND_SIDE_SNA" ;
VAL_ 705 VCFRONT_logging10HzIndex 5 "END" 4 "EXV_TORQUE_COUNT" 3 "ACTIVE_LOUVER_RADAR" 2 "COMPRESSOR_REFRIGERANT_LOUVER" 1 "THERMAL_FAN_COOLANT_COMP" 0 "COOLANT_PUMPS_FAN" ;
VAL_ 897 VCFRONT_logging1HzIndex 27 "END" 26 "MISC_FIVE" 25 "MISC_FOUR" 24 "POWER_RATIONALITY_VCRIGHT" 23 "POWER_RATIONALITY_VCLEFT" 22 "SLEEP_WAKE" 21 "MISC_THREE" 20 "HSD_CURRENTS_2" 19 "HSD_CURRENTS_1" 18 "MISC_TWO" 17 "HP_PT_TARGETS" 16 "COOLANT_2" 15 "BODY_CONTROL" 14 "HP_MODE_OPTIONS_AND_ESTIMATES" 13 "HP_MODE_SELECT_AND_ESTIMATES" 12 "HP_ARBITRATION" 11 "HP_PRESSURE_CONTROL" 10 "HP_TEMPS_AND_DEMANDS" 9 "HP_DISSIPATION_AND_POWER" 8 "HP_EXV_CALIBRATION" 7 "HP_CYCLE_MODEL" 6 "HP_CONTROL_LOOP_AND_STATE" 5 "HP_DATA_AND_ACCUMULATORS" 4 "HP_EXV_RANGE" 3 "MISC_ONE" 2 "COOLANT_VALVE" 1 "FAN_DEMAND_CONDENSER_AND_FET_TEMPS" 0 "COOLANT" ;
VAL_ 897 VCFRONT_modeTransitionID 54 "SER_14_apInletOvertemp" 53 "ENTER_AMBIENTSOURCE_DRIVERLESS_SELF_TEST" 52 "SER_13_driverlessSelfTestActive" 51 "ENTER_SERIES_COP1" 50 "PAR_13_charge_battNeedsActiveCooling" 49 "SER_12_charge_battNeedsCooling" 48 "PAR_12_drive_cabinOverheatProtectActive" 47 "PAR_11_batteryDischarge" 46 "SER_11_service_highCoolantFlowReq" 45 "PAR_10_charge_battNearPassiveTarget" 44 "PAR_9_FC_battAboveHotStagnationTemp" 43 "PAR_8_FC_battNeedsActiveCooling_evapEnabled" 42 "PAR_7_FC_battNeedsActiveCooling_evapDisabled" 41 "PAR_6_drive_battAboveHotStagnationTemp" 40 "PAR_5_drive_cannotPassivelyCoolBatt" 39 "PAR_4_drive_chillerPassivelyCoolsBatt" 38 "PAR_3_drive_ptNeedsActiveCooling" 37 "PAR_2_drive_battNeedsActiveCooling_evapDisabled" 36 "PAR_1_drive_battNeedsActiveCooling_evapEnabled" 35 "SER_10_charge_battBelowPassiveTarget" 34 "SER_9_FC_battNeedsActiveCooling_evapEnabled" 33 "SER_8_FC_battNeedsActiveCooling_evapDisabled" 32 "SER_7_FC_battHeatingNeeded" 31 "SER_6_drive_battBelowPassiveOrNeedsHeat" 30 "SER_5_drive_radPassivelyCoolsBatt" 29 "SER_4_drive_chillerPassivelyCools" 28 "SER_3_drive_battBelowHotStagnationTemp" 27 "SER_2_drive_battNeedsActiveCooling_evapDisabled" 26 "SER_1_drive_battNeedsActiveCooling_evapEnabled" 25 "EXIT_AMBIENTSOURCE" 24 "ENTER_AMBIENTSOURCE" 23 "UNDEFINED" 22 "OVERRIDE" 21 "INIT" 20 "PARALLEL_10_batteryDischarge" 19 "PARALLEL_9_drive_batteryThermalLimiting" 18 "SERIES_9_drive_driveUnitThermalLimiting" 17 "SERIES_8_preConditioning_batteryNeedsHeat" 16 "PARALLEL_8_fastCharge_batteryWantsHeat" 15 "PARALLEL_7_fastCharge_batteryWantsCool" 14 "SERIES_7_fastCharge_batteryWantsCool" 13 "SERIES_6_fastCharge_batteryNeedsHeat" 12 "PARALLEL_6_charge_batteryWantsCool" 11 "PARALLEL_5_charge_batteryWantsHeat" 10 "SERIES_5_charge_batteryWantsHeat" 9 "SERIES_4_charge_batteryNeedsHeat" 8 "PARALLEL_4_drive_batteryNeedsCool" 7 "PARALLEL_3_drive_batteryWantsCool" 6 "PARALLEL_2_drive_batteryWantsHeat" 5 "SERIES_3_drive_batteryWantsHeat" 4 "SERIES_2_drive_batteryNeedsHeat" 3 "SERIES_1_drive_batteryWantsCool" 2 "SERIES_F3_faultTempSensors" 1 "SERIES_F2_faultPumps" 0 "PARALLEL_F1_noFlowRequest" ;
VAL_ 897 VCFRONT_modeDesired 3 "AMBIENT_SOURCE" 2 "BLEND" 1 "PARALLEL" 0 "SERIES" ;
VAL_ 897 VCFRONT_tempRefrigSuction 255 "SNA" ;
VAL_ 897 VCFRONT_pumpBatteryFETTemp 255 "SNA" ;
VAL_ 897 VCFRONT_pumpPowertrainFETTemp 255 "SNA" ;
VAL_ 897 VCFRONT_radiatorFanFETTemp 255 "SNA" ;
VAL_ 897 VCFRONT_radiatorFanRunReason 13 "FACTORY_NO_COOLANT" 12 "DRIVERLESS_SELF_TEST" 11 "BATTERY_DISCHARGE" 10 "DI_BURN_IN" 9 "RAD_CLEAR" 8 "UDS" 7 "MIN_ON_NVH" 6 "MIN_ON_GLOBAL" 5 "COAST_MODE" 4 "HEAT_PUMP" 3 "NVH_MASKING" 2 "AMBIENT_SNIFF" 1 "ACTIVE_MANAGER" 0 "NONE" ;
VAL_ 897 VCFRONT_coolantTempBasedMode 3 "AMBIENT_SOURCE" 2 "BLEND" 1 "PARALLEL" 0 "SERIES" ;
VAL_ 897 VCFRONT_coolantValveRecalReason 6 "NVRAM_LOSS" 5 "MOTOR_FEEDBACK_INTERRUPTED" 4 "SELF_TEST" 3 "CALIBRATION_FAULT_NO_TRAVEL" 2 "GENERAL_FAULT" 1 "MAX_TRAVEL" 0 "UNDEFINED" ;
VAL_ 897 VCFRONT_coolantValveCountRange 1023 "SNA" ;
VAL_ 897 VCFRONT_coolantValveRadBypass 127 "SNA" ;
VAL_ 897 VCFRONT_hpChargeCableType 2 "AC_CHARGER_PRESENT" 1 "DC_CHARGER_PRESENT" 0 "NO_CHARGER_PRESENT" ;
VAL_ 897 VCFRONT_tempSuperheatActual 1023 "SNA" ;
VAL_ 897 VCFRONT_refCommissionStatus 2 "REFRIGERANT_COMMISSIONED" 1 "REFRIGERANT_UNCOMMISSIONED" 0 "REFRIGERANT_UNKNOWN" ;
VAL_ 897 VCFRONT_passiveCoolingState 3 "CannotCoolBattery" 2 "ChillerAndRadCoolSeriesLoop" 1 "ChillerCoolsParallelBattLoop" 0 "ChillerCoolsSeriesLoop" ;
VAL_ 897 VCFRONT_hpRefrigerantPurgeState 2 "COMPLETE" 1 "EVAP_PURGE" 0 "IDLE" ;
VAL_ 897 VCFRONT_chillerEXVControlState 5 "PARKED" 4 "CALIBRATING_TIMEOUT" 3 "CALIBRATING" 2 "DISCHARGE" 1 "ACTIVE" 0 "INIT" ;
VAL_ 897 VCFRONT_evapEXVControlState 5 "PARKED" 4 "CALIBRATING_TIMEOUT" 3 "CALIBRATING" 2 "DISCHARGE" 1 "ACTIVE" 0 "INIT" ;
VAL_ 897 VCFRONT_recircEXVControlState 5 "PARKED" 4 "CALIBRATING_TIMEOUT" 3 "CALIBRATING" 2 "DISCHARGE" 1 "ACTIVE" 0 "INIT" ;
VAL_ 897 VCFRONT_lccEXVControlState 5 "PARKED" 4 "CALIBRATING_TIMEOUT" 3 "CALIBRATING" 2 "DISCHARGE" 1 "ACTIVE" 0 "INIT" ;
VAL_ 897 VCFRONT_cclEXVControlState 5 "PARKED" 4 "CALIBRATING_TIMEOUT" 3 "CALIBRATING" 2 "DISCHARGE" 1 "ACTIVE" 0 "INIT" ;
VAL_ 897 VCFRONT_ccrEXVControlState 5 "PARKED" 4 "CALIBRATING_TIMEOUT" 3 "CALIBRATING" 2 "DISCHARGE" 1 "ACTIVE" 0 "INIT" ;
VAL_ 897 VCFRONT_tempRefrigLiquid 2047 "SNA" ;
VAL_ 897 VCFRONT_radBypassMoveReason 11 "DRIVERLESS_SELF_TEST" 10 "HEATPUMP" 9 "UDS" 8 "EXIT_SERIES" 7 "ACTIVE_BATT_UNBYPASS" 6 "ACTIVE_PT_UNBYPASS" 5 "RAD_HEAT_UNBYPASS" 4 "RAD_HEAT_BYPASS" 3 "PASSIVE_BYPASS" 2 "PASSIVE_UNBYPASS" 1 "INIT_BYPASS" 0 "INIT_UNBYPASS" ;
VAL_ 897 VCFRONT_tempCoolantRadOutletEstS 3 "TEMP_ESTIMATE_HIGH_CONFIDENCE" 2 "TEMP_ESTIMATE_HIGH_CONFIDENCE_OVERPREDICT" 1 "TEMP_ESTIMATE_LOW_CONFIDENCE" 0 "TEMP_ESTIMATE_INVALID" ;
VAL_ 897 VCFRONT_targetBatActiveCoolSourc 7 "OVERRIDE" 6 "DIR" 5 "DIF" 4 "LCC" 3 "PCS" 2 "DAS" 1 "UI" 0 "BMS" ;
VAL_ 897 VCFRONT_targetPTActiveCoolSource 7 "OVERRIDE" 6 "DIR" 5 "DIF" 4 "LCC" 3 "PCS" 2 "DAS" 1 "UI" 0 "BMS" ;
VAL_ 897 VCFRONT_louverPosReason 11 "DRIVERLESS_SELF_TEST" 10 "BATTERY_DISCHARGE" 9 "HIGH_SPEED" 8 "UDS" 7 "COAST_MODE" 6 "FAN_FAULT" 5 "FAN_RUN" 4 "BOUNDS_CHECK" 3 "SNIFFING" 2 "PASSIVE_MANAGER" 1 "CONDENSOR_MANAGER" 0 "NONE" ;
VAL_ 897 VCFRONT_chargeShuttleType 3 "CHARGE_SHUTTLE_COP1" 2 "CHARGE_SHUTTLE_LCCR" 1 "CHARGE_SHUTTLE_STANDARD" 0 "CHARGE_SHUTTLE_NONE" ;
VAL_ 897 VCFRONT_tempRefrigDischarge 2047 "SNA" ;
VAL_ 897 VCFRONT_pumpBatteryRPMTarget 255 "SNA" ;
VAL_ 897 VCFRONT_pumpPowertrainRPMTarget 255 "SNA" ;
VAL_ 897 VCFRONT_radiatorFanRPMTarget 255 "SNA" ;
VAL_ 897 VCFRONT_ambientTempState 3 "SNIFFING" 2 "LATCHED" 1 "MEASUREING" 0 "INIT" ;
VAL_ 897 VCFRONT_ambientTempUnlatchReason 6 "SNIFF_STARTDRIVE" 5 "SNIFF_BLOCKED" 4 "SNIFF_TIMEBASED" 3 "LOUVERS_CLOSED" 2 "FAN_AIRFLOW" 1 "VEHICLE_SPEED" 0 "NONE" ;
VAL_ 513 VCFRONT_loggingAndVitals10HzInde 4 "END" 3 "EXV_FLOW_TARGET" 2 "EXV_FLOW" 1 "STATES_AND_SENSORS" 0 "TARGETS_AND_ACTUALS_0" ;
VAL_ 513 VCFRONT_pumpBatteryRPMActual 255 "SNA" ;
VAL_ 513 VCFRONT_pumpPowertrainRPMActual 255 "SNA" ;
VAL_ 513 VCFRONT_radiatorFanRPMActual 255 "SNA" ;
VAL_ 513 VCFRONT_pressureRefrigLiquid 511 "SNA" ;
VAL_ 513 VCFRONT_compressorState 3 "FAULT" 2 "RUNNING" 1 "READY" 0 "STANDBY" ;
VAL_ 513 VCFRONT_exvState 10 "INIT_CLOSE_OVERDRIVE" 9 "CALIB_CLOSE_OVERDRIVE" 8 "CALIB_CLOSE" 7 "READY_SHUT" 6 "OVERDRIVING_SHUT" 5 "WAIT" 4 "FAULTED" 3 "READY" 2 "INIT_CLOSE" 1 "INIT_OPEN" 0 "UNINIT" ;
VAL_ 513 VCFRONT_solenoidEvapState 3 "SOLENOID_FAULTED" 2 "SOLENOID_CLOSED" 1 "SOLENOID_OPENED" 0 "SOLENOID_UNDEFINED" ;
VAL_ 513 VCFRONT_coolantValveMode 3 "AMBIENT_SOURCE" 2 "BLEND" 1 "PARALLEL" 0 "SERIES" ;
VAL_ 513 VCFRONT_compFaultSeverity 3 "HIGH" 2 "MEDIUM" 1 "LOW" 0 "NONE" ;
VAL_ 513 VCFRONT_hpHighSideHX 3 "hpHighSideHX_BOTH" 2 "hpHighSideHX_CC" 1 "hpHighSideHX_LCC" 0 "hpHighSideHX_NONE" ;
VAL_ 513 VCFRONT_hpLowSideHX 3 "hpLowSideHX_BOTH" 2 "hpLowSideHX_EVAP" 1 "hpLowSideHX_CHILLER" 0 "hpLowSideHX_NONE" ;
VAL_ 513 VCFRONT_hpDominantLoad 6 "hpDominantLoad_HIGH_BOTH" 5 "hpDominantLoad_CC" 4 "hpDominantLoad_LCC" 3 "hpDominantLoad_LOW_BOTH" 2 "hpDominantLoad_CHILLER" 1 "hpDominantLoad_EVAP" 0 "hpDominantLoad_NONE" ;
VAL_ 513 VCFRONT_hpBlendType 2 "HP_FULL" 1 "HP_PARTIAL" 0 "HP_NONE" ;
VAL_ 513 VCFRONT_hpCabinLoadType 3 "hpCabinLoadType_EVAP" 2 "hpCabinLoadType_REHEAT" 1 "hpCabinLoadType_CC" 0 "hpCabinLoadType_NONE" ;
VAL_ 513 VCFRONT_hpBatteryLoadType 2 "BATT_COOL" 1 "BATT_HEAT" 0 "NONE" ;
VAL_ 513 VCFRONT_hpReqCoolantMode 4 "AMBIENT_SOURCE" 3 "PARALLEL" 2 "SERIES_BYPASS" 1 "SERIES_NO_BYPASS" 0 "ANY" ;
VAL_ 513 VCFRONT_compLiqPumpOutState 5 "COMP_LIQ_PUMP_OUT_ABORTED" 4 "COMP_LIQ_PUMP_OUT_COMPLETED" 3 "COMP_LIQ_PUMP_OUT_RUNNING" 2 "COMP_LIQ_PUMP_OUT_ALLOWED" 1 "COMP_LIQ_PUMP_OUT_WAITING" 0 "COMP_LIQ_PUMP_OUT_NOT_ALLOWED" ;
VAL_ 513 VCFRONT_frunkStateDBG 12 "FRUNK_STATE_FAULT_RELEASED" 11 "FRUNK_STATE_RESETTING" 10 "FRUNK_STATE_RELEASING_EXTENDING_2" 9 "FRUNK_STATE_RELEASING_RETRACTING_2" 8 "FRUNK_STATE_RELEASING_EXTENDING_1" 7 "FRUNK_STATE_RELEASING_RETRACTING_1" 6 "FRUNK_STATE_FAULT_CLOSED" 5 "FRUNK_STATE_FAULT_OPENED" 4 "FRUNK_STATE_FAULT" 3 "FRUNK_STATE_AJAR" 2 "FRUNK_STATE_OPENED" 1 "FRUNK_STATE_CLOSED" 0 "FRUNK_STATE_INIT" ;
VAL_ 513 VCFRONT_frunkSwitchGroupState 3 "FRUNKSWITCH_GROUP_CLOSED" 2 "FRUNKSWITCH_GROUP_OPENED" 1 "FRUNKSWITCH_GROUP_MISMATCHED" 0 "FRUNKSWITCH_GROUP_UNKNOWN" ;
VAL_ 513 VCFRONT_chillerExvState 10 "INIT_CLOSE_OVERDRIVE" 9 "CALIB_CLOSE_OVERDRIVE" 8 "CALIB_CLOSE" 7 "READY_SHUT" 6 "OVERDRIVING_SHUT" 5 "WAIT" 4 "FAULTED" 3 "READY" 2 "INIT_CLOSE" 1 "INIT_OPEN" 0 "UNINIT" ;
VAL_ 513 VCFRONT_evapExvState 10 "INIT_CLOSE_OVERDRIVE" 9 "CALIB_CLOSE_OVERDRIVE" 8 "CALIB_CLOSE" 7 "READY_SHUT" 6 "OVERDRIVING_SHUT" 5 "WAIT" 4 "FAULTED" 3 "READY" 2 "INIT_CLOSE" 1 "INIT_OPEN" 0 "UNINIT" ;
VAL_ 513 VCFRONT_recircExvState 10 "INIT_CLOSE_OVERDRIVE" 9 "CALIB_CLOSE_OVERDRIVE" 8 "CALIB_CLOSE" 7 "READY_SHUT" 6 "OVERDRIVING_SHUT" 5 "WAIT" 4 "FAULTED" 3 "READY" 2 "INIT_CLOSE" 1 "INIT_OPEN" 0 "UNINIT" ;
VAL_ 513 VCFRONT_lccExvState 10 "INIT_CLOSE_OVERDRIVE" 9 "CALIB_CLOSE_OVERDRIVE" 8 "CALIB_CLOSE" 7 "READY_SHUT" 6 "OVERDRIVING_SHUT" 5 "WAIT" 4 "FAULTED" 3 "READY" 2 "INIT_CLOSE" 1 "INIT_OPEN" 0 "UNINIT" ;
VAL_ 513 VCFRONT_cclExvState 10 "INIT_CLOSE_OVERDRIVE" 9 "CALIB_CLOSE_OVERDRIVE" 8 "CALIB_CLOSE" 7 "READY_SHUT" 6 "OVERDRIVING_SHUT" 5 "WAIT" 4 "FAULTED" 3 "READY" 2 "INIT_CLOSE" 1 "INIT_OPEN" 0 "UNINIT" ;
VAL_ 513 VCFRONT_ccrExvState 10 "INIT_CLOSE_OVERDRIVE" 9 "CALIB_CLOSE_OVERDRIVE" 8 "CALIB_CLOSE" 7 "READY_SHUT" 6 "OVERDRIVING_SHUT" 5 "WAIT" 4 "FAULTED" 3 "READY" 2 "INIT_CLOSE" 1 "INIT_OPEN" 0 "UNINIT" ;
VAL_ 801 VCFRONT_tempCoolantBatInlet 1023 "SNA" ;
VAL_ 801 VCFRONT_tempCoolantPTInlet 2047 "SNA" ;
VAL_ 801 VCFRONT_coolantLevel 1 "FILLED" 0 "NOT_OK" ;
VAL_ 801 VCFRONT_brakeFluidLevel 2 "NORMAL" 1 "LOW" 0 "SNA" ;
VAL_ 801 VCFRONT_tempAmbient 0 "SNA" ;
VAL_ 801 VCFRONT_washerFluidLevel 2 "NORMAL" 1 "LOW" 0 "SNA" ;
VAL_ 801 VCFRONT_tempAmbientFiltered 0 "SNA" ;
VAL_ 1349 VCFRONT_systemStatusMuxIndex 2 "LOAD_SHED_STATUSES_AND_COMMANDS" 1 "ACTIVE_LOAD_SHED_REASONS" 0 "SYSTEM_DATA" ;
VAL_ 1349 VCFRONT_loadShedReason 256 "VCFRONT_LOAD_SHED_REASON_LV_HEALTH" 128 "VCFRONT_LOAD_SHED_REASON_PRECHARGE" 64 "VCFRONT_LOAD_SHED_REASON_CUSTOM" 32 "VCFRONT_LOAD_SHED_REASON_FACTORY" 16 "VCFRONT_LOAD_SHED_REASON_HV_FAULT" 8 "VCFRONT_LOAD_SHED_REASON_POST_CRASH" 4 "VCFRONT_LOAD_SHED_REASON_VCRIGHT_EFUSE_PROTECTION" 2 "VCFRONT_LOAD_SHED_REASON_VCLEFT_EFUSE_PROTECTION" 1 "VCFRONT_LOAD_SHED_REASON_DCDC_SATURATION" 0 "VCFRONT_LOAD_SHED_REASON_NONE" ;
VAL_ 1349 VCFRONT_VCRightEFuseLoadShedStag 31 "MAX" 0 "IDLE" ;
VAL_ 1349 VCFRONT_VCLeftEFuseLoadShedStage 31 "MAX" 0 "IDLE" ;
VAL_ 1349 VCFRONT_DCDCSaturationLoadShedSt 31 "MAX" 0 "IDLE" ;
VAL_ 1349 VCFRONT_vehicleLoadShedStage 3 "VEHICLE_LOADSHEDDING_STAGE_3" 2 "VEHICLE_LOADSHEDDING_STAGE_2" 1 "VEHICLE_LOADSHEDDING_STAGE_1" 0 "VEHICLE_LOADSHEDDING_STAGE_IDLE_OR_UNDEFINED" ;
VAL_ 1349 VCFRONT_HVFaultLoadShedStateDBG 3 "HV_FAULT_LOADSHED_SM_STATE_ACTIVE" 2 "HV_FAULT_LOADSHED_SM_STATE_BLOCKED" 1 "HV_FAULT_LOADSHED_SM_STATE_IDLE" 0 "HV_FAULT_LOADSHED_SM_STATE_INIT" ;
VAL_ 929 VCFRONT_vehicleStatusMuxIndex 1 "MUX1" 0 "MUX0" ;
VAL_ 929 VCFRONT_APGlassHeaterState 4 "HEATER_STATE_FAULT" 3 "HEATER_STATE_OFF_UNAVAILABLE" 2 "HEATER_STATE_OFF" 1 "HEATER_STATE_ON" 0 "HEATER_STATE_SNA" ;
VAL_ 929 VCFRONT_thermalSystemType 1 "HEAT_PUMP_THERMAL_SYSTEM" 0 "LEGACY_THERMAL_SYSTEM" ;
VAL_ 929 VCFRONT_diPowerOnState 5 "DI_POWERED_ON_FOR_WINCH" 4 "DI_POWER_GOING_DOWN" 3 "DI_POWERED_ON_FOR_DRIVE" 2 "DI_POWERED_ON_FOR_STATIONARY_HEAT" 1 "DI_POWERED_ON_FOR_SUMMON" 0 "DI_POWERED_OFF" ;
VAL_ 929 VCFRONT_12vStatusForDrive 2 "EXIT_DRIVE_REQUESTED_12V" 1 "READY_FOR_DRIVE_12V" 0 "NOT_READY_FOR_DRIVE_12V" ;
VAL_ 929 VC_userPresenceState 3 "TIMED_OUT" 2 "PRESENT" 1 "NOT_PRESENT" 0 "INIT" ;
VAL_ 929 VCFRONT_driverBuckleStatus 1 "BUCKLED" 0 "UNBUCKLED" ;
VAL_ 929 VCFRONT_driverDoorStatus 1 "DOOR_CLOSED" 0 "DOOR_OPEN" ;
VAL_ 929 VCFRONT_driverUnbuckled 2 "CHIME_SNA" 1 "CHIME_OCCUPIED_AND_UNBUCKLED" 0 "CHIME_NONE" ;
VAL_ 929 VCFRONT_passengerUnbuckled 2 "CHIME_SNA" 1 "CHIME_OCCUPIED_AND_UNBUCKLED" 0 "CHIME_NONE" ;
VAL_ 929 VCFRONT_2RowLeftUnbuckled 2 "CHIME_SNA" 1 "CHIME_OCCUPIED_AND_UNBUCKLED" 0 "CHIME_NONE" ;
VAL_ 929 VCFRONT_2RowCenterUnbuckled 2 "CHIME_SNA" 1 "CHIME_OCCUPIED_AND_UNBUCKLED" 0 "CHIME_NONE" ;
VAL_ 929 VCFRONT_2RowRightUnbuckled 2 "CHIME_SNA" 1 "CHIME_OCCUPIED_AND_UNBUCKLED" 0 "CHIME_NONE" ;
VAL_ 929 VCFRONT_pcsEFuseVoltage 1023 "SNA" ;
VAL_ 929 VCFRONT_3RowLeftUnbuckled 2 "CHIME_SNA" 1 "CHIME_OCCUPIED_AND_UNBUCKLED" 0 "CHIME_NONE" ;
VAL_ 929 VCFRONT_3RowRightUnbuckled 2 "CHIME_SNA" 1 "CHIME_OCCUPIED_AND_UNBUCKLED" 0 "CHIME_NONE" ;
VAL_ 507 VCLEFT_TLCStatusIndex 2 "INVALID" 1 "1" 0 "0" ;
VAL_ 507 VCLEFT_TLCTemperature -128 "SNA" ;
VAL_ 507 VCLEFT_TLCLeftTurnVoltage 255 "SNA" ;
VAL_ 507 VCLEFT_TLCRightTurnVoltage 255 "SNA" ;
VAL_ 507 VCLEFT_TLCState_LeftTurn 5 "VCLEFT_TLC_LIGHT_STATE_SNA" 4 "VCLEFT_TLC_LIGHT_STATE_FAULT" 3 "VCLEFT_TLC_LIGHT_STATE_ON_WITH_LOAD" 2 "VCLEFT_TLC_LIGHT_STATE_ON_WITHOUT_LOAD" 1 "VCLEFT_TLC_LIGHT_STATE_OFF_WITH_LOAD" 0 "VCLEFT_TLC_LIGHT_STATE_OFF_WITHOUT_LOAD" ;
VAL_ 507 VCLEFT_TLCState_RightTurn 5 "VCLEFT_TLC_LIGHT_STATE_SNA" 4 "VCLEFT_TLC_LIGHT_STATE_FAULT" 3 "VCLEFT_TLC_LIGHT_STATE_ON_WITH_LOAD" 2 "VCLEFT_TLC_LIGHT_STATE_ON_WITHOUT_LOAD" 1 "VCLEFT_TLC_LIGHT_STATE_OFF_WITH_LOAD" 0 "VCLEFT_TLC_LIGHT_STATE_OFF_WITHOUT_LOAD" ;
VAL_ 507 VCLEFT_TLCState_Tail 5 "VCLEFT_TLC_LIGHT_STATE_SNA" 4 "VCLEFT_TLC_LIGHT_STATE_FAULT" 3 "VCLEFT_TLC_LIGHT_STATE_ON_WITH_LOAD" 2 "VCLEFT_TLC_LIGHT_STATE_ON_WITHOUT_LOAD" 1 "VCLEFT_TLC_LIGHT_STATE_OFF_WITH_LOAD" 0 "VCLEFT_TLC_LIGHT_STATE_OFF_WITHOUT_LOAD" ;
VAL_ 507 VCLEFT_TLCState_Stop 5 "VCLEFT_TLC_LIGHT_STATE_SNA" 4 "VCLEFT_TLC_LIGHT_STATE_FAULT" 3 "VCLEFT_TLC_LIGHT_STATE_ON_WITH_LOAD" 2 "VCLEFT_TLC_LIGHT_STATE_ON_WITHOUT_LOAD" 1 "VCLEFT_TLC_LIGHT_STATE_OFF_WITH_LOAD" 0 "VCLEFT_TLC_LIGHT_STATE_OFF_WITHOUT_LOAD" ;
VAL_ 507 VCLEFT_TLCState_Fog 5 "VCLEFT_TLC_LIGHT_STATE_SNA" 4 "VCLEFT_TLC_LIGHT_STATE_FAULT" 3 "VCLEFT_TLC_LIGHT_STATE_ON_WITH_LOAD" 2 "VCLEFT_TLC_LIGHT_STATE_ON_WITHOUT_LOAD" 1 "VCLEFT_TLC_LIGHT_STATE_OFF_WITH_LOAD" 0 "VCLEFT_TLC_LIGHT_STATE_OFF_WITHOUT_LOAD" ;
VAL_ 507 VCLEFT_TLCState_Reverse 5 "VCLEFT_TLC_LIGHT_STATE_SNA" 4 "VCLEFT_TLC_LIGHT_STATE_FAULT" 3 "VCLEFT_TLC_LIGHT_STATE_ON_WITH_LOAD" 2 "VCLEFT_TLC_LIGHT_STATE_ON_WITHOUT_LOAD" 1 "VCLEFT_TLC_LIGHT_STATE_OFF_WITH_LOAD" 0 "VCLEFT_TLC_LIGHT_STATE_OFF_WITHOUT_LOAD" ;
VAL_ 290 VCLEFT_doorStatus2Index 1 "MUX1" 0 "MUX0" ;
VAL_ 290 VCLEFT_BPillarCameraHeaterState 4 "HEATER_STATE_FAULT" 3 "HEATER_STATE_OFF_UNAVAILABLE" 2 "HEATER_STATE_OFF" 1 "HEATER_STATE_ON" 0 "HEATER_STATE_SNA" ;
VAL_ 290 VCLEFT_BPillarCameraHeaterCurren 63 "SNA" ;
VAL_ 626 VCLEFT_epbmDebugIndex 1 "TRANSITIONS" 0 "STATES" ;
VAL_ 626 VCLEFT_epbmCaliperState 6 "EPB_SAVED_CALIPERSTATE_WINCHMODE" 5 "EPB_SAVED_CALIPERSTATE_SERVICE" 4 "EPB_SAVED_CALIPERSTATE_OPEN" 3 "EPB_SAVED_CALIPERSTATE_PARK" 2 "EPB_SAVED_CALIPERSTATE_REAPPLY" 1 "EPB_SAVED_CALIPERSTATE_UNKNOWN" 0 "EPB_SAVED_CALIPERSTATE_UNSAVED" ;
VAL_ 626 VCLEFT_summonFaultReason 30 "EPB_SUMMONFAULT_MONITOR_TYPE_UNKNOWN" 29 "EPB_SUMMONFAULT_AP_MONITOR" 28 "EPB_SUMMONFAULT_REMOTE_DID_NOT_START" 27 "EPB_SUMMONFAULT_INVALID_REMOTE_STATE" 26 "EPB_SUMMONFAULT_START_IN_UNAVAILABLE" 25 "EPB_SUMMONFAULT_REMOTE_UNIT_FAULTED" 24 "EPB_SUMMONFAULT_LOCAL_UNIT_FAULTED" 23 "EPB_SUMMONFAULT_REMOTE_SUMMON_FAULTED" 22 "EPB_SUMMONFAULT_EPBREMOTE_MIA" 21 "EPB_SUMMONFAULT_PASSIVE_REQUEST" 20 "EPB_SUMMONFAULT_DI_STATE_INVALID" 19 "EPB_SUMMONFAULT_EPB_FAULT" 18 "EPB_SUMMONFAULT_MISMATCH" 17 "EPB_SUMMONFAULT_OOC" 16 "EPB_SUMMONFAULT_PM_REQUEST" 15 "EPB_SUMMONFAULT_PM_MIA" 14 "EPB_SUMMONFAULT_PARK_MIA" 13 "EPB_SUMMONFAULT_EXTERNAL" 12 "EPB_SUMMONFAULT_SPEED" 11 "EPB_SUMMONFAULT_EPBM_REQUEST" 10 "EPB_SUMMONFAULT_EAC_NOT_ALLOWED" 9 "EPB_SUMMONFAULT_VEH_CAN_FAULT" 8 "EPB_SUMMONFAULT_ESP_FAULT" 7 "EPB_SUMMONFAULT_DAS_FAULT" 6 "EPB_SUMMONFAULT_DI_APC_FAULT" 5 "EPB_SUMMONFAULT_DI_FAULT" 4 "EPB_SUMMONFAULT_EPBM_MIA" 3 "EPB_SUMMONFAULT_ESP_MIA" 2 "EPB_SUMMONFAULT_DAS_MIA" 1 "EPB_SUMMONFAULT_DI_MIA" 0 "EPB_SUMMONFAULT_NONE" ;
VAL_ 626 VCLEFT_epbSummonState 6 "EPB_SUMMON_UNAVAILABLE" 5 "EPB_SUMMON_FAULT" 4 "EPB_SUMMON_COMPLETE" 3 "EPB_SUMMON_ACTIVE" 2 "EPB_SUMMON_ARMED" 1 "EPB_SUMMON_IDLE" 0 "EPB_SUMMON_INIT" ;
VAL_ 626 VCLEFT_epbmSummonState 6 "EPB_SUMMON_UNAVAILABLE" 5 "EPB_SUMMON_FAULT" 4 "EPB_SUMMON_COMPLETE" 3 "EPB_SUMMON_ACTIVE" 2 "EPB_SUMMON_ARMED" 1 "EPB_SUMMON_IDLE" 0 "EPB_SUMMON_INIT" ;
VAL_ 626 VCLEFT_epbUnitStatus 23 "EPB_STATUS_COUNT" 22 "EPB_STATUS_AUTONOMY_OPEN" 21 "EPB_STATUS_FREE_ROLL_MODE" 20 "EPB_STATUS_DYNAMIC_PARKING" 19 "EPB_STATUS_EXTERNAL_PARKING" 18 "EPB_STATUS_RELEASING_FOR_EXTERNAL_PARK" 17 "EPB_STATUS_EXTERNAL_DYNAMIC" 16 "EPB_STATUS_SUMMON_PARKING" 15 "EPB_STATUS_SUMMON_RELEASING" 14 "EPB_STATUS_SUMMON" 13 "EPB_STATUS_WINCHMODE_PENDING" 12 "EPB_STATUS_PARK_PENDING" 11 "EPB_STATUS_SERVICE_RELEASING" 10 "EPB_STATUS_RELEASING" 9 "EPB_STATUS_DYNAMIC_APPLYING" 8 "EPB_STATUS_PARKING" 7 "EPB_STATUS_WINCHMODE_RELEASING" 6 "EPB_STATUS_WINCHMODE" 5 "EPB_STATUS_SERVICE" 4 "EPB_STATUS_START" 3 "EPB_STATUS_PARK" 2 "EPB_STATUS_DYNAMIC" 1 "EPB_STATUS_OPEN" 0 "EPB_STATUS_UNKNOWN" ;
VAL_ 626 VCLEFT_epbmFaultStatus 3 "EPB_STATUS_FAULT_IDLE" 2 "EPB_STATUS_FAULT" 1 "EPB_STATUS_RETRY" 0 "EPB_STATUS_NOMINAL" ;
VAL_ 626 VCLEFT_epbFaultStatus 3 "EPB_STATUS_FAULT_IDLE" 2 "EPB_STATUS_FAULT" 1 "EPB_STATUS_RETRY" 0 "EPB_STATUS_NOMINAL" ;
VAL_ 626 VCLEFT_epbmSystemStatus 8 "EPB_VEHICLE_STATUS_MISMATCH" 7 "EPB_VEHICLE_STATUS_FAULT_SECURE" 6 "EPB_VEHICLE_STATUS_FAULT" 5 "EPB_VEHICLE_STATUS_RELEASING" 4 "EPB_VEHICLE_STATUS_PARKING" 3 "EPB_VEHICLE_STATUS_DYNAMIC" 2 "EPB_VEHICLE_STATUS_PARKED" 1 "EPB_VEHICLE_STATUS_RELEASED" 0 "EPB_VEHICLE_STATUS_UNKNOWN" ;
VAL_ 626 VCLEFT_epbmAutonomyBehavior 2 "DRIVERLESS_NO_TAKEOVER" 1 "DRIVERLESS_TAKEOVER" 0 "DRIVER" ;
VAL_ 1186 VCLEFT_etcBluetoothStatus 3 "ETC_BLUETOOTH_STATE_RESERVED" 2 "ETC_BLUETOOTH_STATE_ON" 1 "ETC_BLUETOOTH_STATE_OFF" 0 "ETC_BLUETOOTH_STATE_INACTIVE" ;
VAL_ 642 VCLEFT_hvacBlowerFeedbackIndex 1 "END" 0 "HVAC_FEEDBACK_SIGNALS" ;
VAL_ 642 VCLEFT_hvacBlowerOutputDuty 127 "SNA" ;
VAL_ 642 VCLEFT_hvacBlowerRPMTarget 1023 "SNA" ;
VAL_ 642 VCLEFT_hvacBlowerTorque 1023 "SNA" ;
VAL_ 642 VCLEFT_hvacBlowerFETTemp 127 "SNA" ;
VAL_ 642 VCLEFT_hvacBlowerIDc 127 "SNA" ;
VAL_ 642 VCLEFT_hvacBlowerMotorID 2 "VC_MOTOR_ID_BOSCH" 1 "VC_MOTOR_ID_DELTA" 0 "VC_MOTOR_ID_UNKNOWN" ;
VAL_ 770 VCLEFT_infoIndex 255 "END" 41 "SUBCOMPONENT14" 40 "SUBCOMPONENT13" 39 "SUBCOMPONENT12" 38 "SUBCOMPONENT11" 37 "SUBCOMPONENT10" 36 "SUBCOMPONENT9" 35 "SUBCOMPONENT8" 34 "SUBCOMPONENT7" 33 "SUBCOMPONENT6" 32 "SUBCOMPONENT5" 31 "SUBCOMPONENT4" 24 "SUBCOMPONENT3" 23 "SUBCOMPONENT2" 20 "UDS_PROTOCOL_BOOTCRC" 19 "VERSION_DEPRECATED" 18 "BOOTLOADER_GITHASH" 17 "APP_GITHASH" 16 "SUBCOMPONENT1" 15 "BOOTLOADER_CRC" 14 "BOOTLOADER_SVN" 13 "APP_CRC" 11 "PCBAID_ASSYID_USAGEID" 10 "BUILD_HWID_COMPONENTID" 9 "DEPRECATED_9" 8 "DEPRECATED_8" 7 "DEPRECATED_7" 6 "DEPRECATED_6" 5 "DEPRECATED_5" 4 "DEPRECATED_4" 3 "DEPRECATED_3" 2 "DEPRECATED_2" 1 "DEPRECATED_1" 0 "DEPRECATED_0" ;
VAL_ 770 VCLEFT_infoBuildType 4 "INFO_MFG_BUILD" 3 "INFO_TRACEABLE_CI_BUILD" 2 "INFO_LOCAL_BUILD" 1 "INFO_PLATFORM_BUILD" 0 "INFO_UNKNOWN_BUILD" ;
VAL_ 770 VCLEFT_infoAssemblyId 255 "ASSEMBLY_SNA" 1 "ASSEMBLY1" ;
VAL_ 292 VCLEFT_liftgateRequestAction 18 "LIFTGATE_POSITION_ACTION_COUNT" 17 "LIFTGATE_POSITION_ACTION_FIXED_DUTY_LATCH_CURRENT_SCALED" 16 "LIFTGATE_POSITION_ACTION_FIXED_DUTY_LATCH_CURRENT" 15 "LIFTGATE_POSITION_ACTION_OPENING_BACKOFF" 14 "LIFTGATE_POSITION_ACTION_UPDATE_PARAM_CLOSING_SPEED" 13 "LIFTGATE_POSITION_ACTION_FACTORY_CLOSE" 12 "LIFTGATE_POSITION_ACTION_UNCAL_CLOSE" 11 "LIFTGATE_POSITION_ACTION_CLOSING_WHOOSH" 10 "LIFTGATE_POSITION_ACTION_CLOSING" 9 "LIFTGATE_POSITION_ACTION_PARTY_OPENING" 8 "LIFTGATE_POSITION_ACTION_OPENING_WHOOSH" 7 "LIFTGATE_POSITION_ACTION_OPENING_INIT_VEL" 6 "LIFTGATE_POSITION_ACTION_OPENING" 5 "LIFTGATE_POSITION_ACTION_RAMPED_DUTY_OFF" 4 "LIFTGATE_POSITION_ACTION_RAMPED_DUTY_LATCH_EXIT" 3 "LIFTGATE_POSITION_ACTION_RAMPED_DUTY_EOT" 2 "LIFTGATE_POSITION_ACTION_FIXED_DUTY_CLOSE" 1 "LIFTGATE_POSITION_ACTION_FIXED_DUTY_OPEN" 0 "LIFTGATE_POSITION_ACTION_IDLE" ;
VAL_ 292 VCLEFT_liftgateReqObsDetMode 5 "PLG_OBSTACLE_DETECT_MODE_PARTY_CLOSE" 4 "PLG_OBSTACLE_DETECT_MODE_LATCH_EXIT" 3 "PLG_OBSTACLE_DETECT_MODE_LATCH_ENTRY" 2 "PLG_OBSTACLE_DETECT_MODE_CLOSING" 1 "PLG_OBSTACLE_DETECT_MODE_OPENING" 0 "PLG_OBSTACLE_DETECT_MODE_INACTIVE" ;
VAL_ 322 VCLEFT_liftgateStatusIndex 2 "INVALID" 1 "1" 0 "0" ;
VAL_ 322 VCLEFT_liftgateState 13 "PLG_STATE_PARTY_DANCE" 12 "PLG_STATE_LATCH_ENTRY" 11 "PLG_STATE_END_OF_TRAVEL" 10 "PLG_STATE_LATCH_EXIT" 9 "PLG_STATE_UNKNOWN" 8 "PLG_STATE_NOT_INSTALLED" 7 "PLG_STATE_LATCH_CLOSING" 6 "PLG_STATE_LATCH_OPENING" 5 "PLG_STATE_CLOSED" 4 "PLG_STATE_CLOSING" 3 "PLG_STATE_OPENING" 2 "PLG_STATE_BACKOFF" 1 "PLG_STATE_OFF" 0 "PLG_STATE_INIT" ;
VAL_ 322 VCLEFT_liftgateStoppingCondition 13 "PLG_STOPPING_CONDITION_COUNT" 12 "PLG_STOPPING_CONDITION_FOLLOWER_REQUEST" 11 "PLG_STOPPING_CONDITION_OBSTACLE_CURRENT_SPIKE" 10 "PLG_STOPPING_CONDITION_LATCH_FAULT" 9 "PLG_STOPPING_CONDITION_UNCALIBRATED" 8 "PLG_STOPPING_CONDITION_OBSTACLE_TRAJ_VEL" 7 "PLG_STOPPING_CONDITION_OBSTACLE_TRAJ_POS" 6 "PLG_STOPPING_CONDITION_OBSTACLE_CURRENT" 5 "PLG_STOPPING_CONDITION_VEHICLE_AT_SPEED" 4 "PLG_STOPPING_CONDITION_STATE_TIMEOUT" 3 "PLG_STOPPING_CONDITION_LOW_12V" 2 "PLG_STOPPING_CONDITION_OBSTACLE_STALL" 1 "PLG_STOPPING_CONDITION_PINCH" 0 "PLG_STOPPING_CONDITION_NONE" ;
VAL_ 322 VCLEFT_liftgateMvmntNotAllowedCo 6 "PLG_MVMT_NOT_ALLOWED_STRUT_POSITION_MISMATCH" 5 "PLG_MVMT_NOT_ALLOWED_LOCKED" 4 "PLG_MVMT_NOT_ALLOWED_EXTERIOR_PRESS_AT_MAX_OPEN" 3 "PLG_MVMT_NOT_ALLOWED_UNCALIBRATED" 2 "PLG_MVMT_NOT_ALLOWED_VEHICLE_AT_SPEED" 1 "PLG_MVMT_NOT_ALLOWED_LOW_12V" 0 "PLG_MVMT_NOT_ALLOWED_NONE" ;
VAL_ 322 VCLEFT_liftgateUIChimeRequest 4 "REMOTE_CHIME_REQUEST_ONE_LONG" 3 "REMOTE_CHIME_REQUEST_THREE_SHORT" 2 "REMOTE_CHIME_REQUEST_TWO_SHORT" 1 "REMOTE_CHIME_REQUEST_ONE_SHORT" 0 "REMOTE_CHIME_REQUEST_NONE" ;
VAL_ 322 VCLEFT_liftgatePhysicalChimeRequ 4 "REMOTE_CHIME_REQUEST_ONE_LONG" 3 "REMOTE_CHIME_REQUEST_THREE_SHORT" 2 "REMOTE_CHIME_REQUEST_TWO_SHORT" 1 "REMOTE_CHIME_REQUEST_ONE_SHORT" 0 "REMOTE_CHIME_REQUEST_NONE" ;
VAL_ 322 VCLEFT_liftgateStaticStrutMode 5 "PLG_STATIC_STRUT_MODE_SLAM_BRAKE" 4 "PLG_STATIC_STRUT_MODE_OPEN_COAST" 3 "PLG_STATIC_STRUT_MODE_CLOSE_COAST" 2 "PLG_STATIC_STRUT_MODE_BRAKE_HOLD" 1 "PLG_STATIC_STRUT_MODE_OFF_COAST" 0 "PLG_STATIC_STRUT_MODE_UNKNOWN_SNA" ;
VAL_ 322 VCLEFT_liftgateRequestSource 9 "PLG_REQUEST_SOURCE_DAS" 8 "PLG_REQUEST_SOURCE_EMERG_RELEASE" 7 "PLG_REQUEST_SOURCE_UDS" 6 "PLG_REQUEST_SOURCE_PARTY" 5 "PLG_REQUEST_SOURCE_VCSEC_COMMAND" 4 "PLG_REQUEST_SOURCE_KEY_TRUNK_BUTTON" 3 "PLG_REQUEST_SOURCE_SHUTFACE" 2 "PLG_REQUEST_SOURCE_EXTERIOR" 1 "PLG_REQUEST_SOURCE_MCU_SWITCH" 0 "PLG_REQUEST_SOURCE_NONE" ;
VAL_ 322 VCLEFT_liftgateGeofenceState 3 "PLG_GEOFENCE_STATE_WAITING_TO_STOP" 2 "PLG_GEOFENCE_STATE_SETTING_HEIGHT" 1 "PLG_GEOFENCE_STATE_WAITING_TO_TRIGGER" 0 "PLG_GEOFENCE_STATE_INIT" ;
VAL_ 322 VCLEFT_liftgateLatchRequest 4 "LATCH_REQUEST_RESET" 3 "LATCH_REQUEST_FORCE_RELEASE" 2 "LATCH_REQUEST_RELEASE_V2" 1 "LATCH_REQUEST_CINCH" 0 "LATCH_REQUEST_NONE" ;
